VERSION ""

NS_ :

BS_:

BU_: APIM_CISM FCIMB RACM_RCIM DSP WCM DACMC HUD_ADV TRM_ITRM ACM GWM _delete APIM IPC GENERIC TSTR

BO_ 611 Driveline_Data_1_HS3: 8 GWM
 SG_ AwdTerrMdeChng_D_Rdy : 58|3@0+ (1,0) [0|7] "SED"  IPC
 SG_ AwdTerrMde_D_Actl : 50|3@0+ (1,0) [0|7] "SED"  IPC
 SG_ AwdSys_D_Stat : 27|2@0+ (1,0) [0|3] "SED"  IPC
 SG_ AwdStat_D_RqDsply : 63|5@0+ (1,0) [0|31] "SED"  IPC
 SG_ AwdLck_D_Stat : 31|4@0+ (1,0) [0|15] "SED"  IPC
 SG_ AwdSrvcRqd_B_Rq : 0|1@0+ (1,0) [0|1] "SED"  IPC
 SG_ AwdLck_Tq_Rq : 15|12@0+ (1,0) [0|4093] "Nm"  IPC
 SG_ TrnAout_Tq_RqMx : 47|13@0+ (1,-1250) [-1250|6941] "Nm"  IPC
 SG_ AwdOffRoadMode_D_Stats : 25|2@0+ (1,0) [0|3] "SED"  APIM_CISM,APIM,IPC
 SG_ AwdLoLamp_D_RqDsply : 35|2@0+ (1,0) [0|3] "SED"  IPC
 SG_ AwdHiLamp_D_RqDsply : 19|2@0+ (1,0) [0|3] "SED"  IPC
 SG_ AwdAutoLamp_D_RqDsply : 17|2@0+ (1,0) [0|3] "SED"  IPC
 SG_ Awd2wdLamp_D_RqDsply : 2|2@0+ (1,0) [0|3] "SED"  IPC
 SG_ AwdRnge_D_Actl : 7|3@0+ (1,0) [0|7] "SED"  APIM_CISM,ACM,APIM,IPC
 SG_ NtrlTowAvail_B_Stat : 4|1@0+ (1,0) [0|1] "SED"  IPC
 SG_ AwdDrvMde_D_Stat : 38|3@0+ (1,0) [0|7] "SED"  IPC
 SG_ SelDrvMdeAwd_D_Stat : 33|2@0+ (1,0) [0|3] "SED"  GENERIC

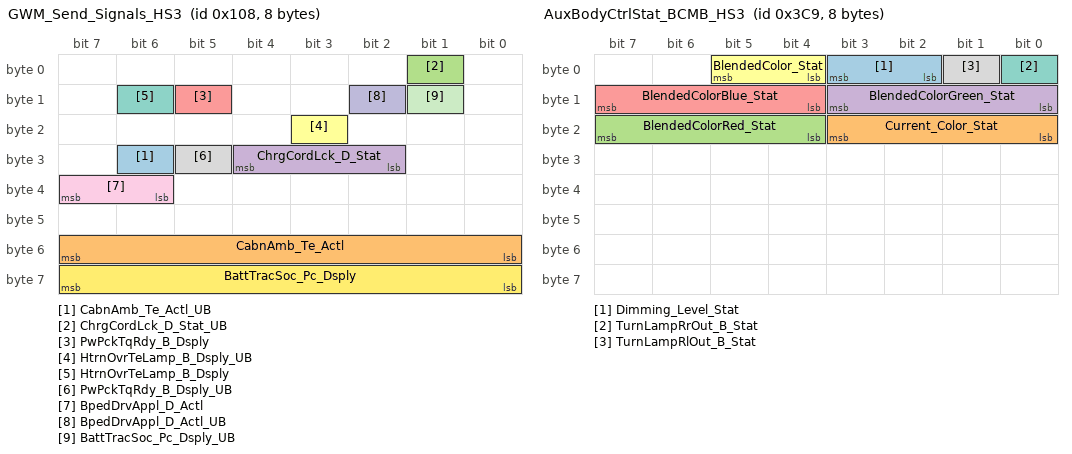
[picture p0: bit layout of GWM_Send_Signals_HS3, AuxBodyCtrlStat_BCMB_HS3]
BO_ 264 GWM_Send_Signals_HS3: 8 GWM
 SG_ CabnAmb_Te_Actl_UB : 30|1@0+ (1,0) [0|1] "SED"  WCM,ACM
 SG_ CabnAmb_Te_Actl : 55|8@0+ (0.5,-57) [-57|70] "degreesC"  WCM,ACM
 SG_ ChrgCordLck_D_Stat_UB : 1|1@0+ (1,0) [0|1] "SED"  APIM_CISM,APIM
 SG_ ChrgCordLck_D_Stat : 28|3@0+ (1,0) [0|7] "SED"  APIM_CISM,APIM
 SG_ PwPckTqRdy_B_Dsply : 13|1@0+ (1,0) [0|1] "SED"  APIM_CISM,APIM,IPC
 SG_ HtrnOvrTeLamp_B_Dsply_UB : 19|1@0+ (1,0) [0|1] "SED"  IPC
 SG_ HtrnOvrTeLamp_B_Dsply : 14|1@0+ (1,0) [0|1] "SED"  IPC
 SG_ PwPckTqRdy_B_Dsply_UB : 29|1@0+ (1,0) [0|1] "SED"  APIM_CISM,APIM,IPC
 SG_ BpedDrvAppl_D_Actl : 39|2@0+ (1,0) [0|3] "SED"  APIM_CISM,APIM,TRM_ITRM,IPC
 SG_ BpedDrvAppl_D_Actl_UB : 10|1@0+ (1,0) [0|1] "SED"  APIM_CISM,APIM,TRM_ITRM,IPC
 SG_ BattTracSoc_Pc_Dsply_UB : 9|1@0+ (1,0) [0|1] "SED"  APIM_CISM,HUD_ADV,APIM,IPC
 SG_ BattTracSoc_Pc_Dsply : 63|8@0+ (0.5,0) [0|126.5] "Percent"  APIM_CISM,HUD_ADV,APIM,IPC

BO_ 1114 TrailerAid_Data: 8 IPC
 SG_ TrailCtlSwtch_B_Stat2 : 16|1@0+ (1,0) [0|1] "SED"  GWM
 SG_ TrlBrkInitOut_D_Rq : 60|2@0+ (1,0) [0|3] "SED"  TRM_ITRM,GWM

BO_ 968 Cluster_Lighting_Rq: 8 IPC
 SG_ RvltnMatchAllw_D_Rq : 58|2@0+ (1,0) [0|3] "SED"  GWM
 SG_ BrkDrvMde_D_Rq : 18|3@0+ (1,0) [0|7] "SED"  GWM
 SG_ LnchCtl_N_Rq : 55|8@0+ (50,0) [0|12750] "rpm"  GWM
 SG_ LnchCtl_D_Rq : 63|2@0+ (1,0) [0|3] "SED"  GWM
 SG_ CurrentColor_CmdGage : 43|4@0+ (1,0) [0|15] "SED"  GWM
 SG_ BlendedColor_CmdGage : 25|2@0+ (1,0) [0|3] "SED"  GWM
 SG_ BlendColorRed_CmdGage : 47|4@0+ (1,0) [0|15] "SED"  GWM
 SG_ BlendColorGrn_CmdGage : 35|4@0+ (1,0) [0|15] "SED"  GWM
 SG_ BlendColorBlue_CmdGage : 39|4@0+ (1,0) [0|15] "SED"  GWM
 SG_ Dimming_Level_Cmd : 1|2@0+ (1,0) [0|3] "SED"  GWM
 SG_ Current_Color_Cmd : 23|4@0+ (1,0) [0|15] "SED"  GWM
 SG_ BlendedColorRed_Cmd : 11|4@0+ (1,0) [0|15] "SED"  GWM
 SG_ BlendedColorGreen_Cmd : 15|4@0+ (1,0) [0|15] "SED"  GWM
 SG_ BlendedColorBlue_Cmd : 5|4@0+ (1,0) [0|15] "SED"  GWM
 SG_ BlendedColor_Cmd : 7|2@0+ (1,0) [0|3] "SED"  GWM
 SG_ SuspDrvMde_D_Rq : 61|3@0+ (1,0) [0|7] "SED"  GWM
 SG_ SlMde_D_Rq : 27|2@0+ (1,0) [0|3] "SED"  GWM
 SG_ IsaOffst_D_Rq : 31|4@0+ (1,0) [0|15] "SED"  GWM

BO_ 969 AuxBodyCtrlStat_BCMB_HS3: 8 GWM
 SG_ Dimming_Level_Stat : 3|2@0+ (1,0) [0|3] "SED"  IPC
 SG_ Current_Color_Stat : 19|4@0+ (1,0) [0|15] "SED"  IPC
 SG_ BlendedColorRed_Stat : 23|4@0+ (1,0) [0|15] "SED"  IPC
 SG_ BlendedColorGreen_Stat : 11|4@0+ (1,0) [0|15] "SED"  IPC
 SG_ BlendedColorBlue_Stat : 15|4@0+ (1,0) [0|15] "SED"  IPC
 SG_ BlendedColor_Stat : 5|2@0+ (1,0) [0|3] "SED"  IPC
 SG_ TurnLampRrOut_B_Stat : 0|1@0+ (1,0) [0|1] "SED"  IPC
 SG_ TurnLampRlOut_B_Stat : 1|1@0+ (1,0) [0|1] "SED"  IPC

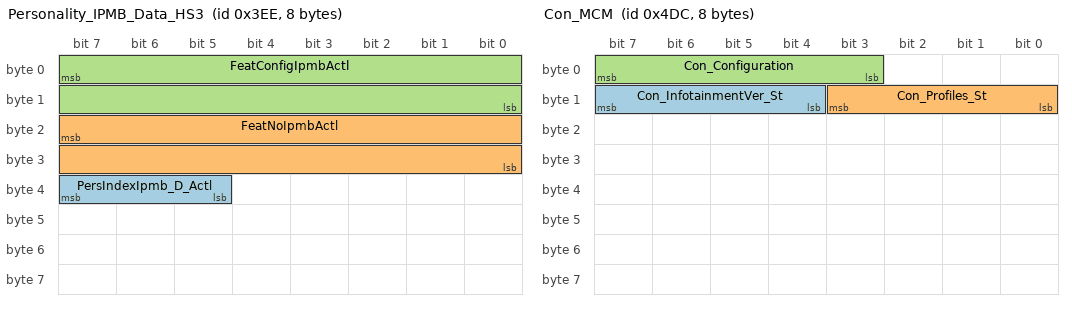
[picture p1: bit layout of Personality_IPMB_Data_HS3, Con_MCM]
BO_ 1006 Personality_IPMB_Data_HS3: 8 GWM
 SG_ PersIndexIpmb_D_Actl : 39|3@0+ (1,0) [0|7] "SED"  APIM_CISM,APIM,ACM
 SG_ FeatNoIpmbActl : 23|16@0+ (1,0) [0|65535] "Number"  APIM_CISM,APIM,ACM
 SG_ FeatConfigIpmbActl : 7|16@0+ (1,0) [0|65535] "Undefined"  APIM_CISM,APIM,ACM

BO_ 130 Steering_Wheel_Data2_HS3: 8 GWM
 SG_ SteWhlSwtchHome_B_Stat : 19|1@0+ (1,0) [0|1] "SED"  IPC
 SG_ SteWhlSwtchInfo_B_Stat : 18|1@0+ (1,0) [0|1] "SED"  IPC
 SG_ SelDrvMdeSwtch_D_Stat4 : 21|2@0+ (1,0) [0|3] "SED"  GENERIC
 SG_ SelDrvMdeSwtch3_D_Stat4 : 25|2@0+ (1,0) [0|3] "SED"  GENERIC
 SG_ SelDrvMdeSwtch2_D_Stat4 : 27|2@0+ (1,0) [0|3] "SED"  GENERIC
 SG_ SelDrvMdeSwtch1_D_Stat4 : 29|2@0+ (1,0) [0|3] "SED"  GENERIC
 SG_ PoliceAux4Swtch_B_Stat : 30|1@0+ (1,0) [0|1] "SED"  TRM_ITRM
 SG_ PoliceAux3Swtch_B_Stat : 31|1@0+ (1,0) [0|1] "SED"  TRM_ITRM
 SG_ PoliceAux2Swtch_B_Stat : 16|1@0+ (1,0) [0|1] "SED"  TRM_ITRM
 SG_ PoliceAux1Swtch_B_Stat : 17|1@0+ (1,0) [0|1] "SED"  TRM_ITRM
 SG_ SteWhlSwtchView_B_Stat : 23|1@0+ (1,0) [0|1] "SED"  IPC
 SG_ SteWhlSwtchSet_B_Stat : 8|1@0+ (1,0) [0|1] "SED"  IPC
 SG_ SteWhlSwtchPhon_B_Stat : 9|1@0+ (1,0) [0|1] "SED"  HUD_ADV,IPC
 SG_ SteWhlSwtchNav_B_Stat : 10|1@0+ (1,0) [0|1] "SED"  IPC
 SG_ SteWhlSwtchMed_B_Stat : 11|1@0+ (1,0) [0|1] "SED"  HUD_ADV,IPC
 SG_ SteWhlSwtchIod_B_Stat : 12|1@0+ (1,0) [0|1] "SED"  IPC
 SG_ SteWhlSwtchHud_B_Stat : 13|1@0+ (1,0) [0|1] "SED"  HUD_ADV,IPC
 SG_ SteWhlSwtchBack_B_Stat : 14|1@0+ (1,0) [0|1] "SED"  HUD_ADV,IPC
 SG_ SteWhlSwtchMenu_B_Stat : 22|1@0+ (1,0) [0|1] "SED"  IPC
 SG_ SteEffortInc_B_RqDrv : 5|1@0+ (1,0) [0|1] "SED"  IPC
 SG_ SelDrvMdeInc_B_RqDrv : 6|1@0+ (1,0) [0|1] "SED"  IPC
 SG_ SelDrvMdeDec_B_RqDrv : 7|1@0+ (1,0) [0|1] "SED"  IPC
 SG_ SuspDampInc_B_RqDrv : 15|1@0+ (1,0) [0|1] "SED"  IPC
 SG_ SteWhlSwtchUp_B_Stat : 3|1@0+ (1,0) [0|1] "SED"  HUD_ADV,IPC
 SG_ SteWhlSwtchRght_B_Stat : 2|1@0+ (1,0) [0|1] "SED"  IPC
 SG_ SteWhlSwtchOk_B_Stat : 4|1@0+ (1,0) [0|1] "SED"  HUD_ADV,IPC
 SG_ SteWhlSwtchLeft_B_Stat : 1|1@0+ (1,0) [0|1] "SED"  IPC
 SG_ SteWhlSwtchDown_B_Stat : 0|1@0+ (1,0) [0|1] "SED"  HUD_ADV,IPC

BO_ 1244 Con_MCM: 8 ACM
 SG_ Con_InfotainmentVer_St : 15|4@0+ (1,0) [0|0] ""  IPC
 SG_ Con_Profiles_St : 11|4@0+ (1,0) [0|0] ""  IPC
 SG_ Con_Configuration : 7|5@0+ (1,0) [0|0] ""  IPC

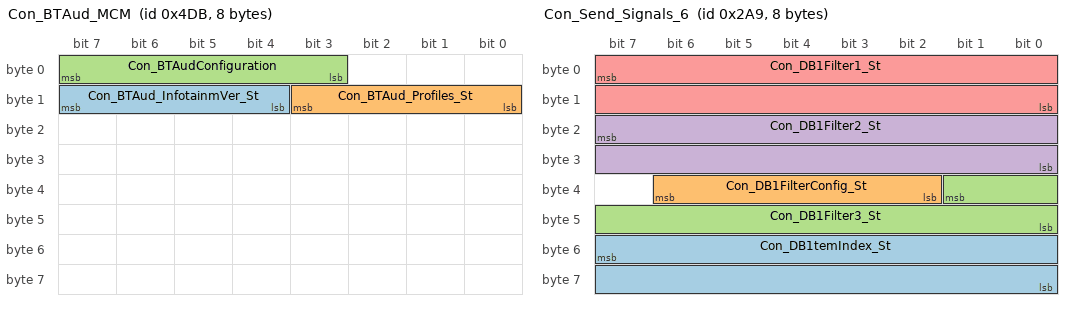
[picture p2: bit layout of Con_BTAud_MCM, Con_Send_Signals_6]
BO_ 1243 Con_BTAud_MCM: 8 ACM
 SG_ Con_BTAud_InfotainmVer_St : 15|4@0+ (1,0) [0|0] ""  IPC
 SG_ Con_BTAud_Profiles_St : 11|4@0+ (1,0) [0|0] ""  IPC
 SG_ Con_BTAudConfiguration : 7|5@0+ (1,0) [0|0] ""  IPC

BO_ 681 Con_Send_Signals_6: 8 ACM
 SG_ Con_DB1temIndex_St : 55|16@0+ (1,0) [0|0] ""  IPC
 SG_ Con_DB1FilterConfig_St : 38|5@0+ (1,0) [0|31] "SED"  IPC
 SG_ Con_DB1Filter3_St : 33|10@0+ (1,0) [0|1023] "unitless"  IPC
 SG_ Con_DB1Filter2_St : 23|16@0+ (1,0) [0|65535] "unitless"  IPC
 SG_ Con_DB1Filter1_St : 7|16@0+ (1,0) [0|65535] "unitless"  IPC

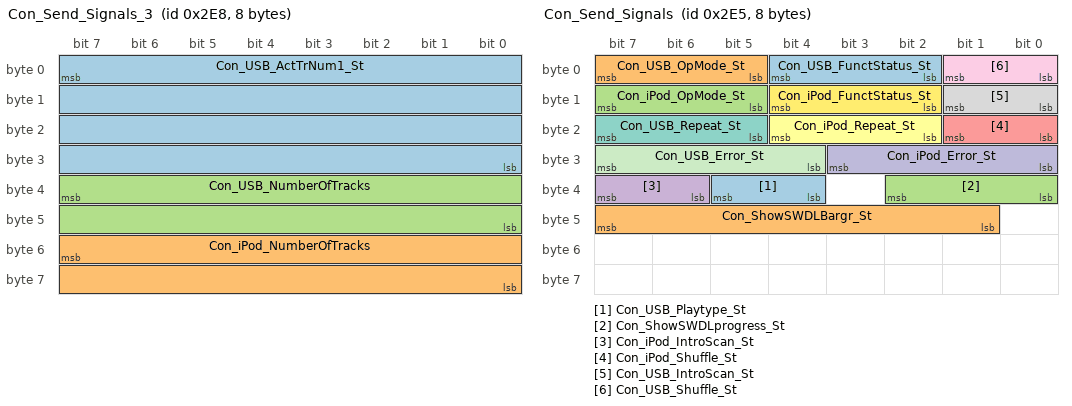
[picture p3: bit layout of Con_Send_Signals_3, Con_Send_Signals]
BO_ 744 Con_Send_Signals_3: 8 ACM
 SG_ Con_USB_ActTrNum1_St : 7|32@0+ (1,0) [0|4294967295] ""  IPC
 SG_ Con_iPod_NumberOfTracks : 55|16@0+ (1,0) [0|65535] ""  IPC
 SG_ Con_USB_NumberOfTracks : 39|16@0+ (1,0) [0|65535] ""  IPC

BO_ 741 Con_Send_Signals: 8 ACM
 SG_ Con_USB_Playtype_St : 37|2@0+ (1,0) [0|3] "SED"  APIM
 SG_ Con_ShowSWDLBargr_St : 47|7@0+ (1,0) [0|127] "unitless"  APIM
 SG_ Con_ShowSWDLprogress_St : 34|3@0+ (1,0) [0|7] "SED"  APIM
 SG_ Con_iPod_IntroScan_St : 39|2@0+ (1,0) [0|3] "SED"  APIM
 SG_ Con_iPod_Shuffle_St : 17|2@0+ (1,0) [0|3] "SED"  APIM
 SG_ Con_iPod_Repeat_St : 20|3@0+ (1,0) [0|7] "SED"  APIM
 SG_ Con_USB_Repeat_St : 23|3@0+ (1,0) [0|7] "SED"  APIM
 SG_ Con_USB_IntroScan_St : 9|2@0+ (1,0) [0|3] "SED"  APIM
 SG_ Con_USB_Shuffle_St : 1|2@0+ (1,0) [0|3] "SED"  APIM
 SG_ Con_iPod_Error_St : 27|4@0+ (1,0) [0|15] "SED"  APIM
 SG_ Con_USB_Error_St : 31|4@0+ (1,0) [0|15] "SED"  APIM
 SG_ Con_iPod_FunctStatus_St : 12|3@0+ (1,0) [0|7] "SED"  APIM
 SG_ Con_USB_FunctStatus_St : 4|3@0+ (1,0) [0|7] "SED"  APIM
 SG_ Con_USB_OpMode_St : 7|3@0+ (1,0) [0|7] "SED"  APIM
 SG_ Con_iPod_OpMode_St : 15|3@0+ (1,0) [0|7] "SED"  APIM

BO_ 954 Body_Info_10_HS3: 8 GWM
 SG_ PosLghtFl_D_Stat : 51|2@0+ (1,0) [0|3] "SED"  GENERIC
 SG_ PosLghtFr_D_Stat : 49|2@0+ (1,0) [0|3] "SED"  GENERIC
 SG_ LoadShedRelayMde_D_Stat : 53|2@0+ (1,0) [0|3] "SED"  GENERIC
 SG_ CargoLght_D_Stat : 55|2@0+ (1,0) [0|3] "SED"  APIM
 SG_ TlghtTestLght_D_Stat : 44|3@0+ (1,0) [0|7] "SED"  APIM
 SG_ LghtAmbDrvMde_B_Stat : 34|1@0+ (1,0) [0|1] "SED"  APIM
 SG_ KeylessIdl_B_Stat : 41|1@0+ (1,0) [0|1] "SED"  APIM
 SG_ PwRnngBoardPoll_D_Stat : 36|2@0+ (1,0) [0|3] "SED"  GENERIC
 SG_ PoliceDmngLvl_D_Stat : 39|3@0+ (1,0) [0|7] "SED"  APIM,IPC,APIM_CISM,GWM
 SG_ TrlrHitchLamp_D_Stat : 25|1@0+ (1,0) [0|1] "SED"  APIM,APIM_CISM
 SG_ LicPlateLght_B_Stat : 26|1@0+ (1,0) [0|1] "SED"  APIM,APIM_CISM
 SG_ TrukBedLght_B_Stat : 24|1@0+ (1,0) [0|1] "SED"  APIM,APIM_CISM
 SG_ VehWlcmFrwlMde_D_Stat : 29|3@0+ (1,0) [0|7] "SED"  APIM,IPC
 SG_ GenericSwtch3_No_Actl : 15|3@0+ (1,0) [0|7] "unitless"  GENERIC
 SG_ GenericSwtch2_No_Actl : 4|3@0+ (1,0) [0|7] "unitless"  GENERIC
 SG_ GenericSwtch1_No_Actl : 7|3@0+ (1,0) [0|7] "unitless"  GENERIC
 SG_ PudSptLghtRight_D_Rq : 17|2@0+ (1,0) [0|3] "SED"  GENERIC
 SG_ PudSptLghtLeft_D_Rq : 19|2@0+ (1,0) [0|3] "SED"  GENERIC
 SG_ ExtLghtRight_D_Stat : 21|2@0+ (1,0) [0|3] "SED"  APIM,APIM_CISM
 SG_ VehWlcmFrwl_D_Stat : 31|2@0+ (1,0) [0|3] "SED"  GENERIC,APIM_CISM,APIM
 SG_ ExtLghtRear_D_Stat : 23|2@0+ (1,0) [0|3] "SED"  APIM,APIM_CISM
 SG_ ExtLghtLeft_D_Stat : 9|2@0+ (1,0) [0|3] "SED"  APIM,APIM_CISM
 SG_ ExtLghtAlrt_B_Rq : 12|1@0+ (1,0) [0|1] "SED"  APIM_CISM,APIM
 SG_ ExtLght_D_Falt : 1|2@0+ (1,0) [0|3] "SED"  APIM_CISM,APIM
 SG_ ExtLghtFront_D_Stat : 11|2@0+ (1,0) [0|3] "SED"  APIM_CISM,APIM
 SG_ TlghtTestPrecnd_D_Stat : 47|3@0+ (1,0) [0|7] "SED"  APIM
 SG_ TlghtTest_D_Stat : 33|2@0+ (1,0) [0|3] "SED"  APIM

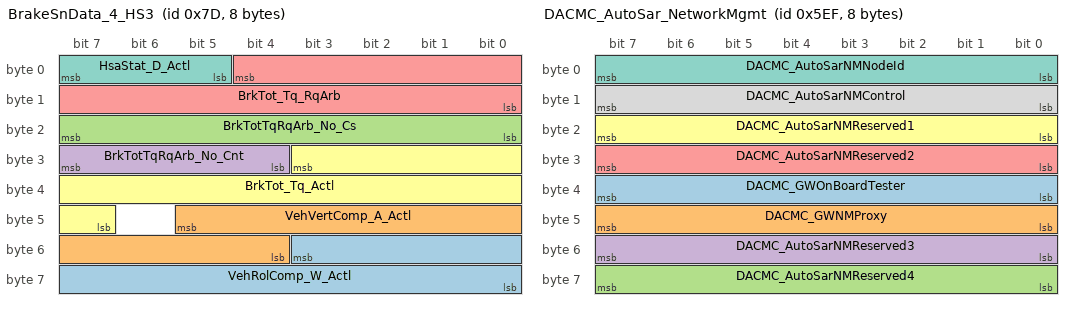
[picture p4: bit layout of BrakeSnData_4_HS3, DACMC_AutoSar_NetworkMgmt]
BO_ 125 BrakeSnData_4_HS3: 8 GWM
 SG_ VehRolComp_W_Actl : 51|12@0+ (0.03663,-75) [-75|74.92659] "degrees/sec"  APIM,APIM_CISM
 SG_ VehVertComp_A_Actl : 45|10@0+ (0.035,-17.9) [-17.9|17.835] "m/s^2"  APIM,APIM_CISM
 SG_ BrkTotTqRqArb_No_Cs : 23|8@0+ (1,0) [0|255] "Unitless"  TRM_ITRM
 SG_ BrkTotTqRqArb_No_Cnt : 31|4@0+ (1,0) [0|15] "Unitless"  TRM_ITRM
 SG_ BrkTot_Tq_RqArb : 4|13@0+ (4,0) [0|32756] "Nm"  TRM_ITRM,APIM_CISM,APIM
 SG_ BrkTot_Tq_Actl : 27|13@0+ (4,0) [0|32756] "Nm"  APIM_CISM,APIM,IPC
 SG_ HsaStat_D_Actl : 7|3@0+ (1,0) [0|7] "SED"  IPC

BO_ 2612224096 PARSEDPushIPCtoGWM_ECG: 8 IPC
 SG_ PARSEDPushIPCtoGWM_ECG : 7|29@0+ (1,0) [0|536870911] "unitless"  GWM

BO_ 2611052760 PARSEDPhysGWM_ECGtoIPC: 8 GWM
 SG_ PARSEDPhysGWM_ECGtoIPC : 7|29@0+ (1,0) [0|536870911] "unitless"  IPC

BO_ 2611175520 PARSEDPhysIPCtoGWM_ECG: 8 IPC
 SG_ PARSEDPhysIPCtoGWM_ECG : 7|29@0+ (1,0) [0|536870911] "unitless"  GWM

BO_ 2610126944 OTAPhysIPCtoGWM_ECG: 8 IPC
 SG_ OTAPhysIPCtoGWM_ECG : 7|29@0+ (1,0) [0|536870911] "unitless"  GWM

BO_ 2610004184 OTAPhysGWM_ECGtoIPC: 8 GWM
 SG_ OTAPhysGWM_ECGtoIPC : 7|29@0+ (1,0) [0|536870911] "unitless"  IPC

BO_ 2005 TesterPhysicalReqDACMC: 8 TSTR
 SG_ TesterPhysicalReqDACMC : 7|64@0+ (1,0) [0|1.84467E+019] "unitless"  DACMC

BO_ 2013 TesterPhysicalResDACMC: 8 DACMC
 SG_ TesterPhysicalResDACMC : 7|64@0+ (1,0) [0|1.84467E+019] "unitless"  TSTR

BO_ 1519 DACMC_AutoSar_NetworkMgmt: 8 DACMC
 SG_ DACMC_GWOnBoardTester : 39|8@0+ (1,0) [0|255] "unitless"  GWM
 SG_ DACMC_GWNMProxy : 47|8@0+ (1,0) [0|255] "unitless"  GWM
 SG_ DACMC_AutoSarNMReserved4 : 63|8@0+ (1,0) [0|255] "unitless"  GWM
 SG_ DACMC_AutoSarNMReserved3 : 55|8@0+ (1,0) [0|255] "unitless"  GWM
 SG_ DACMC_AutoSarNMReserved2 : 31|8@0+ (1,0) [0|255] "unitless"  GWM
 SG_ DACMC_AutoSarNMReserved1 : 23|8@0+ (1,0) [0|255] "unitless"  GWM
 SG_ DACMC_AutoSarNMNodeId : 7|8@0+ (1,0) [0|255] "unitless"  GWM
 SG_ DACMC_AutoSarNMControl : 15|8@0+ (1,0) [0|255] "unitless"  GWM

BO_ 2612002008 PARSEDFuncGWM_ECG_HS3: 8 GWM
 SG_ PARSEDFuncGWM_ECG : 7|29@0+ (1,0) [0|536870911] "unitless"  WCM,IPC

BO_ 2610953432 OTAFuncGWM_ECG_HS3: 8 GWM
 SG_ OTAFuncGWM_ECG : 7|29@0+ (1,0) [0|536870911] "unitless"  IPC,WCM

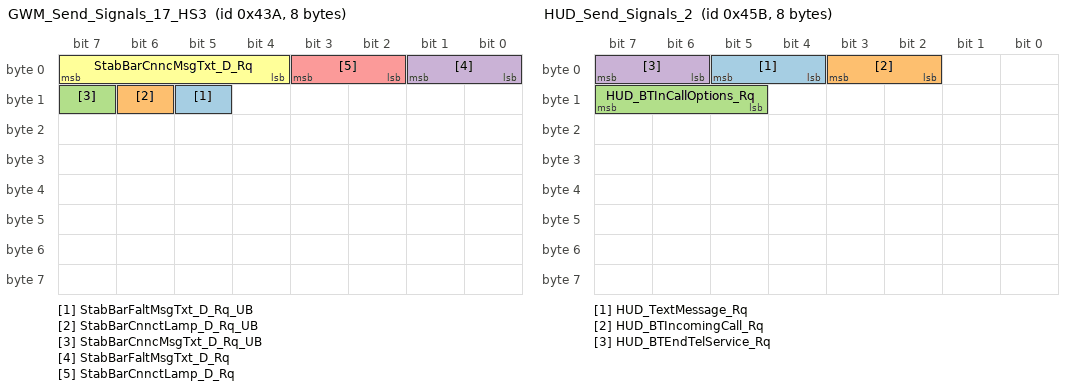
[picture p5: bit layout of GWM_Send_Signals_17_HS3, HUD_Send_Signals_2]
BO_ 1082 GWM_Send_Signals_17_HS3: 8 GWM
 SG_ StabBarFaltMsgTxt_D_Rq_UB : 13|1@0+ (1,0) [0|1] "SED"  IPC
 SG_ StabBarCnnctLamp_D_Rq_UB : 14|1@0+ (1,0) [0|1] "SED"  APIM_CISM,IPC,APIM
 SG_ StabBarCnncMsgTxt_D_Rq_UB : 15|1@0+ (1,0) [0|1] "SED"  IPC
 SG_ StabBarFaltMsgTxt_D_Rq : 1|2@0+ (1,0) [0|3] "SED"  IPC
 SG_ StabBarCnnctLamp_D_Rq : 3|2@0+ (1,0) [0|3] "SED"  APIM_CISM,IPC,APIM
 SG_ StabBarCnncMsgTxt_D_Rq : 7|4@0+ (1,0) [0|15] "SED"  IPC

BO_ 576 AUDIO_RDISP2_WORD_Tx: 8 ACM
 SG_ AUDIO_RDISP2_WORD_Tx : 7|64@0+ (1,0) [0|1.84467440737096E+019] "unitless"  HUD_ADV

BO_ 1115 HUD_Send_Signals_2: 8 HUD_ADV
 SG_ HUD_TextMessage_Rq : 5|2@0+ (1,0) [0|3] "SED"  APIM_CISM,APIM
 SG_ HUD_BTIncomingCall_Rq : 3|2@0+ (1,0) [0|3] "SED"  APIM_CISM,APIM
 SG_ HUD_BTInCallOptions_Rq : 15|3@0+ (1,0) [0|7] "SED"  APIM_CISM,APIM
 SG_ HUD_BTEndTelService_Rq : 7|2@0+ (1,0) [0|3] "SED"  APIM_CISM,APIM

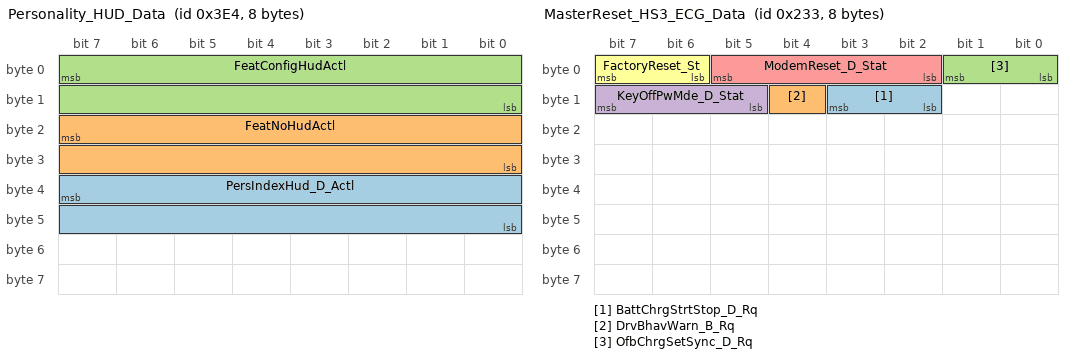
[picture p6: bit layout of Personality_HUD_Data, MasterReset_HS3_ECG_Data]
BO_ 996 Personality_HUD_Data: 8 HUD_ADV
 SG_ PersIndexHud_D_Actl : 39|16@0+ (1,0) [0|65535] "Unitless"  IPC
 SG_ FeatNoHudActl : 23|16@0+ (1,0) [0|65535] "Unitless"  IPC
 SG_ FeatConfigHudActl : 7|16@0+ (1,0) [0|65535] "Unitless"  IPC

BO_ 588 RDRV_RDISP2_WORD_Rx: 8 HUD_ADV
 SG_ RDRV_RDISP2_WORD_Rx : 7|64@0+ (1,0) [0|1.84467440737096E+019] "unitless"  GENERIC

BO_ 811 APIM_Data: 8 APIM
 SG_ ExtLghtDsply_D_Stat : 7|3@0+ (1,0) [0|7] "SED"  GWM
 SG_ SpeedoMajorUnit_D_Confg : 59|2@0+ (1,0) [0|3] "SED"  GWM
 SG_ ScMnSoc_Pc_RqMnu : 55|7@0+ (1,0) [0|125] "percent"  GWM
 SG_ ScEnbl_D_RqMnu : 57|2@0+ (1,0) [0|3] "SED"  GWM
 SG_ OnePdlDrvButtn_B_Falt : 16|1@0+ (1,0) [0|1] "SED"  GWM
 SG_ OnePdlDrvButtn_B_Stat : 48|1@0+ (1,0) [0|1] "SED"  GWM
 SG_ LongTermReset_B_RqMnu : 17|1@0+ (1,0) [0|1] "SED"  GWM
 SG_ DistToStopover_L_Actl : 31|16@0+ (0.1,0) [0|6553.4] "kilometer"  IPC,GWM
 SG_ StopoverType_D_Stat : 47|3@0+ (1,0) [0|0] "SED"  IPC,GWM
 SG_ ExtLghtRight_D_RqMnu : 11|3@0+ (1,0) [0|7] "SED"  GWM
 SG_ AutoLghtOvrrd_B_RqDrv : 8|1@0+ (1,0) [0|1] "SED"  GWM
 SG_ ExtLghtRear_D_RqMnu : 14|3@0+ (1,0) [0|7] "SED"  GWM
 SG_ ExtLghtLeft_D_RqMnu : 1|3@0+ (1,0) [0|7] "SED"  GWM
 SG_ ExtLghtFront_D_RqMnu : 4|3@0+ (1,0) [0|7] "SED"  GWM
 SG_ BecRleas_No_RqMnu : 23|3@0+ (1,0) [0|7] "unitless"  GWM
 SG_ TrnkFrontRleas_No_RqMnu : 20|3@0+ (1,0) [0|7] "unitless"  GWM
 SG_ GoTEditMnte_T_RqMnu : 63|4@0+ (1,0) [0|15] "SED"  GWM
 SG_ GoTEditHr_T_RqMnu : 44|5@0+ (1,0) [0|29] "SED"  GWM

BO_ 543 TelTaleData: 8 IPC
 SG_ TeltalWarnData_No_Actl : 7|64@0+ (1,0) [0|1.84467E+019] "unitless"  APIM,GWM,APIM_CISM

BO_ 563 MasterReset_HS3_ECG_Data: 8 GWM
 SG_ BattChrgStrtStop_D_Rq : 11|2@0+ (1,0) [0|3] "SED"  GENERIC
 SG_ DrvBhavWarn_B_Rq : 12|1@0+ (1,0) [0|1] "SED"  IPC
 SG_ OfbChrgSetSync_D_Rq : 1|2@0+ (1,0) [0|3] "SED"  APIM,APIM_CISM
 SG_ KeyOffPwMde_D_Stat : 15|3@0+ (1,0) [0|7] "SED"  APIM_CISM,APIM
 SG_ ModemReset_D_Stat : 5|4@0+ (1,0) [0|15] "SED"  APIM_CISM,ACM,APIM
 SG_ FactoryReset_St : 7|2@0+ (1,0) [0|3] "SED"  APIM_CISM,ACM,APIM

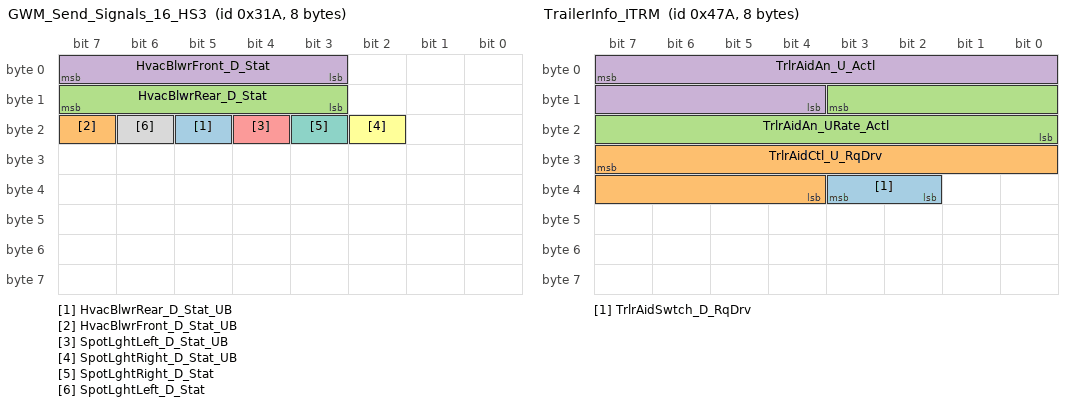
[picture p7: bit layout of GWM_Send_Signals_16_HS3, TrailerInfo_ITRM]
BO_ 794 GWM_Send_Signals_16_HS3: 8 GWM
 SG_ HvacBlwrRear_D_Stat_UB : 21|1@0+ (1,0) [0|1] "SED"  WCM
 SG_ HvacBlwrFront_D_Stat_UB : 23|1@0+ (1,0) [0|1] "SED"  WCM
 SG_ HvacBlwrRear_D_Stat : 15|5@0+ (1,0) [0|31] "SED"  WCM
 SG_ HvacBlwrFront_D_Stat : 7|5@0+ (1,0) [0|31] "SED"  WCM
 SG_ SpotLghtLeft_D_Stat_UB : 20|1@0+ (1,0) [0|1] "SED"  APIM,APIM_CISM
 SG_ SpotLghtRight_D_Stat_UB : 18|1@0+ (1,0) [0|1] "SED"  APIM,APIM_CISM
 SG_ SpotLghtRight_D_Stat : 19|1@0+ (1,0) [0|1] "SED"  APIM,APIM_CISM
 SG_ SpotLghtLeft_D_Stat : 22|1@0+ (1,0) [0|1] "SED"  APIM_CISM,APIM

BO_ 587 PHONE_RDISP2_WORD_Rx: 8 HUD_ADV
 SG_ PHONE_RDISP2_WORD_Rx : 7|64@0+ (1,0) [0|1.84467440737096E+019] "unitless"  APIM_CISM,ACM,APIM

BO_ 579 PHONE_RDISP2_WORD_Tx: 8 APIM
 SG_ PHONE_RDISP2_WORD_Tx : 7|64@0+ (1,0) [0|1.84467440737096E+019] "unitless"  HUD_ADV

BO_ 585 NAV_RDISP2_WORD_Rx: 8 HUD_ADV
 SG_ NAV_RDISP2_WORD_Rx : 7|64@0+ (1,0) [0|1.84467440737096E+019] "unitless"  APIM_CISM,APIM

BO_ 586 CONMP_RDISP2_WORD_Rx: 8 HUD_ADV
 SG_ CONMP_RDISP2_WORD_Rx : 7|64@0+ (1,0) [0|1.84467440737096E+019] "unitless"  APIM_CISM,APIM

BO_ 578 CONMP_RDISP2_WORD_Tx: 8 APIM
 SG_ CONMP_RDISP2_WORD_Tx : 7|64@0+ (1,0) [0|1.84467440737096E+019] "unitless"  APIM_CISM,HUD_ADV

BO_ 577 NAV_RDISP2_WORD_Tx: 8 APIM
 SG_ NAV_RDISP2_WORD_Tx : 7|64@0+ (1,0) [0|1.84467440737096E+019] "unitless"  HUD_ADV

BO_ 712 NAV_MC_WORD_Rx: 8 IPC
 SG_ NAV_MC_WORD_Rx : 7|64@0+ (1,0) [0|1.84467440737096E+019] "unitless"  APIM_CISM,APIM

BO_ 717 DSPAMP_RDISP_WORD_Rx: 8 APIM
 SG_ DSPAMP_RDISP_WORD_Rx : 7|64@0+ (1,0) [0|1.84467440737096E+019] "unitless"  DSP

BO_ 719 MyKeySrvr_Clnt_Word_Rx: 8 APIM
 SG_ MyKeySrvr_Clnt_Word_Rx : 7|64@0+ (1,0) [0|1.84467440737096E+019] "unitless"  IPC

BO_ 589 TRAFFIC_RDISP_WORD_Rx: 8 APIM
 SG_ TRAFFIC_RDISP_WORD_Rx : 7|64@0+ (1,0) [0|1.84467440737096E+019] "unitless"  GWM

BO_ 1879 TesterPhysicalReqTBM_HS3: 8 TSTR
 SG_ TesterPhysicalReqTBM_HS3 : 7|64@0+ (1,0) [0|1.84467E+019] "unitless"  TRM_ITRM

BO_ 1887 TesterPhysicalResTBM_HS3: 8 TRM_ITRM
 SG_ TesterPhysicalResTBM_HS3 : 7|64@0+ (1,0) [0|1.84467E+019] "unitless"  TSTR

BO_ 1146 TrailerInfo_ITRM: 8 TRM_ITRM
 SG_ TrlrAidSwtch_D_RqDrv : 35|2@0+ (1,0) [0|3] "SED"  GWM
 SG_ TrlrAidCtl_U_RqDrv : 31|12@0+ (0.00125,0) [0|5.11625] "volt"  GWM
 SG_ TrlrAidAn_URate_Actl : 11|12@0+ (0.00125,-2.5) [-2.5|2.61625] "volt/sec"  GWM
 SG_ TrlrAidAn_U_Actl : 7|12@0+ (0.00125,0) [0|5.11625] "volt"  GWM

BO_ 737 APIM_ECG_Word_Tx: 8 APIM
 SG_ APIM_ECG_Word_Tx : 7|64@0+ (1,0) [0|1.84467440737096E+019] "unitless"  GWM

BO_ 745 ECG_APIM_Word_Tx: 8 GWM
 SG_ ECG_APIM_Word_Tx : 7|64@0+ (1,0) [0|1.84467440737096E+019] "unitless"  APIM_CISM,APIM

BO_ 1195 TCU_RDISP2_WORD_Rx: 8 HUD_ADV
 SG_ TCU_RDISP2_WORD_Rx : 7|64@0+ (1,0) [0|1.84467440737096E+019] "unitless"  GWM

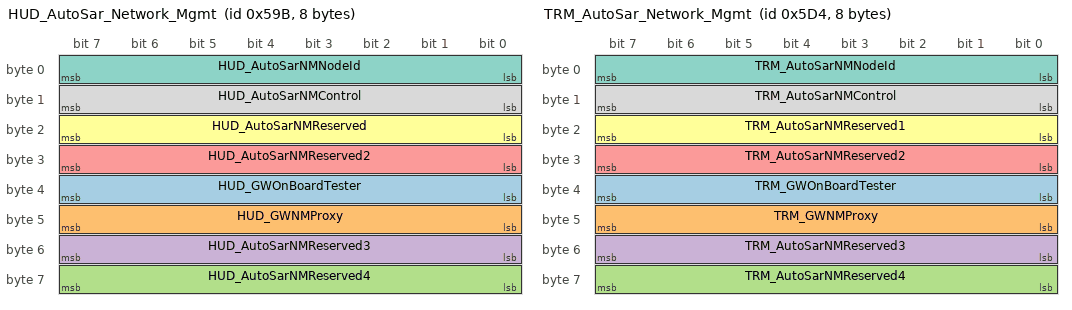
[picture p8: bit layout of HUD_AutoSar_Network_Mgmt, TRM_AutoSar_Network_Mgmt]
BO_ 1435 HUD_AutoSar_Network_Mgmt: 8 HUD_ADV
 SG_ HUD_GWOnBoardTester : 39|8@0+ (1,0) [0|255] "unitless"  GWM
 SG_ HUD_GWNMProxy : 47|8@0+ (1,0) [0|255] "unitless"  GWM
 SG_ HUD_AutoSarNMReserved4 : 63|8@0+ (1,0) [0|255] "unitless"  GWM
 SG_ HUD_AutoSarNMReserved3 : 55|8@0+ (1,0) [0|255] "unitless"  GWM
 SG_ HUD_AutoSarNMReserved2 : 31|8@0+ (1,0) [0|255] "unitless"  GWM
 SG_ HUD_AutoSarNMReserved : 23|8@0+ (1,0) [0|255] "unitless"  GWM
 SG_ HUD_AutoSarNMNodeId : 7|8@0+ (1,0) [0|255] "unitless"  GWM
 SG_ HUD_AutoSarNMControl : 15|8@0+ (1,0) [0|255] "unitless"  GWM

BO_ 1109 eCall_Info: 8 APIM
 SG_ eCallConfirmation : 7|3@0+ (1,0) [0|7] "SED"  GWM

BO_ 1492 TRM_AutoSar_Network_Mgmt: 8 TRM_ITRM
 SG_ TRM_GWOnBoardTester : 39|8@0+ (1,0) [0|255] "unitless"  GWM
 SG_ TRM_GWNMProxy : 47|8@0+ (1,0) [0|255] "unitless"  GWM
 SG_ TRM_AutoSarNMReserved4 : 63|8@0+ (1,0) [0|255] "unitless"  GWM
 SG_ TRM_AutoSarNMReserved3 : 55|8@0+ (1,0) [0|255] "unitless"  GWM
 SG_ TRM_AutoSarNMReserved2 : 31|8@0+ (1,0) [0|255] "unitless"  GWM
 SG_ TRM_AutoSarNMReserved1 : 23|8@0+ (1,0) [0|255] "unitless"  GWM
 SG_ TRM_AutoSarNMNodeId : 7|8@0+ (1,0) [0|255] "unitless"  GWM
 SG_ TRM_AutoSarNMControl : 15|8@0+ (1,0) [0|255] "unitless"  GWM

BO_ 1945 TesterPhysicalResTRM_ITRM: 8 TRM_ITRM
 SG_ TesterPhysicalResTRM_ITRM : 7|64@0+ (1,0) [0|1.84467E+019] "unitless"  TSTR

BO_ 1937 TesterPhysicalReqTRM_ITRM: 8 TSTR
 SG_ TesterPhysicalReqTRM_ITRM : 7|64@0+ (1,0) [0|1.84467E+019] "unitless"  TRM_ITRM

BO_ 140 CruiseCtrl_StrgData2: 8 IPC
 SG_ CcAslButtnIndxIncPress2 : 18|1@0+ (1,0) [0|1] "SED"  GWM
 SG_ SteWhlSwtchMde_D_Stat : 23|2@0+ (1,0) [0|3] "SED"  GWM
 SG_ CcAslButtnOffCnclPress2 : 17|1@0+ (1,0) [0|1] "SED"  GWM
 SG_ CcAslButtnIndxDecPress2 : 19|1@0+ (1,0) [0|1] "SED"  GWM
 SG_ CcAslButtnCnclResPress2 : 21|1@0+ (1,0) [0|1] "SED"  GWM
 SG_ CcAslButtnResIncPress3 : 29|1@0+ (1,0) [0|1] "SED"  GWM
 SG_ CcButtnOnPress3 : 37|1@0+ (1,0) [0|1] "SED"  GWM
 SG_ CcButtnOnOffPress3 : 38|1@0+ (1,0) [0|1] "SED"  GWM
 SG_ CcButtnOnOffCnclPress3 : 39|1@0+ (1,0) [0|1] "SED"  GWM
 SG_ CcButtnOffPress3 : 24|1@0+ (1,0) [0|1] "SED"  GWM
 SG_ CcAsllButtnResPress3 : 25|1@0+ (1,0) [0|1] "SED"  GWM
 SG_ CcAslButtnSetPress3 : 26|1@0+ (1,0) [0|1] "SED"  GWM
 SG_ CcAslButtnSetIncPress3 : 27|1@0+ (1,0) [0|1] "SED"  GWM
 SG_ CcAslButtnSetDecPress3 : 28|1@0+ (1,0) [0|1] "SED"  GWM
 SG_ CcAslButtnResDecPress3 : 30|1@0+ (1,0) [0|1] "SED"  GWM
 SG_ CcAslButtnOnPress3 : 31|1@0+ (1,0) [0|1] "SED"  GWM
 SG_ CcAslButtnOnOffCncl3 : 16|1@0+ (1,0) [0|1] "SED"  GWM
 SG_ CcAslButtnDeny_B_Actl3 : 20|1@0+ (1,0) [0|1] "SED"  GWM
 SG_ CcAslButtnCnclPress3 : 8|1@0+ (1,0) [0|1] "SED"  GWM
 SG_ AslButtnOnOffPress3 : 9|1@0+ (1,0) [0|1] "SED"  GWM
 SG_ AslButtnOnOffCnclPress2 : 10|1@0+ (1,0) [0|1] "SED"  GWM

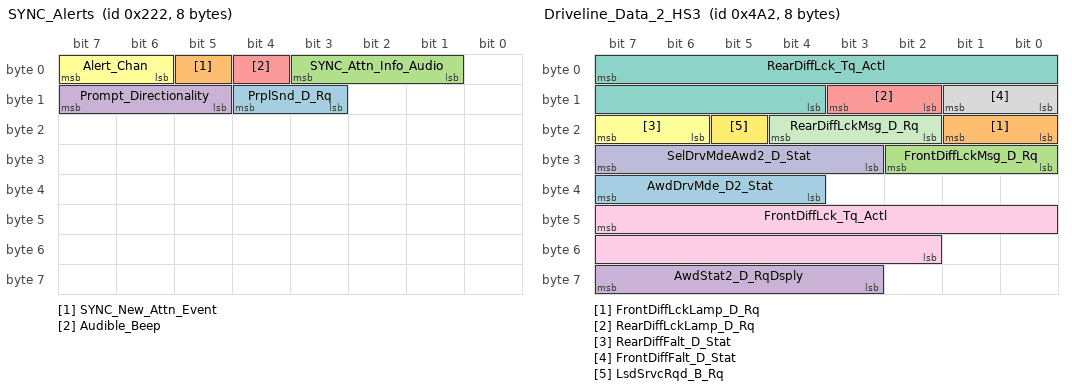
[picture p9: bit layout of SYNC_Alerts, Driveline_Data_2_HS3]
BO_ 546 SYNC_Alerts: 8 APIM
 SG_ PrplSnd_D_Rq : 12|2@0+ (1,0) [0|3] "SED"  ACM
 SG_ SYNC_New_Attn_Event : 5|1@0+ (1,0) [0|1] "SED"  ACM,DSP
 SG_ SYNC_Attn_Info_Audio : 3|3@0+ (1,0) [0|7] "SED"  ACM,DSP
 SG_ Prompt_Directionality : 15|3@0+ (1,0) [0|7] "SED"  ACM,DSP
 SG_ Audible_Beep : 4|1@0+ (1,0) [0|1] "SED"  ACM,DSP
 SG_ Alert_Chan : 7|2@0+ (1,0) [0|3] "SED"  RACM_RCIM,ACM,DSP

BO_ 1186 Driveline_Data_2_HS3: 8 GWM
 SG_ AwdDrvMde_D2_Stat : 39|4@0+ (1,0) [0|15] "SED"  IPC
 SG_ FrontDiffLckLamp_D_Rq : 17|2@0+ (1,0) [0|3] "SED"  IPC,APIM
 SG_ FrontDiffLckMsg_D_Rq : 26|3@0+ (1,0) [0|7] "SED"  IPC
 SG_ AwdStat2_D_RqDsply : 63|5@0+ (1,0) [0|31] "SED"  IPC
 SG_ RearDiffLckLamp_D_Rq : 11|2@0+ (1,0) [0|3] "SED"  ACM,APIM,IPC
 SG_ RearDiffFalt_D_Stat : 23|2@0+ (1,0) [0|3] "SED" Vector__XXX
 SG_ RearDiffLck_Tq_Actl : 7|12@0+ (1,0) [0|4093] "Nm" Vector__XXX
 SG_ FrontDiffFalt_D_Stat : 9|2@0+ (1,0) [0|3] "SED"  GENERIC
 SG_ FrontDiffLck_Tq_Actl : 47|14@0+ (1,0) [0|16381] "Nm"  GENERIC
 SG_ SelDrvMdeAwd2_D_Stat : 31|5@0+ (1,0) [0|31] "SED"  GENERIC
 SG_ RearDiffLckMsg_D_Rq : 20|3@0+ (1,0) [0|7] "SED"  IPC
 SG_ LsdSrvcRqd_B_Rq : 21|1@0+ (1,0) [0|1] "SED"  IPC

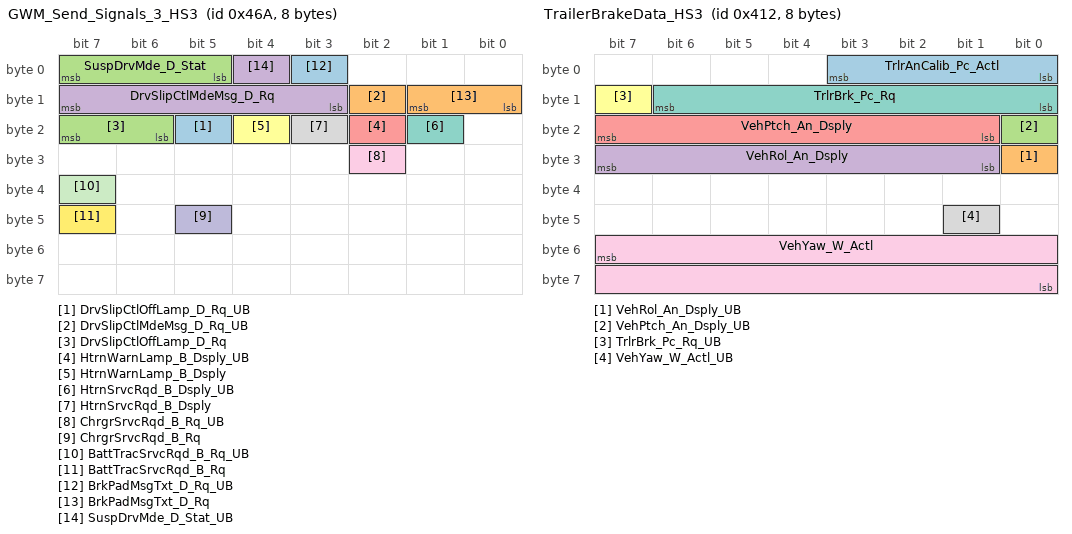
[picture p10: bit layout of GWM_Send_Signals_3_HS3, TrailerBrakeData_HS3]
BO_ 1130 GWM_Send_Signals_3_HS3: 8 GWM
 SG_ DrvSlipCtlOffLamp_D_Rq_UB : 21|1@0+ (1,0) [0|1] "SED"  IPC
 SG_ DrvSlipCtlMdeMsg_D_Rq_UB : 10|1@0+ (1,0) [0|1] "SED"  IPC
 SG_ DrvSlipCtlOffLamp_D_Rq : 23|2@0+ (1,0) [0|3] "SED"  IPC
 SG_ DrvSlipCtlMdeMsg_D_Rq : 15|5@0+ (1,0) [0|31] "SED"  IPC
 SG_ HtrnWarnLamp_B_Dsply_UB : 18|1@0+ (1,0) [0|1] "SED"  IPC
 SG_ HtrnWarnLamp_B_Dsply : 20|1@0+ (1,0) [0|1] "SED"  IPC
 SG_ HtrnSrvcRqd_B_Dsply_UB : 17|1@0+ (1,0) [0|1] "SED"  IPC
 SG_ HtrnSrvcRqd_B_Dsply : 19|1@0+ (1,0) [0|1] "SED"  IPC
 SG_ ChrgrSrvcRqd_B_Rq_UB : 26|1@0+ (1,0) [0|1] "SED"  IPC
 SG_ ChrgrSrvcRqd_B_Rq : 45|1@0+ (1,0) [0|1] "SED"  IPC
 SG_ BattTracSrvcRqd_B_Rq_UB : 39|1@0+ (1,0) [0|1] "SED"  IPC
 SG_ BattTracSrvcRqd_B_Rq : 47|1@0+ (1,0) [0|1] "SED"  IPC
 SG_ BrkPadMsgTxt_D_Rq_UB : 3|1@0+ (1,0) [0|1] "SED"  IPC
 SG_ BrkPadMsgTxt_D_Rq : 9|2@0+ (1,0) [0|3] "SED"  IPC
 SG_ SuspDrvMde_D_Stat : 7|3@0+ (1,0) [0|7] "SED"  IPC
 SG_ SuspDrvMde_D_Stat_UB : 4|1@0+ (1,0) [0|1] "SED"  IPC

BO_ 1042 TrailerBrakeData_HS3: 8 GWM
 SG_ TrlrAnCalib_Pc_Actl : 3|4@0+ (10,0) [0|140] "percent"  IPC
 SG_ VehRol_An_Dsply_UB : 24|1@0+ (1,0) [0|1] "SED"  APIM_CISM,APIM,IPC
 SG_ VehPtch_An_Dsply_UB : 16|1@0+ (1,0) [0|1] "SED"  APIM_CISM,APIM,IPC
 SG_ VehRol_An_Dsply : 31|7@0+ (1,-64) [-64|61] "degrees"  APIM_CISM,APIM,IPC
 SG_ VehPtch_An_Dsply : 23|7@0+ (1,-64) [-64|61] "degrees"  APIM_CISM,APIM,IPC
 SG_ TrlrBrk_Pc_Rq_UB : 15|1@0+ (1,0) [0|1] "SED"  TRM_ITRM,IPC
 SG_ TrlrBrk_Pc_Rq : 14|7@0+ (1,0) [0|127] "percent"  TRM_ITRM,IPC
 SG_ VehYaw_W_Actl_UB : 41|1@0+ (1,0) [0|1] "SED"  APIM_CISM,ACM,APIM
 SG_ VehYaw_W_Actl : 55|16@0+ (0.0002,-6.5) [-6.5|6.6066] "rad/s"  APIM_CISM,ACM,APIM

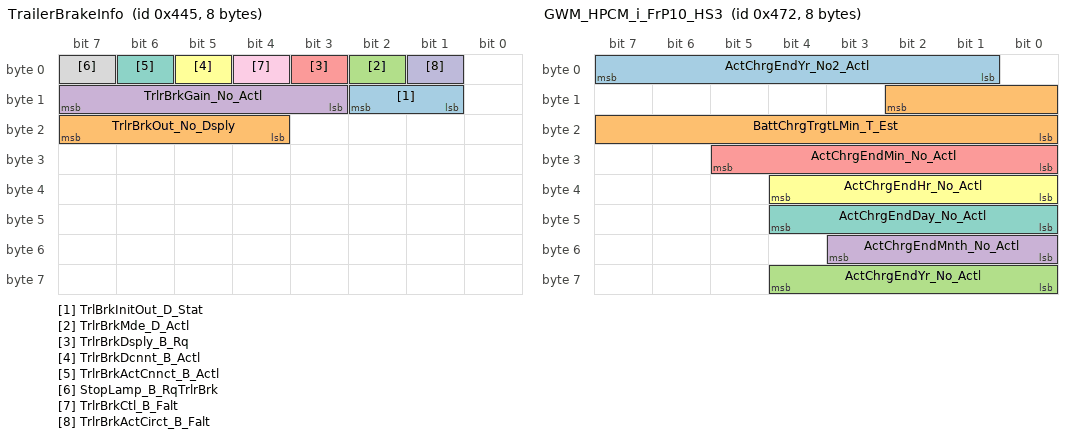
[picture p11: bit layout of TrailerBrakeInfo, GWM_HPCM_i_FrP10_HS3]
BO_ 1093 TrailerBrakeInfo: 8 TRM_ITRM
 SG_ TrlBrkInitOut_D_Stat : 10|2@0+ (1,0) [0|3] "SED"  GWM,IPC
 SG_ TrlrBrkOut_No_Dsply : 23|4@0+ (1,0) [0|15] "unitless"  GWM,IPC
 SG_ TrlrBrkMde_D_Actl : 2|1@0+ (1,0) [0|1] "SED"  GWM,IPC
 SG_ TrlrBrkGain_No_Actl : 15|5@0+ (0.5,0) [0|15.5] "unitless"  APIM_CISM,APIM,GWM,IPC
 SG_ TrlrBrkDsply_B_Rq : 3|1@0+ (1,0) [0|1] "SED"  GWM,IPC
 SG_ TrlrBrkDcnnt_B_Actl : 5|1@0+ (1,0) [0|1] "SED"  GWM,IPC
 SG_ TrlrBrkActCnnct_B_Actl : 6|1@0+ (1,0) [0|1] "SED"  APIM,APIM_CISM,GWM,IPC
 SG_ StopLamp_B_RqTrlrBrk : 7|1@0+ (1,0) [0|1] "SED"  GWM
 SG_ TrlrBrkCtl_B_Falt : 4|1@0+ (1,0) [0|1] "SED"  GWM,IPC
 SG_ TrlrBrkActCirct_B_Falt : 1|1@0+ (1,0) [0|1] "SED"  GWM,IPC

BO_ 1138 GWM_HPCM_i_FrP10_HS3: 8 GWM
 SG_ ActChrgEndYr_No2_Actl : 7|7@0+ (1,2017) [2017|2144] "year"  APIM_CISM,APIM,IPC
 SG_ BattChrgTrgtLMin_T_Est : 10|11@0+ (1,0) [0|2045] "minute"  APIM_CISM,APIM
 SG_ ActChrgEndYr_No_Actl : 60|5@0+ (1,2010) [2010|2040] "year"  IPC,APIM_CISM,APIM
 SG_ ActChrgEndMnth_No_Actl : 51|4@0+ (1,1) [1|15] "month"  IPC,APIM_CISM,APIM
 SG_ ActChrgEndMin_No_Actl : 29|6@0+ (1,0) [0|61] "minute"  IPC,APIM_CISM,APIM
 SG_ ActChrgEndHr_No_Actl : 36|5@0+ (1,0) [0|29] "hour"  IPC,APIM_CISM,APIM
 SG_ ActChrgEndDay_No_Actl : 44|5@0+ (1,1) [1|31] "days"  IPC,APIM_CISM,APIM

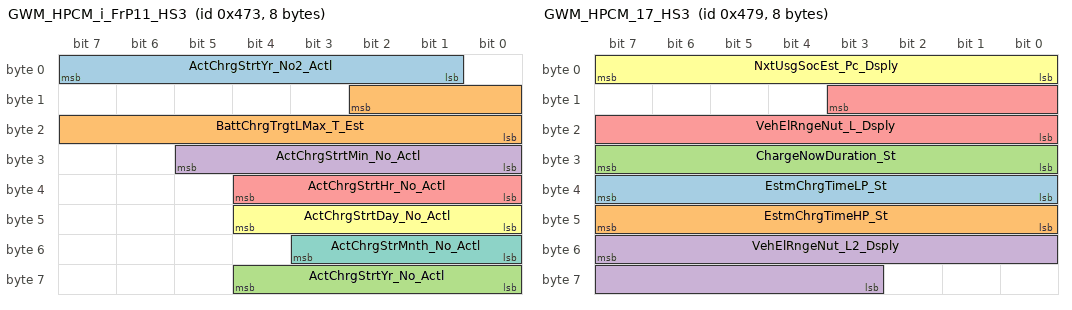
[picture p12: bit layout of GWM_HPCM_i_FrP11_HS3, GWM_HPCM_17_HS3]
BO_ 1139 GWM_HPCM_i_FrP11_HS3: 8 GWM
 SG_ ActChrgStrtYr_No2_Actl : 7|7@0+ (1,2017) [2017|2144] "year"  APIM_CISM,APIM,IPC
 SG_ BattChrgTrgtLMax_T_Est : 10|11@0+ (1,0) [0|2045] "minute"  APIM_CISM,APIM
 SG_ ActChrgStrtYr_No_Actl : 60|5@0+ (1,2010) [2010|2040] "year"  IPC,APIM_CISM,APIM
 SG_ ActChrgStrtMin_No_Actl : 29|6@0+ (1,0) [0|61] "minute"  IPC,APIM_CISM,APIM
 SG_ ActChrgStrtHr_No_Actl : 36|5@0+ (1,0) [0|29] "hour"  IPC,APIM_CISM,HUD_ADV,APIM
 SG_ ActChrgStrtDay_No_Actl : 44|5@0+ (1,1) [1|31] "days"  IPC,APIM_CISM,APIM
 SG_ ActChrgStrMnth_No_Actl : 51|4@0+ (1,1) [1|15] "month"  IPC,APIM_CISM,APIM

BO_ 1145 GWM_HPCM_17_HS3: 8 GWM
 SG_ EstmChrgTimeLP_St : 39|8@0+ (0.1,0) [0|25.4] "hour"  GENERIC
 SG_ EstmChrgTimeHP_St : 47|8@0+ (0.1,0) [0|25.4] "hour"  GENERIC
 SG_ ChargeNowDuration_St : 31|8@0+ (0.1,0) [0|25.4] "hour"  GENERIC
 SG_ VehElRngeNut_L2_Dsply : 55|13@0+ (0.1,0) [0|818.9] "km"  APIM
 SG_ VehElRngeNut_L_Dsply : 11|12@0+ (0.1,0) [0|409.3] "km"  APIM_CISM,APIM,IPC
 SG_ NxtUsgSocEst_Pc_Dsply : 7|8@0+ (0.5,0) [0|126.5] "unitless"  APIM_CISM,APIM

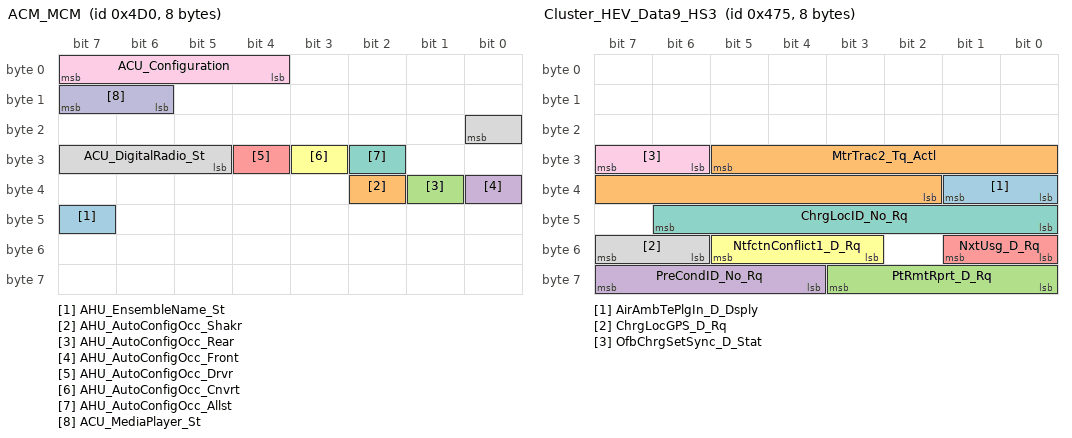
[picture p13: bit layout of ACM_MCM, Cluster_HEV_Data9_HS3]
BO_ 1232 ACM_MCM: 8 ACM
 SG_ AHU_EnsembleName_St : 47|1@0+ (1,0) [0|1] "SED"  APIM
 SG_ AHU_AutoConfigOcc_Shakr : 34|1@0+ (1,0) [0|1] "SED"  APIM
 SG_ AHU_AutoConfigOcc_Rear : 33|1@0+ (1,0) [0|1] "SED"  APIM
 SG_ AHU_AutoConfigOcc_Front : 32|1@0+ (1,0) [0|1] "SED"  APIM
 SG_ AHU_AutoConfigOcc_Drvr : 28|1@0+ (1,0) [0|1] "SED"  APIM
 SG_ AHU_AutoConfigOcc_Cnvrt : 27|1@0+ (1,0) [0|1] "SED"  APIM
 SG_ AHU_AutoConfigOcc_Allst : 26|1@0+ (1,0) [0|1] "SED"  APIM
 SG_ ACU_DigitalRadio_St : 16|4@0+ (1,0) [0|15] "SED"  APIM,IPC
 SG_ ACU_Configuration : 7|4@0+ (1,0) [0|15] "SED"  APIM,IPC
 SG_ ACU_MediaPlayer_St : 15|2@0+ (1,0) [0|3] "SED"  APIM,IPC

BO_ 1141 Cluster_HEV_Data9_HS3: 8 GWM
 SG_ AirAmbTePlgIn_D_Dsply : 33|2@0+ (1,0) [0|3] "SED"  IPC
 SG_ MtrTrac2_Tq_Actl : 29|12@0+ (1,-2047) [-2047|2048] "Nm" Vector__XXX
 SG_ PtRmtRprt_D_Rq : 59|4@0+ (1,0) [0|15] "SED"  IPC
 SG_ PreCondID_No_Rq : 63|4@0+ (1,0) [0|15] "unitless"  IPC
 SG_ NxtUsg_D_Rq : 49|2@0+ (1,0) [0|3] "SED"  IPC
 SG_ NtfctnConflict1_D_Rq : 53|3@0+ (1,0) [0|7] "SED"  APIM_CISM,APIM
 SG_ ChrgLocID_No_Rq : 46|7@0+ (1,0) [0|127] "unitless"  IPC
 SG_ ChrgLocGPS_D_Rq : 55|2@0+ (1,0) [0|3] "SED"  IPC
 SG_ OfbChrgSetSync_D_Stat : 31|2@0+ (1,0) [0|3] "SED"  APIM,APIM_CISM

BO_ 631 HEV_ChargeStat_HS3: 8 GWM
 SG_ RearPassWindowPos : 58|3@0+ (1,0) [0|7] "SED"  APIM_CISM,WCM,ACM
 SG_ RearDriverWindowPos : 62|3@0+ (1,0) [0|7] "SED"  APIM_CISM,WCM,ACM
 SG_ PassWindowPosition : 50|3@0+ (1,0) [0|7] "SED"  ACM,WCM
 SG_ RearPassWindowPos_UB : 59|1@0+ (1,0) [0|1] "SED"  APIM_CISM,WCM,ACM
 SG_ RearDriverWindowPos_UB : 63|1@0+ (1,0) [0|1] "SED"  APIM_CISM,WCM,ACM
 SG_ PassWindowPosition_UB : 51|1@0+ (1,0) [0|1] "SED"  ACM,WCM
 SG_ DriverWindowPosition : 54|3@0+ (1,0) [0|7] "SED"  APIM_CISM,WCM,ACM
 SG_ DriverWindowPosition_UB : 55|1@0+ (1,0) [0|1] "SED"  APIM_CISM,WCM,ACM
 SG_ CnvtTopPos_Up_Stat : 38|1@0+ (1,0) [0|1] "SED"  APIM_CISM,DACMC,DSP,ACM
 SG_ Memory_Cmd : 7|4@0+ (1,0) [0|15] "SED"  IPC
 SG_ CnvtTopPos_Up_Stat_UB : 37|1@0+ (1,0) [0|1] "SED"  APIM_CISM,DACMC,DSP,ACM
 SG_ Memory_Cmd_UB : 3|1@0+ (1,0) [0|1] "SED"  IPC
 SG_ EstmChrgTimeLP_St : 31|8@0+ (0.1,0) [0|25.4] "hour"  IPC,APIM_CISM,APIM
 SG_ EstmChrgTimeHP_St : 23|8@0+ (0.1,0) [0|25.4] "hour"  IPC,APIM_CISM,APIM
 SG_ ChargeNowDuration_St : 15|8@0+ (0.1,0) [0|25.4] "hour"  IPC,APIM_CISM,APIM
 SG_ CnvtTopMsgTxt_D_Rq_UB : 34|1@0+ (1,0) [0|1] "SED"  IPC
 SG_ CnvtTopMsgTxt_D_Rq : 36|2@0+ (1,0) [0|3] "SED"  IPC
 SG_ CnvtTopPos_Dn_Stat_UB : 1|1@0+ (1,0) [0|1] "SED"  APIM_CISM,DACMC,ACM
 SG_ CnvtTopPos_Dn_Stat : 2|1@0+ (1,0) [0|1] "SED"  APIM_CISM,DACMC,ACM
 SG_ EstmChrgTimeLP_St_UB : 33|1@0+ (1,0) [0|1] "SED"  APIM_CISM,APIM,IPC
 SG_ EstmChrgTimeHP_St_UB : 39|1@0+ (1,0) [0|1] "SED"  APIM_CISM,APIM,IPC
 SG_ ChargeNowDuration_St_UB : 0|1@0+ (1,0) [0|1] "SED"  APIM_CISM,APIM

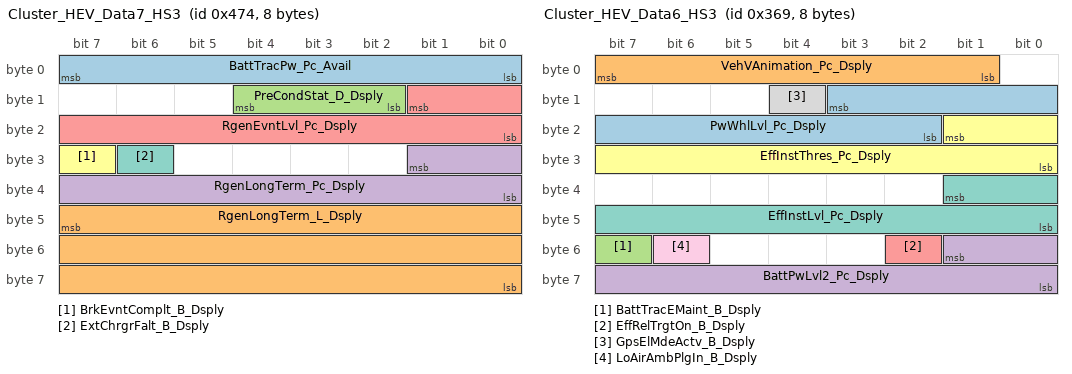
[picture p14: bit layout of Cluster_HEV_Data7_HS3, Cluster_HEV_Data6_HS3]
BO_ 1140 Cluster_HEV_Data7_HS3: 8 GWM
 SG_ BattTracPw_Pc_Avail : 7|8@0+ (0.5,0) [0|126.5] "percent"  IPC
 SG_ RgenLongTerm_L_Dsply : 47|24@0+ (0.1,0) [0|1677721.3] "km"  IPC
 SG_ PreCondStat_D_Dsply : 12|3@0+ (1,0) [0|7] "SED"  IPC
 SG_ RgenLongTerm_Pc_Dsply : 25|10@0+ (0.1,0) [0|102.3] "percent"  IPC
 SG_ RgenEvntLvl_Pc_Dsply : 9|10@0+ (0.1,0) [0|102.1] "percent"  IPC
 SG_ BrkEvntComplt_B_Dsply : 31|1@0+ (1,0) [0|1] "SED"  IPC
 SG_ ExtChrgrFalt_B_Dsply : 30|1@0+ (1,0) [0|1] "SED"  IPC

BO_ 873 Cluster_HEV_Data6_HS3: 8 GWM
 SG_ PwWhlLvl_Pc_Dsply : 11|10@0+ (0.2,-102.2) [-102.2|102.4] "percent"  IPC
 SG_ VehVAnimation_Pc_Dsply : 7|7@0+ (1,0) [0|127] "percent"  IPC
 SG_ BattTracEMaint_B_Dsply : 55|1@0+ (1,0) [0|1] "SED"  IPC
 SG_ BattPwLvl2_Pc_Dsply : 49|10@0+ (0.2,-102.2) [-102.2|102.4] "percent"  APIM_CISM,APIM,IPC
 SG_ EffRelTrgtOn_B_Dsply : 50|1@0+ (1,0) [0|1] "SED"  IPC
 SG_ EffInstThres_Pc_Dsply : 17|10@0+ (0.1,0) [0|102.3] "percent"  IPC
 SG_ EffInstLvl_Pc_Dsply : 33|10@0+ (0.1,0) [0|102.3] "percent"  IPC
 SG_ GpsElMdeActv_B_Dsply : 12|1@0+ (1,0) [0|1] "SED"  APIM_CISM,APIM,IPC
 SG_ LoAirAmbPlgIn_B_Dsply : 54|1@0+ (1,0) [0|1] "SED"  IPC

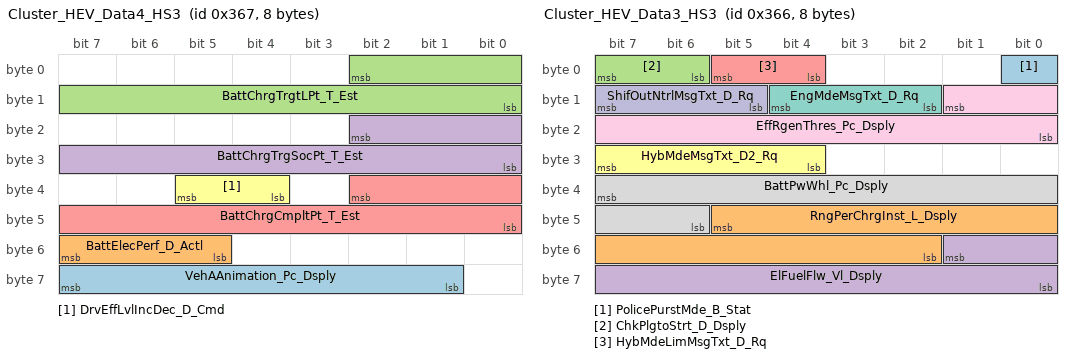
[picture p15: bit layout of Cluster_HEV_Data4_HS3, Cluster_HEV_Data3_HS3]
BO_ 871 Cluster_HEV_Data4_HS3: 8 GWM
 SG_ VehAAnimation_Pc_Dsply : 63|7@0+ (1,0) [0|127] "percent"  IPC
 SG_ BattElecPerf_D_Actl : 55|3@0+ (1,0) [0|7] "SED"  IPC
 SG_ BattChrgTrgtLPt_T_Est : 2|11@0+ (1,0) [0|2045] "minute"  IPC
 SG_ BattChrgTrgSocPt_T_Est : 18|11@0+ (1,0) [0|2045] "minute"  IPC
 SG_ BattChrgCmpltPt_T_Est : 34|11@0+ (1,0) [0|2045] "minute"  IPC
 SG_ DrvEffLvlIncDec_D_Cmd : 37|2@0+ (1,0) [0|3] "SED"  IPC

BO_ 870 Cluster_HEV_Data3_HS3: 8 GWM
 SG_ PolicePurstMde_B_Stat : 0|1@0+ (1,0) [0|1] "SED"  IPC
 SG_ RngPerChrgInst_L_Dsply : 45|12@0+ (0.1,0) [0|409.3] "km"  IPC
 SG_ ChkPlgtoStrt_D_Dsply : 7|2@0+ (1,0) [0|3] "SED"  IPC
 SG_ ElFuelFlw_Vl_Dsply : 49|10@0+ (25,0) [0|25575] "micro-litre"  IPC
 SG_ HybMdeLimMsgTxt_D_Rq : 5|2@0+ (1,0) [0|3] "SED"  IPC
 SG_ HybMdeMsgTxt_D2_Rq : 31|4@0+ (1,0) [0|15] "SED"  IPC
 SG_ EngMdeMsgTxt_D_Rq : 12|3@0+ (1,0) [0|7] "SED"  IPC
 SG_ BattPwWhl_Pc_Dsply : 39|10@0+ (0.1,0) [0|102.3] "percent"  IPC
 SG_ EffRgenThres_Pc_Dsply : 9|10@0+ (0.1,-102.3) [-102.3|0] "percent"  IPC
 SG_ ShifOutNtrlMsgTxt_D_Rq : 15|3@0+ (1,0) [0|7] "SED"  IPC

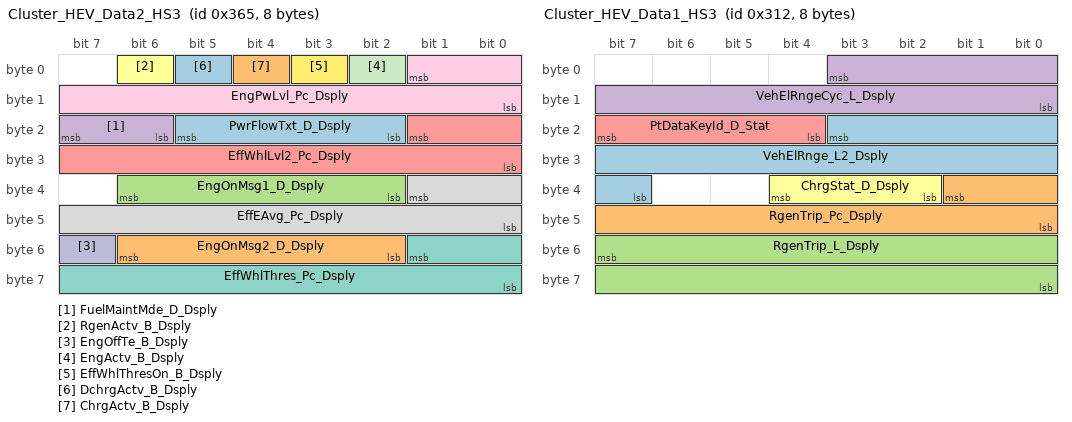
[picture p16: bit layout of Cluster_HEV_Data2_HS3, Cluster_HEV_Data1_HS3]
BO_ 869 Cluster_HEV_Data2_HS3: 8 GWM
 SG_ PwrFlowTxt_D_Dsply : 21|4@0+ (1,0) [0|15] "SED"  APIM_CISM,APIM,IPC
 SG_ EngOnMsg2_D_Dsply : 54|5@0+ (1,0) [0|31] "SED"  APIM_CISM,APIM,IPC
 SG_ EngOnMsg1_D_Dsply : 38|5@0+ (1,0) [0|31] "SED"  APIM_CISM,APIM,IPC
 SG_ FuelMaintMde_D_Dsply : 23|2@0+ (1,0) [0|3] "SED"  IPC
 SG_ EffWhlLvl2_Pc_Dsply : 17|10@0+ (0.2,-102.2) [-102.2|102.4] "percent"  APIM_CISM,APIM,IPC
 SG_ RgenActv_B_Dsply : 6|1@0+ (1,0) [0|1] "SED"  IPC
 SG_ EffWhlThres_Pc_Dsply : 49|10@0+ (0.1,0) [0|102.3] "percent"  IPC
 SG_ EffEAvg_Pc_Dsply : 33|10@0+ (0.1,0) [0|102.3] "percent"  APIM_CISM,APIM,IPC
 SG_ EngPwLvl_Pc_Dsply : 1|10@0+ (0.1,0) [0|102.3] "percent"  APIM_CISM,APIM,IPC
 SG_ EngOffTe_B_Dsply : 55|1@0+ (1,0) [0|1] "SED"  IPC
 SG_ EngActv_B_Dsply : 2|1@0+ (1,0) [0|1] "SED"  APIM_CISM,APIM,IPC
 SG_ EffWhlThresOn_B_Dsply : 3|1@0+ (1,0) [0|1] "SED"  IPC
 SG_ DchrgActv_B_Dsply : 5|1@0+ (1,0) [0|1] "SED"  IPC
 SG_ ChrgActv_B_Dsply : 4|1@0+ (1,0) [0|1] "SED"  IPC

BO_ 786 Cluster_HEV_Data1_HS3: 8 GWM
 SG_ VehElRnge_L2_Dsply : 19|13@0+ (0.1,0) [0|818.9] "kilometer"  IPC,APIM
 SG_ RgenTrip_Pc_Dsply : 33|10@0+ (0.1,0) [0|102.3] "percent"  IPC
 SG_ RgenTrip_L_Dsply : 55|16@0+ (0.1,0) [0|6553.3] "kilometer"  IPC
 SG_ VehElRngeCyc_L_Dsply : 3|12@0+ (0.1,0) [0|409.3] "km"  APIM,APIM_CISM
 SG_ PtDataKeyId_D_Stat : 23|4@0+ (1,0) [0|15] "SED"  GENERIC
 SG_ ChrgStat_D_Dsply : 36|3@0+ (1,0) [0|7] "SED"  APIM_CISM,APIM,IPC

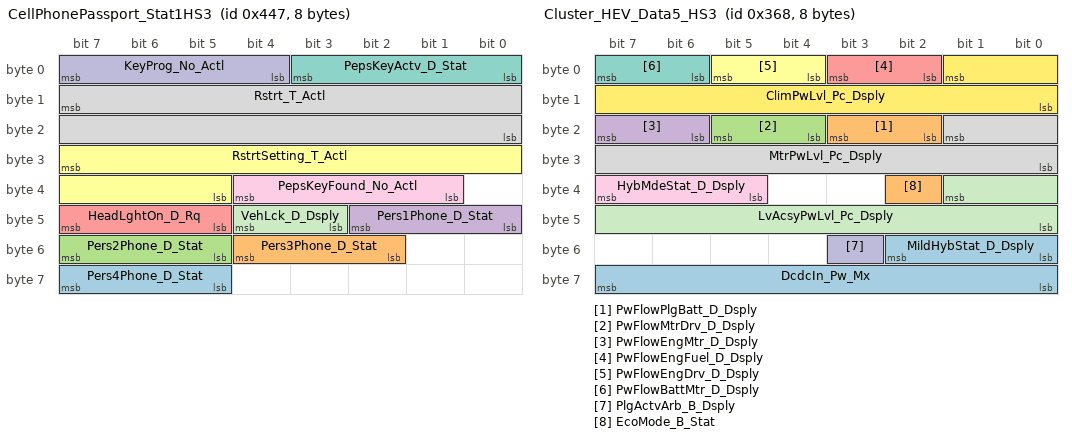
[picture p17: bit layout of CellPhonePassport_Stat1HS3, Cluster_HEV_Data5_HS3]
BO_ 1095 CellPhonePassport_Stat1HS3: 8 GWM
 SG_ Pers4Phone_D_Stat : 63|3@0+ (1,0) [0|7] "SED"  APIM
 SG_ Pers3Phone_D_Stat : 52|3@0+ (1,0) [0|7] "SED"  APIM
 SG_ Pers2Phone_D_Stat : 55|3@0+ (1,0) [0|7] "SED"  APIM
 SG_ Pers1Phone_D_Stat : 42|3@0+ (1,0) [0|7] "SED"  APIM
 SG_ HeadLghtOn_D_Rq : 47|3@0+ (1,0) [0|7] "SED"  GENERIC
 SG_ RstrtSetting_T_Actl : 31|11@0+ (1,0) [0|2047] "second"  GENERIC
 SG_ PepsKeyActv_D_Stat : 3|4@0+ (1,0) [0|15] "SED"  GENERIC
 SG_ Rstrt_T_Actl : 15|16@0+ (1,0) [0|65535] "seconds"  GENERIC
 SG_ PepsKeyFound_No_Actl : 36|4@0+ (1,0) [0|15] "unitless"  GENERIC
 SG_ KeyProg_No_Actl : 7|4@0+ (1,0) [0|15] "unitless"  GENERIC
 SG_ VehLck_D_Dsply : 44|2@0+ (1,0) [0|3] "SED"  GENERIC

BO_ 684 MC_RDISP_WORD_Rx: 8 APIM
 SG_ MC_RDISP_WORD_Rx : 7|64@0+ (1,0) [0|1.84467440737096E+019] "unitless"  IPC

BO_ 872 Cluster_HEV_Data5_HS3: 8 GWM
 SG_ DcdcIn_Pw_Mx : 63|8@0+ (20,1000) [1000|6100] "watts"  GENERIC
 SG_ PwFlowPlgBatt_D_Dsply : 19|2@0+ (1,0) [0|3] "SED"  APIM_CISM,APIM,IPC
 SG_ PwFlowMtrDrv_D_Dsply : 21|2@0+ (1,0) [0|3] "SED"  APIM_CISM,APIM,IPC
 SG_ PwFlowEngMtr_D_Dsply : 23|2@0+ (1,0) [0|3] "SED"  APIM_CISM,APIM,IPC
 SG_ PwFlowEngFuel_D_Dsply : 3|2@0+ (1,0) [0|3] "SED"  APIM_CISM,APIM,IPC
 SG_ PwFlowEngDrv_D_Dsply : 5|2@0+ (1,0) [0|3] "SED"  APIM_CISM,APIM,IPC
 SG_ PwFlowBattMtr_D_Dsply : 7|2@0+ (1,0) [0|3] "SED"  APIM_CISM,APIM,IPC
 SG_ MtrPwLvl_Pc_Dsply : 17|10@0+ (0.2,-102.2) [-102.2|102.4] "percent"  APIM_CISM,APIM,IPC
 SG_ HybMdeStat_D_Dsply : 39|3@0+ (1,0) [0|7] "SED"  APIM,HUD_ADV,APIM_CISM,IPC
 SG_ PlgActvArb_B_Dsply : 51|1@0+ (1,0) [0|1] "SED"  APIM_CISM,APIM,IPC
 SG_ LvAcsyPwLvl_Pc_Dsply : 33|10@0+ (0.1,0) [0|102.3] "percent"  APIM_CISM,APIM,IPC
 SG_ ClimPwLvl_Pc_Dsply : 1|10@0+ (0.1,0) [0|102.3] "percent"  APIM_CISM,APIM,IPC
 SG_ MildHybStat_D_Dsply : 50|3@0+ (1,0) [0|7] "SED"  IPC
 SG_ EcoMode_B_Stat : 34|1@0+ (1,0) [0|1] "SED"  IPC

BO_ 791 Cluster_HEV_Data8: 8 IPC
 SG_ StopStrtVThres_D_RqMnu : 17|2@0+ (1,0) [0|3] "SED"  GWM
 SG_ AwdDrvMde_D2_Rq : 21|4@0+ (1,0) [0|15] "SED"  GWM
 SG_ VehElEffTrip2Reset_B_Rq : 62|1@0+ (1,0) [0|1] "SED"  GWM
 SG_ VehElEffTrip1Reset_B_Rq : 63|1@0+ (1,0) [0|1] "SED"  GWM
 SG_ EngAirFilt_B_RqReset : 48|1@0+ (1,0) [0|1] "SED"  GWM
 SG_ BattElEmotive_Pc_Dsply : 1|10@0+ (0.1,0) [0|102.1] "percent"  APIM_CISM,APIM,GWM
 SG_ HybMdeOvrrd_D_Rq : 7|2@0+ (1,0) [0|3] "SED"  GWM
 SG_ GpsElMdeSel_B_Rq : 50|1@0+ (1,0) [0|1] "SED"  GWM
 SG_ LongTermReset_B_Rq : 49|1@0+ (1,0) [0|1] "SED"  GWM
 SG_ EcoCcActv_B_Rq : 51|1@0+ (1,0) [0|1] "SED"  GWM
 SG_ DrvEffLvl_No_Stat : 61|6@0+ (1,0) [0|61] "unitless"  APIM_CISM,APIM,GWM
 SG_ ChargeProfIDPref_Rq : 5|2@0+ (1,0) [0|3] "SED"  GWM
 SG_ ConsAvgTrip_Fe_Dsply : 31|24@0+ (0.0001,0) [0|1677.7215] "litre/100km"  GWM
 SG_ GrdAsstAllw_D_RqMnu : 23|2@0+ (1,0) [0|3] "SED"  GWM
 SG_ PlgOvrrdStrt_D_Cmd : 55|2@0+ (1,0) [0|3] "SED"  GWM
 SG_ EcoMde_D_RqMnu : 3|2@0+ (1,0) [0|3] "SED"  GWM
 SG_ EmotiveType_D_Dsply : 53|2@0+ (1,0) [0|3] "SED"  APIM_CISM,APIM,GWM

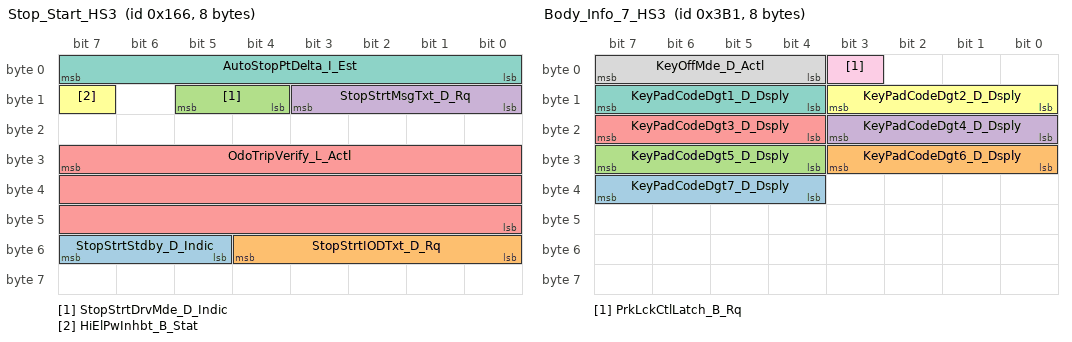
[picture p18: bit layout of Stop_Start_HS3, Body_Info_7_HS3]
BO_ 358 Stop_Start_HS3: 8 GWM
 SG_ StopStrtStdby_D_Indic : 55|3@0+ (1,0) [0|7] "SED"  IPC
 SG_ StopStrtIODTxt_D_Rq : 52|5@0+ (1,0) [0|31] "SED"  IPC
 SG_ StopStrtDrvMde_D_Indic : 13|2@0+ (1,0) [0|3] "SED"  APIM_CISM,APIM,IPC
 SG_ StopStrtMsgTxt_D_Rq : 11|4@0+ (1,0) [0|15] "SED"  IPC
 SG_ OdoTripVerify_L_Actl : 31|24@0+ (0.1,0) [0|1677721.4] "km"  IPC
 SG_ HiElPwInhbt_B_Stat : 15|1@0+ (1,0) [0|1] "SED"  GENERIC
 SG_ AutoStopPtDelta_I_Est : 7|8@0+ (1,-127) [-127|127] "Amps"  GENERIC

BO_ 840 FoH_Day_Req: 8 IPC
 SG_ FohAddHeater_D_Rq : 9|2@0+ (1,0) [0|3] "SED"  GWM
 SG_ FohStrtDateYr_No_Rq : 39|8@0+ (1,2000) [2000|2255] "year"  GWM
 SG_ FohStrtDateDay_No_Rq : 23|16@0+ (1,0) [0|65535] "julian day"  GWM
 SG_ FohT2Friday_T_Rq : 0|1@0+ (1,0) [0|1] "SED"  GWM
 SG_ FohT1Friday_T_Rq : 7|1@0+ (1,0) [0|1] "SED"  GWM
 SG_ FohT2Wednesday_T_Rq : 10|1@0+ (1,0) [0|1] "SED"  GWM
 SG_ FohT2Tuesday_T_Rq : 11|1@0+ (1,0) [0|1] "SED"  GWM
 SG_ FohT2Thursday_T_Rq : 12|1@0+ (1,0) [0|1] "SED"  GWM
 SG_ FohT2Sunday_T_Rq : 13|1@0+ (1,0) [0|1] "SED"  GWM
 SG_ FohT2Saturday_T_Rq : 14|1@0+ (1,0) [0|1] "SED"  GWM
 SG_ FohT2Monday_T_Rq : 15|1@0+ (1,0) [0|1] "SED"  GWM
 SG_ FohT1Wednesday_T_Rq : 1|1@0+ (1,0) [0|1] "SED"  GWM
 SG_ FohT1Tuesday_T_Rq : 2|1@0+ (1,0) [0|1] "SED"  GWM
 SG_ FohT1Thursday_T_Rq : 3|1@0+ (1,0) [0|1] "SED"  GWM
 SG_ FohT1Sunday_T_Rq : 4|1@0+ (1,0) [0|1] "SED"  GWM
 SG_ FohT1Saturday_T_Rq : 5|1@0+ (1,0) [0|1] "SED"  GWM
 SG_ FohT1Monday_T_Rq : 6|1@0+ (1,0) [0|1] "SED"  GWM

BO_ 945 Body_Info_7_HS3: 8 GWM
 SG_ KeyPadCodeDgt7_D_Dsply : 39|4@0+ (1,0) [0|15] "SED"  IPC
 SG_ KeyPadCodeDgt6_D_Dsply : 27|4@0+ (1,0) [0|15] "SED"  IPC
 SG_ KeyPadCodeDgt5_D_Dsply : 31|4@0+ (1,0) [0|15] "SED"  IPC
 SG_ KeyPadCodeDgt4_D_Dsply : 19|4@0+ (1,0) [0|15] "SED"  IPC
 SG_ KeyPadCodeDgt3_D_Dsply : 23|4@0+ (1,0) [0|15] "SED"  IPC
 SG_ KeyPadCodeDgt2_D_Dsply : 11|4@0+ (1,0) [0|15] "SED"  IPC
 SG_ KeyPadCodeDgt1_D_Dsply : 15|4@0+ (1,0) [0|15] "SED"  IPC
 SG_ KeyOffMde_D_Actl : 7|4@0+ (1,0) [0|15] "SED"  TRM_ITRM,APIM_CISM,IPC,APIM
 SG_ PrkLckCtlLatch_B_Rq : 3|1@0+ (1,0) [0|1] "SED"  IPC

BO_ 740 ACM_Send_Signals_2: 8 GENERIC
 SG_ EmgcyAsstActv_D_Stat : 7|2@0+ (1,0) [0|3] "SED"  GWM

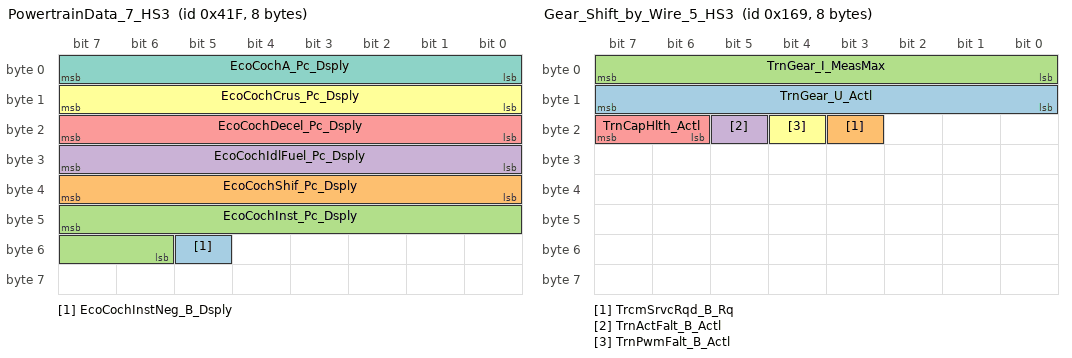
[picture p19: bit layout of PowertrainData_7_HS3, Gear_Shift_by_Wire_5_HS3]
BO_ 1055 PowertrainData_7_HS3: 8 GWM
 SG_ EcoCochInstNeg_B_Dsply : 53|1@0+ (1,0) [0|1] "SED"  IPC
 SG_ EcoCochShif_Pc_Dsply : 39|8@0+ (0.392157,0) [0|100.000035] "percent"  IPC
 SG_ EcoCochInst_Pc_Dsply : 47|10@0+ (0.1,0) [0|102.3] "percent"  IPC
 SG_ EcoCochIdlFuel_Pc_Dsply : 31|8@0+ (0.392157,0) [0|100.000035] "percent"  IPC
 SG_ EcoCochDecel_Pc_Dsply : 23|8@0+ (0.392157,0) [0|100.000035] "percent"  APIM,IPC
 SG_ EcoCochCrus_Pc_Dsply : 15|8@0+ (0.392157,0) [0|100.000035] "percent"  APIM,IPC
 SG_ EcoCochA_Pc_Dsply : 7|8@0+ (0.392157,0) [0|100.000035] "percent"  APIM,IPC

BO_ 361 Gear_Shift_by_Wire_5_HS3: 8 GWM
 SG_ TrnGear_U_Actl : 15|8@0+ (0.1,0) [0|25.5] "volt"  GENERIC
 SG_ TrcmSrvcRqd_B_Rq : 19|1@0+ (1,0) [0|1] "SED"  IPC
 SG_ TrnGear_I_MeasMax : 7|8@0+ (0.1,0) [0|25.4] "Amps"  GENERIC
 SG_ TrnActFalt_B_Actl : 21|1@0+ (1,0) [0|1] "SED"  GENERIC
 SG_ TrnCapHlth_Actl : 23|2@0+ (1,0) [0|3] "SED"  GENERIC
 SG_ TrnPwmFalt_B_Actl : 20|1@0+ (1,0) [0|1] "SED"  GENERIC

BO_TX_BU_ 579 : APIM_CISM,APIM;
BO_TX_BU_ 578 : APIM_CISM,APIM;
BO_TX_BU_ 577 : APIM_CISM,APIM;
BO_TX_BU_ 717 : APIM_CISM,APIM;
BO_TX_BU_ 719 : APIM_CISM,APIM;
BO_TX_BU_ 589 : APIM_CISM,APIM;
BO_TX_BU_ 737 : APIM_CISM,APIM;
BO_TX_BU_ 1109 : APIM_CISM,APIM;
BO_TX_BU_ 546 : APIM_CISM,APIM;
BO_TX_BU_ 1232 : APIM_CISM,ACM;
BO_TX_BU_ 684 : APIM_CISM,APIM;
CM_ BO_ 611 "Used on Applications with 4x4 supplied by Motorola.";
CM_ SG_ 611 AwdStat_D_RqDsply "Signal not transmitted on programs that do not have AWD.";
CM_ SG_ 611 AwdSrvcRqd_B_Rq "Signal not transmitted on programs that do not have AWD.";
CM_ SG_ 611 AwdLck_Tq_Rq "Signal not transmitted on programs that do not have AWD.";
CM_ SG_ 264 BpedDrvAppl_D_Actl "CCMGenSigTimeoutTime=1000";
CM_ SG_ 969 TurnLampRrOut_B_Stat "Signal not transmitted on vehicles without a BCMB module.";
CM_ SG_ 969 TurnLampRlOut_B_Stat "Signal not transmitted on vehicles without a BCMB module.";
CM_ SG_ 130 SelDrvMdeSwtch3_D_Stat4 "ECM_HEV does not support or Transmit signal.";
CM_ SG_ 1244 Con_InfotainmentVer_St "Object Configuration Management.CON_InfotainmetVer";
CM_ SG_ 1244 Con_Profiles_St "Object Configuration Management.CON_Profiles

Bit 0: 0: invalid 1: valid
Bit 1: 0: No iPod browsing support 1: iPod browsing support
Bit 2: 0: No USB browsing support 1: USB browsing support
Bit 3: Reserved
Bit 4: Reserved";
CM_ SG_ 1244 Con_Configuration "Object Configuration Management.CON_Configuration

Bit 0: 0=invalid, 1=valid
Bit 1: SWDLviaUSB support: 0=No, 1=Yes
Bit 2: iPod support 0=No, 1:=Yes
Bit 3: USB support 0=No, 1=Yes
Bit 4: Reserved";
CM_ SG_ 1243 Con_BTAud_InfotainmVer_St "Object Configuration Management.BTAud_InfotainmentVer";
CM_ SG_ 1243 Con_BTAud_Profiles_St "Object Configuration Management.BTAud_Profiles

Bit 0: 0: invalid 1: valid
Bit 1: 0: No BTAudio browsing support 1: BTAudio browsing support
Bit 2: 0: No BTAudio device setting support 1: BTAudio device setting support
Bit 3: ElapsedRemainingTiming

";
CM_ SG_ 1243 Con_BTAudConfiguration "Object Configuration Management.BTAud_Configuration

Bit 0: 0: invalid 1: valid
Bit 1: 0: No BTAudio streaming support 1: BTAudio streaming
Bit 2: 0: No mobile navigation support 1: Mobile navigation";
CM_ SG_ 681 Con_DB1temIndex_St "Object Media Player iPod.MDBActiveTrack.ItemIndex";
CM_ SG_ 681 Con_DB1FilterConfig_St "Object Media Player iPod.MDBActiveTrack.MDBFilterConf";
CM_ SG_ 681 Con_DB1Filter3_St "Object Media Player iPod.MDBActiveTrack.MDBFilter3";
CM_ SG_ 681 Con_DB1Filter2_St "Object Media Player iPod..MDBActiveTrack.MDBFilter2";
CM_ SG_ 681 Con_DB1Filter1_St "Object Media Player iPod..MDBActiveTrack.MDBFilter1";
CM_ SG_ 744 Con_USB_ActTrNum1_St "Object Media Player USB.ActiveTrackNum1";
CM_ SG_ 744 Con_iPod_NumberOfTracks "Object Media Player USB..NumberofTracks
Info: Tracks in current folder";
CM_ SG_ 744 Con_USB_NumberOfTracks "Object Media Player USB..NumberofTracks
Info: Tracks in current folder";
CM_ SG_ 741 Con_USB_Playtype_St "Object Media Player USB.Playtype
Playtype:
Playlist is selected if CON module plays tracks out of a Playlist
";
CM_ SG_ 741 Con_ShowSWDLBargr_St "Object SWDL.ShowSWDLBargraphStatus

Range (dec): 0% - 100% (0x00 - 0x64)

No update in progress: ConnectivitySWUpdateNotRunning: $7E";
CM_ SG_ 741 Con_ShowSWDLprogress_St "Object SWDL.Con_ShowCONSWDL_St";
CM_ SG_ 741 Con_iPod_IntroScan_St "Object Media Player iPod.Introscan";
CM_ SG_ 741 Con_iPod_Shuffle_St "Object Media Player iPod.Shuffle";
CM_ SG_ 741 Con_iPod_Repeat_St "Object Media Player iPod.Repeat";
CM_ SG_ 741 Con_USB_Repeat_St "Object Media Player USB.Repeat";
CM_ SG_ 741 Con_USB_IntroScan_St "Object Media Player USB.IntroScan";
CM_ SG_ 741 Con_USB_Shuffle_St "Object MediaPlayer USB.Shuffle";
CM_ SG_ 741 Con_iPod_Error_St "Object Media Player iPod.iPodError";
CM_ SG_ 741 Con_USB_Error_St "Object Media Player USB.USBError";
CM_ SG_ 741 Con_iPod_FunctStatus_St "Object Media Player iPod.FunctionStatus";
CM_ SG_ 741 Con_USB_FunctStatus_St "Object Media Player USB.FunctionStatus";
CM_ SG_ 741 Con_USB_OpMode_St "Object Media Player USB.OperationMode";
CM_ SG_ 741 Con_iPod_OpMode_St "Object Media Player iPod.OperationMode";
CM_ SG_ 954 GenericSwtch2_No_Actl "U625 Police Wig Wag feature";
CM_ BO_ 2611175520 "TpTxIndex = 463569112 paired to 0x1BA180D8";
CM_ BO_ 2610126944 "TpTxIndex = 462520536 which is paired to 0x1B9180D8 OTAPhysGWM_ECGtoIPC ";
CM_ SG_ 576 AUDIO_RDISP2_WORD_Tx "MM ISO 15765-2 Message Catalogue AUDIO - RDISP2";
CM_ SG_ 1115 HUD_TextMessage_Rq "Object. BTPhoneClient.TextMessage.Rq";
CM_ SG_ 1115 HUD_BTIncomingCall_Rq "Object Bluetooth Phone.BTIncomingCall";
CM_ SG_ 1115 HUD_BTInCallOptions_Rq "Object.BTPhoneClient.BTInCallOptions.Rq.SingleParam";
CM_ SG_ 1115 HUD_BTEndTelService_Rq "Object Bluetooth Phone.BTEndTelService";
CM_ SG_ 588 RDRV_RDISP2_WORD_Rx "MM ISO 15765-2 Message Catalogue RDISP2 - RDRV";
CM_ SG_ 587 PHONE_RDISP2_WORD_Rx "MM ISO 15765-2 Message Catalogue
Section MC - PHONE";
CM_ SG_ 579 PHONE_RDISP2_WORD_Tx "MM ISO 15765-2 Message Catalogue
Section  PHONE - MC";
CM_ SG_ 585 NAV_RDISP2_WORD_Rx "MM ISO 15765-2 Message Catalogue NavRepClient2 - NavRepServer";
CM_ SG_ 586 CONMP_RDISP2_WORD_Rx "MM ISO 15765-2 Message Catalogue
Section CONMP - MC
Section MediaPlayerServer - MediaPlayerClient";
CM_ SG_ 578 CONMP_RDISP2_WORD_Tx "MM ISO 15765-2 Message Catalogue
Section CONMP - MC
Section MediaPlayerServer - MediaPlayerClient";
CM_ SG_ 577 NAV_RDISP2_WORD_Tx "MM ISO 15765-2 Message Catalogue NavRepServer – NavRepClient2";
CM_ SG_ 712 NAV_MC_WORD_Rx "MM ISO 15765-2 Message Catalogue
Section MC - NAV
Section NavRepClient - NavRepServer";
CM_ SG_ 717 DSPAMP_RDISP_WORD_Rx "Object:BezelDiagnostics.DSP_Bezel_Diag_Data";
CM_ SG_ 719 MyKeySrvr_Clnt_Word_Rx "Object.RepSrv_RepClient_WORD_Rx";
CM_ SG_ 745 ECG_APIM_Word_Tx "Tx by HS3 APIM";
CM_ SG_ 546 Prompt_Directionality "Object.AlertMethod. SYNC_Alerts

";
CM_ SG_ 546 Audible_Beep "Object.AlertMethod. SYNC_Alerts";
CM_ SG_ 546 Alert_Chan "Object.AlertMethod. SYNC_Alerts
";
CM_ SG_ 1042 VehYaw_W_Actl "CCMGenSigTimeoutTime=1000";
CM_ SG_ 1093 StopLamp_B_RqTrlrBrk "Signal not transmitted on all variants.";
CM_ SG_ 1232 AHU_EnsembleName_St "Object Configuration Management.EnsembleName_St";
CM_ SG_ 1232 AHU_AutoConfigOcc_Shakr "Object: AudioSettings.AHU_AutoConFigOcc_Shaker";
CM_ SG_ 1232 AHU_AutoConfigOcc_Rear "Object:AudioSettings.AHU_AutoConfigOcc_Rear";
CM_ SG_ 1232 AHU_AutoConfigOcc_Front "Object: AudioSettings. AHU_AutoConfigOcc_Front";
CM_ SG_ 1232 AHU_AutoConfigOcc_Drvr "Object:AudioSettings.AHU_AutoConfigOcc_Driver";
CM_ SG_ 1232 AHU_AutoConfigOcc_Cnvrt "AHU_AutoConfigOcc_Convertible ";
CM_ SG_ 1232 AHU_AutoConfigOcc_Allst "Object: AudioSettings. AHU_AutoConfigOcc_AllSeats";
CM_ SG_ 1232 ACU_DigitalRadio_St "Object Configuration Management.ACU_DigitalRadio";
CM_ SG_ 1232 ACU_Configuration "Object Configuration Management.ACU_Configuration";
CM_ SG_ 1232 ACU_MediaPlayer_St "Object Configuration Management.ACU_MediaPlayer

$1: MusicCassettePlayer is handled as Medialess in MFD setup";
CM_ SG_ 631 CnvtTopPos_Up_Stat "Signal not transmitted on vehicles without convertible tops.";
CM_ SG_ 631 CnvtTopPos_Dn_Stat "Signal not transmitted on vehicles without convertible tops.";
CM_ SG_ 870 PolicePurstMde_B_Stat "Normal SED EP 1000. Using 100FP can result  in100ms w/c latency.  Latency accepted for feature/function by SME since existing FGW msg.";
CM_ SG_ 684 MC_RDISP_WORD_Rx "Communicates ConsHistGraph_St, which includes data to populate the consumption history display.";
CM_ SG_ 791 ChargeProfIDPref_Rq "Object:ChargeProfIDPref_St
Status of the charge preference for the current Charge Profile.";
CM_ SG_ 358 HiElPwInhbt_B_Stat "Signal not transmitted on HEV programs";
CM_ SG_ 358 AutoStopPtDelta_I_Est "Signal not transmitted on vehicles that do not have autostop/stop-start feature.";
CM_ SG_ 840 FohT2Friday_T_Rq "Signal not transmitted on vehicles that do not have the Fuel operated heater feature.";
CM_ SG_ 840 FohT1Friday_T_Rq "Signal not transmitted on vehicles that do not have the Fuel operated heater feature.";
CM_ SG_ 840 FohT2Wednesday_T_Rq "Signal not transmitted on vehicles that do not have the Fuel operated heater feature.";
CM_ SG_ 840 FohT2Tuesday_T_Rq "Signal not transmitted on vehicles that do not have the Fuel operated heater feature.";
CM_ SG_ 840 FohT2Thursday_T_Rq "Signal not transmitted on vehicles that do not have the Fuel operated heater feature.";
CM_ SG_ 840 FohT2Sunday_T_Rq "Signal not transmitted on vehicles that do not have the Fuel operated heater feature.";
CM_ SG_ 840 FohT2Saturday_T_Rq "Signal not transmitted on vehicles that do not have the Fuel operated heater feature.";
CM_ SG_ 840 FohT2Monday_T_Rq "Signal not transmitted on vehicles that do not have the Fuel operated heater feature.";
CM_ SG_ 840 FohT1Wednesday_T_Rq "Signal not transmitted on vehicles that do not have the Fuel operated heater feature.";
CM_ SG_ 840 FohT1Tuesday_T_Rq "Signal not transmitted on vehicles that do not have the Fuel operated heater feature.";
CM_ SG_ 840 FohT1Thursday_T_Rq "Signal not transmitted on vehicles that do not have the Fuel operated heater feature.";
CM_ SG_ 840 FohT1Sunday_T_Rq "Signal not transmitted on vehicles that do not have the Fuel operated heater feature.";
CM_ SG_ 840 FohT1Saturday_T_Rq "Signal not transmitted on vehicles that do not have the Fuel operated heater feature.";
CM_ SG_ 840 FohT1Monday_T_Rq "Signal not transmitted on vehicles that do not have the Fuel operated heater feature.";
CM_ SG_ 361 TrcmSrvcRqd_B_Rq "Signal not transmitted on vehicles that do not have shift by wire.";
CM_ SG_ 361 TrnGear_I_MeasMax "Signal not transmitted on vehicles that do not have shift by wire.";
CM_ SG_ 361 TrnActFalt_B_Actl "Signal not transmitted on vehicles that do not have shift by wire.";
CM_ SG_ 361 TrnCapHlth_Actl "Signal not transmitted on vehicles that do not have shift by wire.";
CM_ SG_ 361 TrnPwmFalt_B_Actl "Signal not transmitted on vehicles that do not have shift by wire.";
BA_DEF_ BO_  "FrameRouting" STRING ;
BA_DEF_ BO_  "FrameGatewayNetwork" STRING ;
BA_DEF_ BO_  "NetworkInitialization" ENUM  "No","Yes";
BA_DEF_ BO_  "FrameGatewayId" HEX 0 1407;
BA_DEF_ BO_  "EventRateOfChange" INT 10 10000;
BA_DEF_ BO_  "GenMsgStartDelayTime" INT 0 10000;
BA_DEF_ BO_  "GenMsgNrOfRepetition" INT 0 100;
BA_DEF_ BO_  "GenMsgDelayTime" INT 0 1000;
BA_DEF_ BO_  "GenMsgCycleTime" INT 0 100000;
BA_DEF_ BO_  "GenMsgSendType" ENUM  "FixedPeriodic","Event","EnabledPeriodic","NotUsed","NotUsed","EventPeriodic","NotUsed","NotUsed","NoMsgSendType";
BA_DEF_ SG_  "U_U55X_MY2022_Tx" ENUM  "No","Yes";
BA_DEF_ SG_  "U_CD542_MY2021_Tx" ENUM  "No","Yes";
BA_DEF_ SG_  "ECGUsedTxSignal" ENUM  "No","Yes";
BA_DEF_ SG_  "U_T6_MCA_MY2020_Tx" ENUM  "No","Yes";
BA_DEF_ SG_  "U_P702_MY2021_Tx" ENUM  "No","Yes";
BA_DEF_ SG_  "U_CX727_MY2021_Tx" ENUM  "No","Yes";
BA_DEF_ SG_  "U_FNV2_IVI_Rx" ENUM  "No","Yes";
BA_DEF_ SG_  "U_U55X_MY2022_Rx" ENUM  "No","Yes";
BA_DEF_ SG_  "U_CD542_MY2021_Rx" ENUM  "No","Yes";
BA_DEF_ SG_  "ECGUsedRxSignal" ENUM  "No","Yes";
BA_DEF_ SG_  "U_T6_MCA_MY2020_Rx" ENUM  "No","Yes";
BA_DEF_ SG_  "U_P702_MY2021_Rx" ENUM  "No","Yes";
BA_DEF_ SG_  "U_CX727_MY2021_Rx" ENUM  "No","Yes";
BA_DEF_ SG_  "GenSigStartValue" HEX 0 268435455;
BA_DEF_ SG_  "MetaData" ENUM  "No","Yes";
BA_DEF_ SG_  "ContentDependant" ENUM  "No","Yes";
BA_DEF_ SG_  "GenSigStartValueInteger" INT 0 1000000000;
BA_DEF_ SG_  "UsedOnPgmDBC" ENUM  "No","Yes";
BA_DEF_ SG_  "WakeupSignal" ENUM  "No","Yes";
BA_DEF_ SG_  "GenSigInactiveValue" INT 0 100000;
BA_DEF_ SG_  "GenSigSendType" ENUM  "Cyclic","OnWrite","vector_leerstring","OnChange","vector_leerstring","IfActive","vector_leerstring","NoSigSendType";
BA_DEF_ BO_  "OvtpPushApplication" ENUM  "FALSE","TRUE";
BA_DEF_ BO_  "SCP_FreshnessValueLength" INT 0 512;
BA_DEF_ BO_  "SCP_FreshnessValueTxLength" INT 0 512;
BA_DEF_ BO_  "SCP_AuthInfoTxLength" INT 0 512;
BA_DEF_ BO_  "GenMsgRoutingTimeoutTime" INT 0 5000;
BA_DEF_ BO_  "MessageGateway" ENUM  "No","Yes";
BA_DEF_ BO_  "NmAsrMessage" ENUM  "No","Yes";
BA_DEF_ BO_  "DiagState" ENUM  "No","Yes";
BA_DEF_ BO_  "TpTxIndex" INT 0 536870911;
BA_DEF_ BO_  "DiagRequest" ENUM  "No","Yes";
BA_DEF_ BO_  "DiagResponse" ENUM  "No","Yes";
BA_DEF_ BO_  "GenMsgILSupport" ENUM  "No","Yes";
BA_DEF_DEF_  "FrameRouting" "";
BA_DEF_DEF_  "FrameGatewayNetwork" "NONE";
BA_DEF_DEF_  "NetworkInitialization" "Yes";
BA_DEF_DEF_  "FrameGatewayId" 0;
BA_DEF_DEF_  "EventRateOfChange" 10000;
BA_DEF_DEF_  "GenMsgStartDelayTime" 0;
BA_DEF_DEF_  "GenMsgNrOfRepetition" 1;
BA_DEF_DEF_  "GenMsgDelayTime" 20;
BA_DEF_DEF_  "GenMsgCycleTime" 0;
BA_DEF_DEF_  "GenMsgSendType" "NoMsgSendType";
BA_DEF_DEF_  "U_U55X_MY2022_Tx" "No";
BA_DEF_DEF_  "U_CD542_MY2021_Tx" "No";
BA_DEF_DEF_  "ECGUsedTxSignal" "No";
BA_DEF_DEF_  "U_T6_MCA_MY2020_Tx" "No";
BA_DEF_DEF_  "U_P702_MY2021_Tx" "No";
BA_DEF_DEF_  "U_CX727_MY2021_Tx" "No";
BA_DEF_DEF_  "U_FNV2_IVI_Rx" "No";
BA_DEF_DEF_  "U_U55X_MY2022_Rx" "No";
BA_DEF_DEF_  "U_CD542_MY2021_Rx" "No";
BA_DEF_DEF_  "ECGUsedRxSignal" "No";
BA_DEF_DEF_  "U_T6_MCA_MY2020_Rx" "No";
BA_DEF_DEF_  "U_P702_MY2021_Rx" "No";
BA_DEF_DEF_  "U_CX727_MY2021_Rx" "No";
BA_DEF_DEF_  "GenSigStartValue" 0;
BA_DEF_DEF_  "MetaData" "No";
BA_DEF_DEF_  "ContentDependant" "No";
BA_DEF_DEF_  "GenSigStartValueInteger" 0;
BA_DEF_DEF_  "UsedOnPgmDBC" "Yes";
BA_DEF_DEF_  "WakeupSignal" "No";
BA_DEF_DEF_  "GenSigInactiveValue" 0;
BA_DEF_DEF_  "GenSigSendType" "NoSigSendType";
BA_DEF_DEF_  "OvtpPushApplication" "FALSE";
BA_DEF_DEF_  "SCP_FreshnessValueLength" 64;
BA_DEF_DEF_  "SCP_FreshnessValueTxLength" 11;
BA_DEF_DEF_  "SCP_AuthInfoTxLength" 53;
BA_DEF_DEF_  "GenMsgRoutingTimeoutTime" 0;
BA_DEF_DEF_  "MessageGateway" "No";
BA_DEF_DEF_  "NmAsrMessage" "No";
BA_DEF_DEF_  "DiagState" "No";
BA_DEF_DEF_  "TpTxIndex" 0;
BA_DEF_DEF_  "DiagRequest" "No";
BA_DEF_DEF_  "DiagResponse" "No";
BA_DEF_DEF_  "GenMsgILSupport" "Yes";
BA_ "FrameRouting" BO_ 611 "FD1_CAN,0x263;HS1_CAN,0x263";
BA_ "FrameGatewayNetwork" BO_ 611 "FD1_CAN";
BA_ "FrameGatewayId" BO_ 611 611;
BA_ "GenMsgCycleTime" BO_ 264 1000;
BA_ "GenMsgSendType" BO_ 264 5;
BA_ "GenMsgCycleTime" BO_ 1114 1000;
BA_ "GenMsgSendType" BO_ 1114 5;
BA_ "GenMsgCycleTime" BO_ 968 1000;
BA_ "GenMsgSendType" BO_ 968 5;
BA_ "FrameRouting" BO_ 969 "MS1_CAN,0x3C9;";
BA_ "FrameGatewayNetwork" BO_ 969 "MS1_CAN";
BA_ "FrameGatewayId" BO_ 969 969;
BA_ "FrameRouting" BO_ 1006 "FD1_CAN,0x3EE;HS2_CAN,0x3EE";
BA_ "FrameRouting" BO_ 130 "HS2_CAN,0x81;";
BA_ "FrameGatewayNetwork" BO_ 130 "HS2_CAN";
BA_ "FrameGatewayId" BO_ 130 129;
BA_ "GenMsgCycleTime" BO_ 1244 1000;
BA_ "GenMsgSendType" BO_ 1244 0;
BA_ "GenMsgCycleTime" BO_ 1243 1000;
BA_ "GenMsgSendType" BO_ 1243 0;
BA_ "GenMsgCycleTime" BO_ 681 1000;
BA_ "GenMsgSendType" BO_ 681 5;
BA_ "GenMsgCycleTime" BO_ 744 1000;
BA_ "GenMsgSendType" BO_ 744 5;
BA_ "GenMsgCycleTime" BO_ 741 1000;
BA_ "GenMsgSendType" BO_ 741 5;
BA_ "FrameRouting" BO_ 954 "HS1_CAN,0x3BA;";
BA_ "FrameGatewayNetwork" BO_ 954 "HS1_CAN";
BA_ "FrameGatewayId" BO_ 954 954;
BA_ "FrameRouting" BO_ 125 "FD1_CAN,0x7D;";
BA_ "FrameGatewayNetwork" BO_ 125 "FD1_CAN";
BA_ "FrameGatewayId" BO_ 125 125;
BA_ "MessageGateway" BO_ 125 1;
BA_ "NetworkInitialization" BO_ 2612224096 0;
BA_ "GenMsgDelayTime" BO_ 2612224096 0;
BA_ "GenMsgSendType" BO_ 2612224096 1;
BA_ "OvtpPushApplication" BO_ 2612224096 1;
BA_ "TpTxIndex" BO_ 2612224096 464617688;
BA_ "NetworkInitialization" BO_ 2611052760 0;
BA_ "TpTxIndex" BO_ 2611052760 463569112;
BA_ "NetworkInitialization" BO_ 2611175520 0;
BA_ "GenMsgDelayTime" BO_ 2611175520 0;
BA_ "GenMsgSendType" BO_ 2611175520 1;
BA_ "TpTxIndex" BO_ 2611175520 463569112;
BA_ "NetworkInitialization" BO_ 2610126944 0;
BA_ "GenMsgDelayTime" BO_ 2610126944 0;
BA_ "GenMsgSendType" BO_ 2610126944 1;
BA_ "TpTxIndex" BO_ 2610126944 462520536;
BA_ "NetworkInitialization" BO_ 2610004184 0;
BA_ "GenMsgDelayTime" BO_ 2610004184 0;
BA_ "GenMsgSendType" BO_ 2610004184 1;
BA_ "TpTxIndex" BO_ 2610004184 462520536;
BA_ "NetworkInitialization" BO_ 2005 0;
BA_ "GenMsgDelayTime" BO_ 2005 0;
BA_ "GenMsgSendType" BO_ 2005 1;
BA_ "DiagRequest" BO_ 2005 1;
BA_ "GenMsgILSupport" BO_ 2005 0;
BA_ "NetworkInitialization" BO_ 2013 0;
BA_ "GenMsgDelayTime" BO_ 2013 0;
BA_ "GenMsgSendType" BO_ 2013 1;
BA_ "DiagResponse" BO_ 2013 1;
BA_ "GenMsgILSupport" BO_ 2013 0;
BA_ "NetworkInitialization" BO_ 1519 0;
BA_ "GenMsgCycleTime" BO_ 1519 1000;
BA_ "GenMsgSendType" BO_ 1519 0;
BA_ "NmAsrMessage" BO_ 1519 1;
BA_ "GenMsgILSupport" BO_ 1519 0;
BA_ "NetworkInitialization" BO_ 2612002008 0;
BA_ "GenMsgDelayTime" BO_ 2612002008 0;
BA_ "GenMsgSendType" BO_ 2612002008 1;
BA_ "TpTxIndex" BO_ 2612002008 464518360;
BA_ "NetworkInitialization" BO_ 2610953432 0;
BA_ "GenMsgDelayTime" BO_ 2610953432 0;
BA_ "GenMsgSendType" BO_ 2610953432 1;
BA_ "TpTxIndex" BO_ 2610953432 463469784;
BA_ "GenMsgCycleTime" BO_ 1082 1000;
BA_ "GenMsgSendType" BO_ 1082 5;
BA_ "TpTxIndex" BO_ 576 41;
BA_ "GenMsgCycleTime" BO_ 1115 1000;
BA_ "GenMsgSendType" BO_ 1115 5;
BA_ "GenMsgCycleTime" BO_ 996 1000;
BA_ "GenMsgSendType" BO_ 996 5;
BA_ "TpTxIndex" BO_ 588 45;
BA_ "GenMsgCycleTime" BO_ 811 1000;
BA_ "GenMsgSendType" BO_ 811 5;
BA_ "GenMsgCycleTime" BO_ 543 1000;
BA_ "GenMsgSendType" BO_ 543 0;
BA_ "GenMsgCycleTime" BO_ 563 1000;
BA_ "GenMsgSendType" BO_ 563 5;
BA_ "GenMsgCycleTime" BO_ 794 1000;
BA_ "GenMsgSendType" BO_ 794 5;
BA_ "TpTxIndex" BO_ 587 44;
BA_ "TpTxIndex" BO_ 579 44;
BA_ "TpTxIndex" BO_ 585 42;
BA_ "TpTxIndex" BO_ 586 43;
BA_ "TpTxIndex" BO_ 578 43;
BA_ "TpTxIndex" BO_ 577 42;
BA_ "TpTxIndex" BO_ 712 31;
BA_ "TpTxIndex" BO_ 717 25;
BA_ "TpTxIndex" BO_ 719 24;
BA_ "TpTxIndex" BO_ 589 30;
BA_ "NetworkInitialization" BO_ 1879 0;
BA_ "GenMsgDelayTime" BO_ 1879 0;
BA_ "GenMsgSendType" BO_ 1879 1;
BA_ "DiagRequest" BO_ 1879 1;
BA_ "GenMsgILSupport" BO_ 1879 0;
BA_ "NetworkInitialization" BO_ 1887 0;
BA_ "GenMsgDelayTime" BO_ 1887 0;
BA_ "GenMsgSendType" BO_ 1887 1;
BA_ "DiagResponse" BO_ 1887 1;
BA_ "GenMsgILSupport" BO_ 1887 0;
BA_ "GenMsgCycleTime" BO_ 1146 50;
BA_ "GenMsgSendType" BO_ 1146 0;
BA_ "TpTxIndex" BO_ 737 53;
BA_ "TpTxIndex" BO_ 745 53;
BA_ "TpTxIndex" BO_ 1195 52;
BA_ "NetworkInitialization" BO_ 1435 0;
BA_ "GenMsgCycleTime" BO_ 1435 1000;
BA_ "GenMsgSendType" BO_ 1435 0;
BA_ "NmAsrMessage" BO_ 1435 1;
BA_ "GenMsgILSupport" BO_ 1435 0;
BA_ "GenMsgCycleTime" BO_ 1109 100;
BA_ "GenMsgSendType" BO_ 1109 5;
BA_ "NetworkInitialization" BO_ 1492 0;
BA_ "GenMsgCycleTime" BO_ 1492 1000;
BA_ "GenMsgSendType" BO_ 1492 0;
BA_ "NmAsrMessage" BO_ 1492 1;
BA_ "GenMsgILSupport" BO_ 1492 0;
BA_ "NetworkInitialization" BO_ 1945 0;
BA_ "GenMsgDelayTime" BO_ 1945 0;
BA_ "GenMsgSendType" BO_ 1945 1;
BA_ "DiagResponse" BO_ 1945 1;
BA_ "GenMsgILSupport" BO_ 1945 0;
BA_ "NetworkInitialization" BO_ 1937 0;
BA_ "GenMsgDelayTime" BO_ 1937 0;
BA_ "GenMsgSendType" BO_ 1937 1;
BA_ "DiagRequest" BO_ 1937 1;
BA_ "GenMsgILSupport" BO_ 1937 0;
BA_ "GenMsgCycleTime" BO_ 140 1000;
BA_ "GenMsgSendType" BO_ 140 5;
BA_ "GenMsgCycleTime" BO_ 546 1000;
BA_ "GenMsgSendType" BO_ 546 5;
BA_ "FrameRouting" BO_ 1186 "FD1_CAN,0x4A2;";
BA_ "FrameGatewayNetwork" BO_ 1186 "FD1_CAN";
BA_ "FrameGatewayId" BO_ 1186 1186;
BA_ "GenMsgCycleTime" BO_ 1130 1000;
BA_ "GenMsgSendType" BO_ 1130 5;
BA_ "GenMsgCycleTime" BO_ 1042 50;
BA_ "GenMsgSendType" BO_ 1042 0;
BA_ "GenMsgCycleTime" BO_ 1093 100;
BA_ "GenMsgSendType" BO_ 1093 0;
BA_ "FrameRouting" BO_ 1138 "FD1_CAN,0x472;HS1_CAN,0x472";
BA_ "FrameRouting" BO_ 1139 "FD1_CAN,0x473;HS1_CAN,0x473";
BA_ "FrameRouting" BO_ 1145 "FD1_CAN,0x352;HS1_CAN,0x352";
BA_ "GenMsgCycleTime" BO_ 1232 1000;
BA_ "GenMsgSendType" BO_ 1232 0;
BA_ "FrameRouting" BO_ 1141 "FD1_CAN,0x475;HS1_CAN,0x475";
BA_ "GenMsgCycleTime" BO_ 631 1000;
BA_ "GenMsgSendType" BO_ 631 5;
BA_ "FrameRouting" BO_ 1140 "FD1_CAN,0x474;HS1_CAN,0x474";
BA_ "FrameRouting" BO_ 873 "FD1_CAN,0x369;HS1_CAN,0x369";
BA_ "FrameRouting" BO_ 871 "FD1_CAN,0x367;HS1_CAN,0x367";
BA_ "FrameRouting" BO_ 870 "FD1_CAN,0x366;HS1_CAN,0x366";
BA_ "FrameRouting" BO_ 869 "FD1_CAN,0x365;HS1_CAN,0x365";
BA_ "FrameRouting" BO_ 786 "FD1_CAN,0x312;HS1_CAN,0x312";
BA_ "FrameRouting" BO_ 1095 "HS1_CAN,0x447;";
BA_ "FrameGatewayNetwork" BO_ 1095 "HS1_CAN";
BA_ "FrameGatewayId" BO_ 1095 1095;
BA_ "TpTxIndex" BO_ 684 29;
BA_ "FrameRouting" BO_ 872 "HS1_CAN,0x368;";
BA_ "FrameGatewayNetwork" BO_ 872 "HS1_CAN";
BA_ "FrameGatewayId" BO_ 872 872;
BA_ "GenMsgCycleTime" BO_ 791 1000;
BA_ "GenMsgSendType" BO_ 791 5;
BA_ "FrameRouting" BO_ 358 "FD1_CAN,0x166;HS1_CAN,0x166";
BA_ "FrameGatewayNetwork" BO_ 358 "FD1_CAN";
BA_ "FrameGatewayId" BO_ 358 358;
BA_ "GenMsgCycleTime" BO_ 840 1000;
BA_ "GenMsgSendType" BO_ 840 5;
BA_ "FrameRouting" BO_ 945 "HS1_CAN,0x3B1;";
BA_ "FrameGatewayNetwork" BO_ 945 "HS1_CAN";
BA_ "FrameGatewayId" BO_ 945 945;
BA_ "GenMsgCycleTime" BO_ 740 1000;
BA_ "GenMsgSendType" BO_ 740 5;
BA_ "FrameRouting" BO_ 1055 "FD1_CAN,0x41F;HS1_CAN,0x41F";
BA_ "FrameGatewayNetwork" BO_ 1055 "FD1_CAN";
BA_ "FrameGatewayId" BO_ 1055 1055;
BA_ "FrameRouting" BO_ 361 "HS2_CAN,0x169;";
BA_ "FrameGatewayNetwork" BO_ 361 "HS2_CAN";
BA_ "FrameGatewayId" BO_ 361 361;
BA_ "U_CD542_MY2021_Rx" SG_ 611 AwdTerrMdeChng_D_Rdy 1;
BA_ "U_T6_MCA_MY2020_Rx" SG_ 611 AwdTerrMdeChng_D_Rdy 1;
BA_ "U_CD542_MY2021_Rx" SG_ 611 AwdTerrMde_D_Actl 1;
BA_ "U_T6_MCA_MY2020_Rx" SG_ 611 AwdTerrMde_D_Actl 1;
BA_ "U_CD542_MY2021_Rx" SG_ 611 AwdSys_D_Stat 1;
BA_ "U_T6_MCA_MY2020_Rx" SG_ 611 AwdSys_D_Stat 1;
BA_ "U_CD542_MY2021_Rx" SG_ 611 AwdStat_D_RqDsply 1;
BA_ "U_T6_MCA_MY2020_Rx" SG_ 611 AwdStat_D_RqDsply 1;
BA_ "U_P702_MY2021_Rx" SG_ 611 AwdStat_D_RqDsply 1;
BA_ "ContentDependant" SG_ 611 AwdStat_D_RqDsply 1;
BA_ "U_CD542_MY2021_Rx" SG_ 611 AwdLck_D_Stat 1;
BA_ "U_T6_MCA_MY2020_Rx" SG_ 611 AwdLck_D_Stat 1;
BA_ "U_P702_MY2021_Rx" SG_ 611 AwdLck_D_Stat 1;
BA_ "U_CD542_MY2021_Rx" SG_ 611 AwdSrvcRqd_B_Rq 1;
BA_ "U_T6_MCA_MY2020_Rx" SG_ 611 AwdSrvcRqd_B_Rq 1;
BA_ "U_P702_MY2021_Rx" SG_ 611 AwdSrvcRqd_B_Rq 1;
BA_ "ContentDependant" SG_ 611 AwdSrvcRqd_B_Rq 1;
BA_ "U_CD542_MY2021_Rx" SG_ 611 AwdLck_Tq_Rq 1;
BA_ "U_T6_MCA_MY2020_Rx" SG_ 611 AwdLck_Tq_Rq 1;
BA_ "U_P702_MY2021_Rx" SG_ 611 AwdLck_Tq_Rq 1;
BA_ "ContentDependant" SG_ 611 AwdLck_Tq_Rq 1;
BA_ "U_CD542_MY2021_Rx" SG_ 611 TrnAout_Tq_RqMx 1;
BA_ "U_T6_MCA_MY2020_Rx" SG_ 611 TrnAout_Tq_RqMx 1;
BA_ "GenSigStartValue" SG_ 611 TrnAout_Tq_RqMx 8191;
BA_ "GenSigStartValueInteger" SG_ 611 TrnAout_Tq_RqMx 8191;
BA_ "U_T6_MCA_MY2020_Rx" SG_ 611 AwdOffRoadMode_D_Stats 1;
BA_ "U_P702_MY2021_Rx" SG_ 611 AwdOffRoadMode_D_Stats 1;
BA_ "U_CD542_MY2021_Rx" SG_ 611 AwdOffRoadMode_D_Stats 1;
BA_ "U_CD542_MY2021_Rx" SG_ 611 AwdLoLamp_D_RqDsply 1;
BA_ "U_T6_MCA_MY2020_Rx" SG_ 611 AwdLoLamp_D_RqDsply 1;
BA_ "U_P702_MY2021_Rx" SG_ 611 AwdLoLamp_D_RqDsply 1;
BA_ "U_CD542_MY2021_Rx" SG_ 611 AwdHiLamp_D_RqDsply 1;
BA_ "U_T6_MCA_MY2020_Rx" SG_ 611 AwdHiLamp_D_RqDsply 1;
BA_ "U_P702_MY2021_Rx" SG_ 611 AwdHiLamp_D_RqDsply 1;
BA_ "U_CD542_MY2021_Rx" SG_ 611 AwdAutoLamp_D_RqDsply 1;
BA_ "U_T6_MCA_MY2020_Rx" SG_ 611 AwdAutoLamp_D_RqDsply 1;
BA_ "U_P702_MY2021_Rx" SG_ 611 AwdAutoLamp_D_RqDsply 1;
BA_ "U_CD542_MY2021_Rx" SG_ 611 Awd2wdLamp_D_RqDsply 1;
BA_ "U_T6_MCA_MY2020_Rx" SG_ 611 Awd2wdLamp_D_RqDsply 1;
BA_ "U_P702_MY2021_Rx" SG_ 611 Awd2wdLamp_D_RqDsply 1;
BA_ "U_CD542_MY2021_Rx" SG_ 611 AwdRnge_D_Actl 1;
BA_ "U_T6_MCA_MY2020_Rx" SG_ 611 AwdRnge_D_Actl 1;
BA_ "U_P702_MY2021_Rx" SG_ 611 AwdRnge_D_Actl 1;
BA_ "GenSigStartValue" SG_ 611 AwdRnge_D_Actl 7;
BA_ "GenSigStartValueInteger" SG_ 611 AwdRnge_D_Actl 7;
BA_ "U_CD542_MY2021_Rx" SG_ 611 NtrlTowAvail_B_Stat 1;
BA_ "U_T6_MCA_MY2020_Rx" SG_ 611 NtrlTowAvail_B_Stat 1;
BA_ "U_P702_MY2021_Rx" SG_ 611 NtrlTowAvail_B_Stat 1;
BA_ "U_CD542_MY2021_Rx" SG_ 611 AwdDrvMde_D_Stat 1;
BA_ "U_T6_MCA_MY2020_Rx" SG_ 611 AwdDrvMde_D_Stat 1;
BA_ "U_T6_MCA_MY2020_Rx" SG_ 264 CabnAmb_Te_Actl_UB 1;
BA_ "U_CD542_MY2021_Rx" SG_ 264 CabnAmb_Te_Actl 1;
BA_ "U_T6_MCA_MY2020_Rx" SG_ 264 CabnAmb_Te_Actl 1;
BA_ "GenSigStartValueInteger" SG_ 264 CabnAmb_Te_Actl 114;
BA_ "U_T6_MCA_MY2020_Rx" SG_ 264 ChrgCordLck_D_Stat_UB 1;
BA_ "U_P702_MY2021_Rx" SG_ 264 ChrgCordLck_D_Stat_UB 1;
BA_ "U_T6_MCA_MY2020_Rx" SG_ 264 ChrgCordLck_D_Stat 1;
BA_ "U_P702_MY2021_Rx" SG_ 264 ChrgCordLck_D_Stat 1;
BA_ "U_CD542_MY2021_Rx" SG_ 264 PwPckTqRdy_B_Dsply 1;
BA_ "U_T6_MCA_MY2020_Rx" SG_ 264 PwPckTqRdy_B_Dsply 1;
BA_ "U_P702_MY2021_Rx" SG_ 264 PwPckTqRdy_B_Dsply 1;
BA_ "U_CD542_MY2021_Rx" SG_ 264 HtrnOvrTeLamp_B_Dsply_UB 1;
BA_ "U_T6_MCA_MY2020_Rx" SG_ 264 HtrnOvrTeLamp_B_Dsply_UB 1;
BA_ "U_P702_MY2021_Rx" SG_ 264 HtrnOvrTeLamp_B_Dsply_UB 1;
BA_ "U_CD542_MY2021_Rx" SG_ 264 HtrnOvrTeLamp_B_Dsply 1;
BA_ "U_T6_MCA_MY2020_Rx" SG_ 264 HtrnOvrTeLamp_B_Dsply 1;
BA_ "U_P702_MY2021_Rx" SG_ 264 HtrnOvrTeLamp_B_Dsply 1;
BA_ "U_T6_MCA_MY2020_Rx" SG_ 264 PwPckTqRdy_B_Dsply_UB 1;
BA_ "U_P702_MY2021_Rx" SG_ 264 PwPckTqRdy_B_Dsply_UB 1;
BA_ "U_CD542_MY2021_Rx" SG_ 264 BpedDrvAppl_D_Actl 1;
BA_ "U_T6_MCA_MY2020_Rx" SG_ 264 BpedDrvAppl_D_Actl 1;
BA_ "U_P702_MY2021_Rx" SG_ 264 BpedDrvAppl_D_Actl 1;
BA_ "GenSigSendType" SG_ 264 BpedDrvAppl_D_Actl 3;
BA_ "GenSigStartValue" SG_ 264 BpedDrvAppl_D_Actl 1;
BA_ "GenSigStartValueInteger" SG_ 264 BpedDrvAppl_D_Actl 1;
BA_ "U_CD542_MY2021_Rx" SG_ 264 BpedDrvAppl_D_Actl_UB 1;
BA_ "U_T6_MCA_MY2020_Rx" SG_ 264 BpedDrvAppl_D_Actl_UB 1;
BA_ "U_P702_MY2021_Rx" SG_ 264 BpedDrvAppl_D_Actl_UB 1;
BA_ "U_CD542_MY2021_Rx" SG_ 264 BattTracSoc_Pc_Dsply_UB 1;
BA_ "U_T6_MCA_MY2020_Rx" SG_ 264 BattTracSoc_Pc_Dsply_UB 1;
BA_ "U_P702_MY2021_Rx" SG_ 264 BattTracSoc_Pc_Dsply_UB 1;
BA_ "U_CD542_MY2021_Rx" SG_ 264 BattTracSoc_Pc_Dsply 1;
BA_ "U_T6_MCA_MY2020_Rx" SG_ 264 BattTracSoc_Pc_Dsply 1;
BA_ "U_P702_MY2021_Rx" SG_ 264 BattTracSoc_Pc_Dsply 1;
BA_ "GenSigStartValue" SG_ 264 BattTracSoc_Pc_Dsply 254;
BA_ "GenSigStartValueInteger" SG_ 264 BattTracSoc_Pc_Dsply 254;
BA_ "U_CD542_MY2021_Tx" SG_ 1114 TrailCtlSwtch_B_Stat2 1;
BA_ "U_P702_MY2021_Tx" SG_ 1114 TrailCtlSwtch_B_Stat2 1;
BA_ "GenSigSendType" SG_ 1114 TrailCtlSwtch_B_Stat2 3;
BA_ "U_CD542_MY2021_Tx" SG_ 1114 TrlBrkInitOut_D_Rq 1;
BA_ "U_T6_MCA_MY2020_Rx" SG_ 1114 TrlBrkInitOut_D_Rq 1;
BA_ "U_P702_MY2021_Rx" SG_ 1114 TrlBrkInitOut_D_Rq 1;
BA_ "GenSigSendType" SG_ 1114 TrlBrkInitOut_D_Rq 3;
BA_ "U_CD542_MY2021_Tx" SG_ 968 RvltnMatchAllw_D_Rq 1;
BA_ "U_T6_MCA_MY2020_Tx" SG_ 968 RvltnMatchAllw_D_Rq 1;
BA_ "GenSigSendType" SG_ 968 RvltnMatchAllw_D_Rq 3;
BA_ "U_CD542_MY2021_Tx" SG_ 968 BrkDrvMde_D_Rq 1;
BA_ "U_T6_MCA_MY2020_Tx" SG_ 968 BrkDrvMde_D_Rq 1;
BA_ "GenSigSendType" SG_ 968 BrkDrvMde_D_Rq 3;
BA_ "GenSigSendType" SG_ 968 LnchCtl_N_Rq 3;
BA_ "GenSigSendType" SG_ 968 LnchCtl_D_Rq 3;
BA_ "GenSigSendType" SG_ 968 CurrentColor_CmdGage 3;
BA_ "GenSigStartValue" SG_ 968 CurrentColor_CmdGage 8;
BA_ "GenSigStartValueInteger" SG_ 968 CurrentColor_CmdGage 8;
BA_ "GenSigSendType" SG_ 968 BlendedColor_CmdGage 3;
BA_ "GenSigStartValue" SG_ 968 BlendedColor_CmdGage 2;
BA_ "GenSigStartValueInteger" SG_ 968 BlendedColor_CmdGage 2;
BA_ "GenSigSendType" SG_ 968 BlendColorRed_CmdGage 3;
BA_ "GenSigSendType" SG_ 968 BlendColorGrn_CmdGage 3;
BA_ "GenSigSendType" SG_ 968 BlendColorBlue_CmdGage 3;
BA_ "GenSigSendType" SG_ 968 Dimming_Level_Cmd 3;
BA_ "GenSigSendType" SG_ 968 Current_Color_Cmd 3;
BA_ "GenSigStartValue" SG_ 968 Current_Color_Cmd 8;
BA_ "GenSigStartValueInteger" SG_ 968 Current_Color_Cmd 8;
BA_ "GenSigSendType" SG_ 968 BlendedColorRed_Cmd 3;
BA_ "GenSigSendType" SG_ 968 BlendedColorGreen_Cmd 3;
BA_ "GenSigSendType" SG_ 968 BlendedColorBlue_Cmd 3;
BA_ "GenSigSendType" SG_ 968 BlendedColor_Cmd 3;
BA_ "GenSigStartValue" SG_ 968 BlendedColor_Cmd 2;
BA_ "GenSigStartValueInteger" SG_ 968 BlendedColor_Cmd 2;
BA_ "U_T6_MCA_MY2020_Tx" SG_ 968 SuspDrvMde_D_Rq 1;
BA_ "GenSigSendType" SG_ 968 SuspDrvMde_D_Rq 3;
BA_ "U_CD542_MY2021_Tx" SG_ 968 SlMde_D_Rq 1;
BA_ "U_T6_MCA_MY2020_Tx" SG_ 968 SlMde_D_Rq 1;
BA_ "U_P702_MY2021_Tx" SG_ 968 SlMde_D_Rq 1;
BA_ "GenSigSendType" SG_ 968 SlMde_D_Rq 3;
BA_ "GenSigStartValue" SG_ 968 SlMde_D_Rq 2;
BA_ "GenSigStartValueInteger" SG_ 968 SlMde_D_Rq 2;
BA_ "U_CD542_MY2021_Tx" SG_ 968 IsaOffst_D_Rq 1;
BA_ "U_T6_MCA_MY2020_Tx" SG_ 968 IsaOffst_D_Rq 1;
BA_ "U_P702_MY2021_Tx" SG_ 968 IsaOffst_D_Rq 1;
BA_ "GenSigSendType" SG_ 968 IsaOffst_D_Rq 3;
BA_ "GenSigStartValue" SG_ 968 IsaOffst_D_Rq 14;
BA_ "GenSigStartValueInteger" SG_ 968 IsaOffst_D_Rq 14;
BA_ "U_T6_MCA_MY2020_Rx" SG_ 969 Dimming_Level_Stat 1;
BA_ "U_T6_MCA_MY2020_Rx" SG_ 969 Current_Color_Stat 1;
BA_ "GenSigStartValue" SG_ 969 Current_Color_Stat 8;
BA_ "GenSigStartValueInteger" SG_ 969 Current_Color_Stat 8;
BA_ "U_T6_MCA_MY2020_Rx" SG_ 969 BlendedColorRed_Stat 1;
BA_ "U_T6_MCA_MY2020_Rx" SG_ 969 BlendedColorGreen_Stat 1;
BA_ "U_T6_MCA_MY2020_Rx" SG_ 969 BlendedColorBlue_Stat 1;
BA_ "U_T6_MCA_MY2020_Rx" SG_ 969 BlendedColor_Stat 1;
BA_ "GenSigStartValue" SG_ 969 BlendedColor_Stat 2;
BA_ "GenSigStartValueInteger" SG_ 969 BlendedColor_Stat 2;
BA_ "U_T6_MCA_MY2020_Rx" SG_ 969 TurnLampRrOut_B_Stat 1;
BA_ "ContentDependant" SG_ 969 TurnLampRrOut_B_Stat 1;
BA_ "WakeupSignal" SG_ 969 TurnLampRrOut_B_Stat 1;
BA_ "U_T6_MCA_MY2020_Rx" SG_ 969 TurnLampRlOut_B_Stat 1;
BA_ "ContentDependant" SG_ 969 TurnLampRlOut_B_Stat 1;
BA_ "WakeupSignal" SG_ 969 TurnLampRlOut_B_Stat 1;
BA_ "U_CD542_MY2021_Rx" SG_ 1006 PersIndexIpmb_D_Actl 1;
BA_ "U_T6_MCA_MY2020_Rx" SG_ 1006 PersIndexIpmb_D_Actl 1;
BA_ "GenSigStartValue" SG_ 1006 PersIndexIpmb_D_Actl 4;
BA_ "GenSigStartValueInteger" SG_ 1006 PersIndexIpmb_D_Actl 4;
BA_ "U_CD542_MY2021_Rx" SG_ 1006 FeatNoIpmbActl 1;
BA_ "U_P702_MY2021_Rx" SG_ 1006 FeatNoIpmbActl 1;
BA_ "U_T6_MCA_MY2020_Rx" SG_ 1006 FeatNoIpmbActl 1;
BA_ "U_CD542_MY2021_Rx" SG_ 1006 FeatConfigIpmbActl 1;
BA_ "U_P702_MY2021_Rx" SG_ 1006 FeatConfigIpmbActl 1;
BA_ "U_T6_MCA_MY2020_Rx" SG_ 1006 FeatConfigIpmbActl 1;
BA_ "U_CD542_MY2021_Rx" SG_ 130 SteWhlSwtchHome_B_Stat 1;
BA_ "U_T6_MCA_MY2020_Rx" SG_ 130 SteWhlSwtchHome_B_Stat 1;
BA_ "U_P702_MY2021_Rx" SG_ 130 SteWhlSwtchHome_B_Stat 1;
BA_ "U_CD542_MY2021_Rx" SG_ 130 SteWhlSwtchInfo_B_Stat 1;
BA_ "U_T6_MCA_MY2020_Rx" SG_ 130 SteWhlSwtchInfo_B_Stat 1;
BA_ "ContentDependant" SG_ 130 SelDrvMdeSwtch3_D_Stat4 1;
BA_ "U_CD542_MY2021_Rx" SG_ 130 SteWhlSwtchView_B_Stat 1;
BA_ "U_T6_MCA_MY2020_Rx" SG_ 130 SteWhlSwtchView_B_Stat 1;
BA_ "WakeupSignal" SG_ 130 SteWhlSwtchView_B_Stat 1;
BA_ "U_CD542_MY2021_Rx" SG_ 130 SteWhlSwtchSet_B_Stat 1;
BA_ "U_T6_MCA_MY2020_Rx" SG_ 130 SteWhlSwtchSet_B_Stat 1;
BA_ "WakeupSignal" SG_ 130 SteWhlSwtchSet_B_Stat 1;
BA_ "U_CD542_MY2021_Rx" SG_ 130 SteWhlSwtchPhon_B_Stat 1;
BA_ "U_T6_MCA_MY2020_Rx" SG_ 130 SteWhlSwtchPhon_B_Stat 1;
BA_ "WakeupSignal" SG_ 130 SteWhlSwtchPhon_B_Stat 1;
BA_ "U_CD542_MY2021_Rx" SG_ 130 SteWhlSwtchNav_B_Stat 1;
BA_ "U_T6_MCA_MY2020_Rx" SG_ 130 SteWhlSwtchNav_B_Stat 1;
BA_ "WakeupSignal" SG_ 130 SteWhlSwtchNav_B_Stat 1;
BA_ "U_CD542_MY2021_Rx" SG_ 130 SteWhlSwtchMed_B_Stat 1;
BA_ "U_T6_MCA_MY2020_Rx" SG_ 130 SteWhlSwtchMed_B_Stat 1;
BA_ "WakeupSignal" SG_ 130 SteWhlSwtchMed_B_Stat 1;
BA_ "U_CD542_MY2021_Rx" SG_ 130 SteWhlSwtchIod_B_Stat 1;
BA_ "U_T6_MCA_MY2020_Rx" SG_ 130 SteWhlSwtchIod_B_Stat 1;
BA_ "WakeupSignal" SG_ 130 SteWhlSwtchIod_B_Stat 1;
BA_ "U_CD542_MY2021_Rx" SG_ 130 SteWhlSwtchHud_B_Stat 1;
BA_ "U_T6_MCA_MY2020_Rx" SG_ 130 SteWhlSwtchHud_B_Stat 1;
BA_ "WakeupSignal" SG_ 130 SteWhlSwtchHud_B_Stat 1;
BA_ "U_CD542_MY2021_Rx" SG_ 130 SteWhlSwtchBack_B_Stat 1;
BA_ "U_P702_MY2021_Rx" SG_ 130 SteWhlSwtchBack_B_Stat 1;
BA_ "U_T6_MCA_MY2020_Rx" SG_ 130 SteWhlSwtchBack_B_Stat 1;
BA_ "WakeupSignal" SG_ 130 SteWhlSwtchBack_B_Stat 1;
BA_ "U_CD542_MY2021_Rx" SG_ 130 SteWhlSwtchMenu_B_Stat 1;
BA_ "U_T6_MCA_MY2020_Rx" SG_ 130 SteWhlSwtchMenu_B_Stat 1;
BA_ "U_P702_MY2021_Rx" SG_ 130 SteWhlSwtchMenu_B_Stat 1;
BA_ "WakeupSignal" SG_ 130 SteWhlSwtchMenu_B_Stat 1;
BA_ "U_CD542_MY2021_Rx" SG_ 130 SteEffortInc_B_RqDrv 1;
BA_ "U_T6_MCA_MY2020_Rx" SG_ 130 SteEffortInc_B_RqDrv 1;
BA_ "U_CD542_MY2021_Rx" SG_ 130 SelDrvMdeInc_B_RqDrv 1;
BA_ "U_T6_MCA_MY2020_Rx" SG_ 130 SelDrvMdeInc_B_RqDrv 1;
BA_ "U_CD542_MY2021_Rx" SG_ 130 SelDrvMdeDec_B_RqDrv 1;
BA_ "U_T6_MCA_MY2020_Rx" SG_ 130 SelDrvMdeDec_B_RqDrv 1;
BA_ "U_CD542_MY2021_Rx" SG_ 130 SuspDampInc_B_RqDrv 1;
BA_ "U_T6_MCA_MY2020_Rx" SG_ 130 SuspDampInc_B_RqDrv 1;
BA_ "U_CD542_MY2021_Rx" SG_ 130 SteWhlSwtchUp_B_Stat 1;
BA_ "U_T6_MCA_MY2020_Rx" SG_ 130 SteWhlSwtchUp_B_Stat 1;
BA_ "U_P702_MY2021_Rx" SG_ 130 SteWhlSwtchUp_B_Stat 1;
BA_ "WakeupSignal" SG_ 130 SteWhlSwtchUp_B_Stat 1;
BA_ "U_CD542_MY2021_Rx" SG_ 130 SteWhlSwtchRght_B_Stat 1;
BA_ "U_T6_MCA_MY2020_Rx" SG_ 130 SteWhlSwtchRght_B_Stat 1;
BA_ "WakeupSignal" SG_ 130 SteWhlSwtchRght_B_Stat 1;
BA_ "U_CD542_MY2021_Rx" SG_ 130 SteWhlSwtchOk_B_Stat 1;
BA_ "U_T6_MCA_MY2020_Rx" SG_ 130 SteWhlSwtchOk_B_Stat 1;
BA_ "U_P702_MY2021_Rx" SG_ 130 SteWhlSwtchOk_B_Stat 1;
BA_ "WakeupSignal" SG_ 130 SteWhlSwtchOk_B_Stat 1;
BA_ "U_CD542_MY2021_Rx" SG_ 130 SteWhlSwtchLeft_B_Stat 1;
BA_ "U_T6_MCA_MY2020_Rx" SG_ 130 SteWhlSwtchLeft_B_Stat 1;
BA_ "WakeupSignal" SG_ 130 SteWhlSwtchLeft_B_Stat 1;
BA_ "U_CD542_MY2021_Rx" SG_ 130 SteWhlSwtchDown_B_Stat 1;
BA_ "U_T6_MCA_MY2020_Rx" SG_ 130 SteWhlSwtchDown_B_Stat 1;
BA_ "U_P702_MY2021_Rx" SG_ 130 SteWhlSwtchDown_B_Stat 1;
BA_ "WakeupSignal" SG_ 130 SteWhlSwtchDown_B_Stat 1;
BA_ "U_T6_MCA_MY2020_Tx" SG_ 1244 Con_InfotainmentVer_St 1;
BA_ "U_T6_MCA_MY2020_Tx" SG_ 1244 Con_Profiles_St 1;
BA_ "U_T6_MCA_MY2020_Tx" SG_ 1244 Con_Configuration 1;
BA_ "U_T6_MCA_MY2020_Tx" SG_ 1243 Con_BTAud_InfotainmVer_St 1;
BA_ "U_T6_MCA_MY2020_Tx" SG_ 1243 Con_BTAud_Profiles_St 1;
BA_ "U_T6_MCA_MY2020_Tx" SG_ 1243 Con_BTAudConfiguration 1;
BA_ "U_T6_MCA_MY2020_Tx" SG_ 681 Con_DB1temIndex_St 1;
BA_ "GenSigSendType" SG_ 681 Con_DB1temIndex_St 1;
BA_ "U_T6_MCA_MY2020_Tx" SG_ 681 Con_DB1FilterConfig_St 1;
BA_ "U_T6_MCA_MY2020_Tx" SG_ 681 Con_DB1Filter3_St 1;
BA_ "U_T6_MCA_MY2020_Tx" SG_ 681 Con_DB1Filter2_St 1;
BA_ "U_T6_MCA_MY2020_Tx" SG_ 681 Con_DB1Filter1_St 1;
BA_ "U_T6_MCA_MY2020_Tx" SG_ 744 Con_USB_ActTrNum1_St 1;
BA_ "U_T6_MCA_MY2020_Rx" SG_ 744 Con_USB_ActTrNum1_St 1;
BA_ "GenSigSendType" SG_ 744 Con_USB_ActTrNum1_St 3;
BA_ "U_T6_MCA_MY2020_Tx" SG_ 744 Con_iPod_NumberOfTracks 1;
BA_ "U_T6_MCA_MY2020_Rx" SG_ 744 Con_iPod_NumberOfTracks 1;
BA_ "GenSigSendType" SG_ 744 Con_iPod_NumberOfTracks 3;
BA_ "U_T6_MCA_MY2020_Tx" SG_ 744 Con_USB_NumberOfTracks 1;
BA_ "U_T6_MCA_MY2020_Rx" SG_ 744 Con_USB_NumberOfTracks 1;
BA_ "GenSigSendType" SG_ 744 Con_USB_NumberOfTracks 3;
BA_ "U_T6_MCA_MY2020_Tx" SG_ 741 Con_USB_Playtype_St 1;
BA_ "U_CD542_MY2021_Rx" SG_ 741 Con_USB_Playtype_St 1;
BA_ "U_T6_MCA_MY2020_Rx" SG_ 741 Con_USB_Playtype_St 1;
BA_ "GenSigSendType" SG_ 741 Con_USB_Playtype_St 3;
BA_ "U_T6_MCA_MY2020_Tx" SG_ 741 Con_ShowSWDLBargr_St 1;
BA_ "U_CD542_MY2021_Rx" SG_ 741 Con_ShowSWDLBargr_St 1;
BA_ "U_T6_MCA_MY2020_Rx" SG_ 741 Con_ShowSWDLBargr_St 1;
BA_ "U_T6_MCA_MY2020_Tx" SG_ 741 Con_ShowSWDLprogress_St 1;
BA_ "U_CD542_MY2021_Rx" SG_ 741 Con_ShowSWDLprogress_St 1;
BA_ "U_T6_MCA_MY2020_Rx" SG_ 741 Con_ShowSWDLprogress_St 1;
BA_ "GenSigSendType" SG_ 741 Con_ShowSWDLprogress_St 3;
BA_ "U_T6_MCA_MY2020_Tx" SG_ 741 Con_iPod_IntroScan_St 1;
BA_ "U_CD542_MY2021_Rx" SG_ 741 Con_iPod_IntroScan_St 1;
BA_ "U_T6_MCA_MY2020_Rx" SG_ 741 Con_iPod_IntroScan_St 1;
BA_ "GenSigSendType" SG_ 741 Con_iPod_IntroScan_St 3;
BA_ "U_T6_MCA_MY2020_Tx" SG_ 741 Con_iPod_Shuffle_St 1;
BA_ "U_CD542_MY2021_Rx" SG_ 741 Con_iPod_Shuffle_St 1;
BA_ "U_T6_MCA_MY2020_Rx" SG_ 741 Con_iPod_Shuffle_St 1;
BA_ "GenSigSendType" SG_ 741 Con_iPod_Shuffle_St 3;
BA_ "U_T6_MCA_MY2020_Tx" SG_ 741 Con_iPod_Repeat_St 1;
BA_ "U_CD542_MY2021_Rx" SG_ 741 Con_iPod_Repeat_St 1;
BA_ "U_T6_MCA_MY2020_Rx" SG_ 741 Con_iPod_Repeat_St 1;
BA_ "GenSigSendType" SG_ 741 Con_iPod_Repeat_St 3;
BA_ "U_T6_MCA_MY2020_Tx" SG_ 741 Con_USB_Repeat_St 1;
BA_ "U_CD542_MY2021_Rx" SG_ 741 Con_USB_Repeat_St 1;
BA_ "U_T6_MCA_MY2020_Rx" SG_ 741 Con_USB_Repeat_St 1;
BA_ "GenSigSendType" SG_ 741 Con_USB_Repeat_St 3;
BA_ "U_T6_MCA_MY2020_Tx" SG_ 741 Con_USB_IntroScan_St 1;
BA_ "U_CD542_MY2021_Rx" SG_ 741 Con_USB_IntroScan_St 1;
BA_ "U_T6_MCA_MY2020_Rx" SG_ 741 Con_USB_IntroScan_St 1;
BA_ "GenSigSendType" SG_ 741 Con_USB_IntroScan_St 3;
BA_ "U_T6_MCA_MY2020_Tx" SG_ 741 Con_USB_Shuffle_St 1;
BA_ "U_CD542_MY2021_Rx" SG_ 741 Con_USB_Shuffle_St 1;
BA_ "U_T6_MCA_MY2020_Rx" SG_ 741 Con_USB_Shuffle_St 1;
BA_ "GenSigSendType" SG_ 741 Con_USB_Shuffle_St 3;
BA_ "U_T6_MCA_MY2020_Tx" SG_ 741 Con_iPod_Error_St 1;
BA_ "U_CD542_MY2021_Rx" SG_ 741 Con_iPod_Error_St 1;
BA_ "U_T6_MCA_MY2020_Rx" SG_ 741 Con_iPod_Error_St 1;
BA_ "GenSigSendType" SG_ 741 Con_iPod_Error_St 3;
BA_ "U_T6_MCA_MY2020_Tx" SG_ 741 Con_USB_Error_St 1;
BA_ "U_CD542_MY2021_Rx" SG_ 741 Con_USB_Error_St 1;
BA_ "U_T6_MCA_MY2020_Rx" SG_ 741 Con_USB_Error_St 1;
BA_ "GenSigSendType" SG_ 741 Con_USB_Error_St 3;
BA_ "U_T6_MCA_MY2020_Tx" SG_ 741 Con_iPod_FunctStatus_St 1;
BA_ "U_CD542_MY2021_Rx" SG_ 741 Con_iPod_FunctStatus_St 1;
BA_ "U_T6_MCA_MY2020_Rx" SG_ 741 Con_iPod_FunctStatus_St 1;
BA_ "GenSigSendType" SG_ 741 Con_iPod_FunctStatus_St 3;
BA_ "U_T6_MCA_MY2020_Tx" SG_ 741 Con_USB_FunctStatus_St 1;
BA_ "U_CD542_MY2021_Rx" SG_ 741 Con_USB_FunctStatus_St 1;
BA_ "U_T6_MCA_MY2020_Rx" SG_ 741 Con_USB_FunctStatus_St 1;
BA_ "GenSigSendType" SG_ 741 Con_USB_FunctStatus_St 3;
BA_ "U_T6_MCA_MY2020_Tx" SG_ 741 Con_USB_OpMode_St 1;
BA_ "U_CD542_MY2021_Rx" SG_ 741 Con_USB_OpMode_St 1;
BA_ "U_T6_MCA_MY2020_Rx" SG_ 741 Con_USB_OpMode_St 1;
BA_ "GenSigSendType" SG_ 741 Con_USB_OpMode_St 3;
BA_ "U_T6_MCA_MY2020_Tx" SG_ 741 Con_iPod_OpMode_St 1;
BA_ "U_CD542_MY2021_Rx" SG_ 741 Con_iPod_OpMode_St 1;
BA_ "U_T6_MCA_MY2020_Rx" SG_ 741 Con_iPod_OpMode_St 1;
BA_ "GenSigSendType" SG_ 741 Con_iPod_OpMode_St 3;
BA_ "U_CD542_MY2021_Rx" SG_ 954 TlghtTestLght_D_Stat 1;
BA_ "U_T6_MCA_MY2020_Rx" SG_ 954 TlghtTestLght_D_Stat 1;
BA_ "U_T6_MCA_MY2020_Rx" SG_ 954 LghtAmbDrvMde_B_Stat 1;
BA_ "WakeupSignal" SG_ 954 LghtAmbDrvMde_B_Stat 1;
BA_ "U_CD542_MY2021_Rx" SG_ 954 KeylessIdl_B_Stat 1;
BA_ "U_T6_MCA_MY2020_Rx" SG_ 954 KeylessIdl_B_Stat 1;
BA_ "WakeupSignal" SG_ 954 PwRnngBoardPoll_D_Stat 1;
BA_ "U_CD542_MY2021_Rx" SG_ 954 PoliceDmngLvl_D_Stat 1;
BA_ "U_T6_MCA_MY2020_Rx" SG_ 954 PoliceDmngLvl_D_Stat 1;
BA_ "U_CD542_MY2021_Rx" SG_ 954 TrlrHitchLamp_D_Stat 1;
BA_ "U_T6_MCA_MY2020_Rx" SG_ 954 TrlrHitchLamp_D_Stat 1;
BA_ "WakeupSignal" SG_ 954 TrlrHitchLamp_D_Stat 1;
BA_ "U_CD542_MY2021_Rx" SG_ 954 LicPlateLght_B_Stat 1;
BA_ "U_T6_MCA_MY2020_Rx" SG_ 954 LicPlateLght_B_Stat 1;
BA_ "U_CD542_MY2021_Rx" SG_ 954 TrukBedLght_B_Stat 1;
BA_ "U_T6_MCA_MY2020_Rx" SG_ 954 TrukBedLght_B_Stat 1;
BA_ "WakeupSignal" SG_ 954 TrukBedLght_B_Stat 1;
BA_ "U_CD542_MY2021_Rx" SG_ 954 VehWlcmFrwlMde_D_Stat 1;
BA_ "U_T6_MCA_MY2020_Rx" SG_ 954 VehWlcmFrwlMde_D_Stat 1;
BA_ "WakeupSignal" SG_ 954 VehWlcmFrwlMde_D_Stat 1;
BA_ "ContentDependant" SG_ 954 GenericSwtch2_No_Actl 1;
BA_ "WakeupSignal" SG_ 954 PudSptLghtRight_D_Rq 1;
BA_ "WakeupSignal" SG_ 954 PudSptLghtLeft_D_Rq 1;
BA_ "U_CD542_MY2021_Rx" SG_ 954 ExtLghtRight_D_Stat 1;
BA_ "U_T6_MCA_MY2020_Rx" SG_ 954 ExtLghtRight_D_Stat 1;
BA_ "WakeupSignal" SG_ 954 ExtLghtRight_D_Stat 1;
BA_ "U_CD542_MY2021_Rx" SG_ 954 VehWlcmFrwl_D_Stat 1;
BA_ "U_T6_MCA_MY2020_Rx" SG_ 954 VehWlcmFrwl_D_Stat 1;
BA_ "WakeupSignal" SG_ 954 VehWlcmFrwl_D_Stat 1;
BA_ "U_CD542_MY2021_Rx" SG_ 954 ExtLghtRear_D_Stat 1;
BA_ "U_T6_MCA_MY2020_Rx" SG_ 954 ExtLghtRear_D_Stat 1;
BA_ "WakeupSignal" SG_ 954 ExtLghtRear_D_Stat 1;
BA_ "U_CD542_MY2021_Rx" SG_ 954 ExtLghtLeft_D_Stat 1;
BA_ "U_T6_MCA_MY2020_Rx" SG_ 954 ExtLghtLeft_D_Stat 1;
BA_ "WakeupSignal" SG_ 954 ExtLghtLeft_D_Stat 1;
BA_ "U_CD542_MY2021_Rx" SG_ 954 ExtLghtAlrt_B_Rq 1;
BA_ "U_T6_MCA_MY2020_Rx" SG_ 954 ExtLghtAlrt_B_Rq 1;
BA_ "WakeupSignal" SG_ 954 ExtLghtAlrt_B_Rq 1;
BA_ "U_CD542_MY2021_Rx" SG_ 954 ExtLght_D_Falt 1;
BA_ "U_T6_MCA_MY2020_Rx" SG_ 954 ExtLght_D_Falt 1;
BA_ "WakeupSignal" SG_ 954 ExtLght_D_Falt 1;
BA_ "U_CD542_MY2021_Rx" SG_ 954 ExtLghtFront_D_Stat 1;
BA_ "U_T6_MCA_MY2020_Rx" SG_ 954 ExtLghtFront_D_Stat 1;
BA_ "WakeupSignal" SG_ 954 ExtLghtFront_D_Stat 1;
BA_ "U_CD542_MY2021_Rx" SG_ 954 TlghtTestPrecnd_D_Stat 1;
BA_ "U_T6_MCA_MY2020_Rx" SG_ 954 TlghtTestPrecnd_D_Stat 1;
BA_ "U_CD542_MY2021_Rx" SG_ 954 TlghtTest_D_Stat 1;
BA_ "U_T6_MCA_MY2020_Rx" SG_ 954 TlghtTest_D_Stat 1;
BA_ "U_CD542_MY2021_Rx" SG_ 125 VehRolComp_W_Actl 1;
BA_ "U_T6_MCA_MY2020_Rx" SG_ 125 VehRolComp_W_Actl 1;
BA_ "U_P702_MY2021_Rx" SG_ 125 VehRolComp_W_Actl 1;
BA_ "GenSigStartValue" SG_ 125 VehRolComp_W_Actl 4094;
BA_ "GenSigStartValueInteger" SG_ 125 VehRolComp_W_Actl 4094;
BA_ "U_CD542_MY2021_Rx" SG_ 125 VehVertComp_A_Actl 1;
BA_ "U_T6_MCA_MY2020_Rx" SG_ 125 VehVertComp_A_Actl 1;
BA_ "U_P702_MY2021_Rx" SG_ 125 VehVertComp_A_Actl 1;
BA_ "GenSigStartValue" SG_ 125 VehVertComp_A_Actl 1022;
BA_ "GenSigStartValueInteger" SG_ 125 VehVertComp_A_Actl 1022;
BA_ "U_T6_MCA_MY2020_Rx" SG_ 125 BrkTotTqRqArb_No_Cs 1;
BA_ "U_P702_MY2021_Rx" SG_ 125 BrkTotTqRqArb_No_Cs 1;
BA_ "MetaData" SG_ 125 BrkTotTqRqArb_No_Cs 1;
BA_ "U_T6_MCA_MY2020_Rx" SG_ 125 BrkTotTqRqArb_No_Cnt 1;
BA_ "U_P702_MY2021_Rx" SG_ 125 BrkTotTqRqArb_No_Cnt 1;
BA_ "MetaData" SG_ 125 BrkTotTqRqArb_No_Cnt 1;
BA_ "U_T6_MCA_MY2020_Rx" SG_ 125 BrkTot_Tq_RqArb 1;
BA_ "U_P702_MY2021_Rx" SG_ 125 BrkTot_Tq_RqArb 1;
BA_ "U_P702_MY2021_Rx" SG_ 125 BrkTot_Tq_Actl 1;
BA_ "U_T6_MCA_MY2020_Rx" SG_ 125 BrkTot_Tq_Actl 1;
BA_ "U_T6_MCA_MY2020_Rx" SG_ 125 HsaStat_D_Actl 1;
BA_ "U_P702_MY2021_Rx" SG_ 125 HsaStat_D_Actl 1;
BA_ "U_T6_MCA_MY2020_Tx" SG_ 2612224096 PARSEDPushIPCtoGWM_ECG 1;
BA_ "U_P702_MY2021_Tx" SG_ 2612224096 PARSEDPushIPCtoGWM_ECG 1;
BA_ "U_U55X_MY2022_Rx" SG_ 2612224096 PARSEDPushIPCtoGWM_ECG 1;
BA_ "ECGUsedRxSignal" SG_ 2612224096 PARSEDPushIPCtoGWM_ECG 1;
BA_ "U_T6_MCA_MY2020_Rx" SG_ 2612224096 PARSEDPushIPCtoGWM_ECG 1;
BA_ "GenSigSendType" SG_ 2612224096 PARSEDPushIPCtoGWM_ECG 3;
BA_ "U_U55X_MY2022_Tx" SG_ 2611052760 PARSEDPhysGWM_ECGtoIPC 1;
BA_ "ECGUsedTxSignal" SG_ 2611052760 PARSEDPhysGWM_ECGtoIPC 1;
BA_ "U_T6_MCA_MY2020_Tx" SG_ 2611052760 PARSEDPhysGWM_ECGtoIPC 1;
BA_ "U_T6_MCA_MY2020_Rx" SG_ 2611052760 PARSEDPhysGWM_ECGtoIPC 1;
BA_ "U_P702_MY2021_Rx" SG_ 2611052760 PARSEDPhysGWM_ECGtoIPC 1;
BA_ "GenSigSendType" SG_ 2611052760 PARSEDPhysGWM_ECGtoIPC 3;
BA_ "U_T6_MCA_MY2020_Tx" SG_ 2611175520 PARSEDPhysIPCtoGWM_ECG 1;
BA_ "U_P702_MY2021_Tx" SG_ 2611175520 PARSEDPhysIPCtoGWM_ECG 1;
BA_ "U_U55X_MY2022_Rx" SG_ 2611175520 PARSEDPhysIPCtoGWM_ECG 1;
BA_ "ECGUsedRxSignal" SG_ 2611175520 PARSEDPhysIPCtoGWM_ECG 1;
BA_ "U_T6_MCA_MY2020_Rx" SG_ 2611175520 PARSEDPhysIPCtoGWM_ECG 1;
BA_ "GenSigSendType" SG_ 2611175520 PARSEDPhysIPCtoGWM_ECG 3;
BA_ "U_T6_MCA_MY2020_Tx" SG_ 2610126944 OTAPhysIPCtoGWM_ECG 1;
BA_ "U_P702_MY2021_Tx" SG_ 2610126944 OTAPhysIPCtoGWM_ECG 1;
BA_ "U_U55X_MY2022_Rx" SG_ 2610126944 OTAPhysIPCtoGWM_ECG 1;
BA_ "ECGUsedRxSignal" SG_ 2610126944 OTAPhysIPCtoGWM_ECG 1;
BA_ "U_T6_MCA_MY2020_Rx" SG_ 2610126944 OTAPhysIPCtoGWM_ECG 1;
BA_ "GenSigSendType" SG_ 2610126944 OTAPhysIPCtoGWM_ECG 3;
BA_ "U_U55X_MY2022_Tx" SG_ 2610004184 OTAPhysGWM_ECGtoIPC 1;
BA_ "ECGUsedTxSignal" SG_ 2610004184 OTAPhysGWM_ECGtoIPC 1;
BA_ "U_T6_MCA_MY2020_Tx" SG_ 2610004184 OTAPhysGWM_ECGtoIPC 1;
BA_ "U_T6_MCA_MY2020_Rx" SG_ 2610004184 OTAPhysGWM_ECGtoIPC 1;
BA_ "U_P702_MY2021_Rx" SG_ 2610004184 OTAPhysGWM_ECGtoIPC 1;
BA_ "GenSigSendType" SG_ 2610004184 OTAPhysGWM_ECGtoIPC 3;
BA_ "GenSigSendType" SG_ 2005 TesterPhysicalReqDACMC 3;
BA_ "GenSigSendType" SG_ 2013 TesterPhysicalResDACMC 3;
BA_ "GenSigStartValue" SG_ 1519 DACMC_GWOnBoardTester 255;
BA_ "ContentDependant" SG_ 1519 DACMC_GWOnBoardTester 1;
BA_ "GenSigStartValueInteger" SG_ 1519 DACMC_GWOnBoardTester 255;
BA_ "GenSigStartValue" SG_ 1519 DACMC_GWNMProxy 255;
BA_ "ContentDependant" SG_ 1519 DACMC_GWNMProxy 1;
BA_ "GenSigStartValueInteger" SG_ 1519 DACMC_GWNMProxy 255;
BA_ "GenSigStartValue" SG_ 1519 DACMC_AutoSarNMReserved4 255;
BA_ "ContentDependant" SG_ 1519 DACMC_AutoSarNMReserved4 1;
BA_ "GenSigStartValueInteger" SG_ 1519 DACMC_AutoSarNMReserved4 255;
BA_ "GenSigStartValue" SG_ 1519 DACMC_AutoSarNMReserved3 255;
BA_ "ContentDependant" SG_ 1519 DACMC_AutoSarNMReserved3 1;
BA_ "GenSigStartValueInteger" SG_ 1519 DACMC_AutoSarNMReserved3 255;
BA_ "GenSigStartValue" SG_ 1519 DACMC_AutoSarNMReserved2 255;
BA_ "ContentDependant" SG_ 1519 DACMC_AutoSarNMReserved2 1;
BA_ "GenSigStartValueInteger" SG_ 1519 DACMC_AutoSarNMReserved2 255;
BA_ "GenSigStartValue" SG_ 1519 DACMC_AutoSarNMReserved1 255;
BA_ "ContentDependant" SG_ 1519 DACMC_AutoSarNMReserved1 1;
BA_ "GenSigStartValueInteger" SG_ 1519 DACMC_AutoSarNMReserved1 255;
BA_ "GenSigStartValue" SG_ 1519 DACMC_AutoSarNMNodeId 239;
BA_ "ContentDependant" SG_ 1519 DACMC_AutoSarNMNodeId 1;
BA_ "GenSigStartValueInteger" SG_ 1519 DACMC_AutoSarNMNodeId 150;
BA_ "ContentDependant" SG_ 1519 DACMC_AutoSarNMControl 1;
BA_ "U_U55X_MY2022_Tx" SG_ 2612002008 PARSEDFuncGWM_ECG 1;
BA_ "ECGUsedTxSignal" SG_ 2612002008 PARSEDFuncGWM_ECG 1;
BA_ "U_T6_MCA_MY2020_Tx" SG_ 2612002008 PARSEDFuncGWM_ECG 1;
BA_ "U_T6_MCA_MY2020_Rx" SG_ 2612002008 PARSEDFuncGWM_ECG 1;
BA_ "U_P702_MY2021_Rx" SG_ 2612002008 PARSEDFuncGWM_ECG 1;
BA_ "GenSigSendType" SG_ 2612002008 PARSEDFuncGWM_ECG 3;
BA_ "U_U55X_MY2022_Tx" SG_ 2610953432 OTAFuncGWM_ECG 1;
BA_ "ECGUsedTxSignal" SG_ 2610953432 OTAFuncGWM_ECG 1;
BA_ "U_T6_MCA_MY2020_Tx" SG_ 2610953432 OTAFuncGWM_ECG 1;
BA_ "U_T6_MCA_MY2020_Rx" SG_ 2610953432 OTAFuncGWM_ECG 1;
BA_ "U_P702_MY2021_Rx" SG_ 2610953432 OTAFuncGWM_ECG 1;
BA_ "GenSigSendType" SG_ 2610953432 OTAFuncGWM_ECG 3;
BA_ "U_T6_MCA_MY2020_Rx" SG_ 1082 StabBarFaltMsgTxt_D_Rq_UB 1;
BA_ "U_T6_MCA_MY2020_Rx" SG_ 1082 StabBarCnnctLamp_D_Rq_UB 1;
BA_ "U_T6_MCA_MY2020_Rx" SG_ 1082 StabBarCnncMsgTxt_D_Rq_UB 1;
BA_ "U_T6_MCA_MY2020_Rx" SG_ 1082 StabBarFaltMsgTxt_D_Rq 1;
BA_ "GenSigSendType" SG_ 1082 StabBarFaltMsgTxt_D_Rq 3;
BA_ "U_T6_MCA_MY2020_Rx" SG_ 1082 StabBarCnnctLamp_D_Rq 1;
BA_ "GenSigSendType" SG_ 1082 StabBarCnnctLamp_D_Rq 3;
BA_ "U_T6_MCA_MY2020_Rx" SG_ 1082 StabBarCnncMsgTxt_D_Rq 1;
BA_ "GenSigSendType" SG_ 1082 StabBarCnncMsgTxt_D_Rq 3;
BA_ "U_T6_MCA_MY2020_Tx" SG_ 576 AUDIO_RDISP2_WORD_Tx 1;
BA_ "U_T6_MCA_MY2020_Rx" SG_ 576 AUDIO_RDISP2_WORD_Tx 1;
BA_ "U_T6_MCA_MY2020_Tx" SG_ 1115 HUD_TextMessage_Rq 1;
BA_ "U_CD542_MY2021_Rx" SG_ 1115 HUD_TextMessage_Rq 1;
BA_ "U_T6_MCA_MY2020_Rx" SG_ 1115 HUD_TextMessage_Rq 1;
BA_ "GenSigSendType" SG_ 1115 HUD_TextMessage_Rq 3;
BA_ "U_T6_MCA_MY2020_Tx" SG_ 1115 HUD_BTIncomingCall_Rq 1;
BA_ "U_CD542_MY2021_Rx" SG_ 1115 HUD_BTIncomingCall_Rq 1;
BA_ "U_T6_MCA_MY2020_Rx" SG_ 1115 HUD_BTIncomingCall_Rq 1;
BA_ "GenSigSendType" SG_ 1115 HUD_BTIncomingCall_Rq 3;
BA_ "U_T6_MCA_MY2020_Tx" SG_ 1115 HUD_BTInCallOptions_Rq 1;
BA_ "U_CD542_MY2021_Rx" SG_ 1115 HUD_BTInCallOptions_Rq 1;
BA_ "U_T6_MCA_MY2020_Rx" SG_ 1115 HUD_BTInCallOptions_Rq 1;
BA_ "GenSigSendType" SG_ 1115 HUD_BTInCallOptions_Rq 3;
BA_ "U_T6_MCA_MY2020_Tx" SG_ 1115 HUD_BTEndTelService_Rq 1;
BA_ "U_CD542_MY2021_Rx" SG_ 1115 HUD_BTEndTelService_Rq 1;
BA_ "U_T6_MCA_MY2020_Rx" SG_ 1115 HUD_BTEndTelService_Rq 1;
BA_ "GenSigSendType" SG_ 1115 HUD_BTEndTelService_Rq 3;
BA_ "U_T6_MCA_MY2020_Tx" SG_ 996 PersIndexHud_D_Actl 1;
BA_ "U_CD542_MY2021_Rx" SG_ 996 PersIndexHud_D_Actl 1;
BA_ "U_T6_MCA_MY2020_Rx" SG_ 996 PersIndexHud_D_Actl 1;
BA_ "GenSigSendType" SG_ 996 PersIndexHud_D_Actl 3;
BA_ "U_T6_MCA_MY2020_Tx" SG_ 996 FeatNoHudActl 1;
BA_ "U_CD542_MY2021_Rx" SG_ 996 FeatNoHudActl 1;
BA_ "U_T6_MCA_MY2020_Rx" SG_ 996 FeatNoHudActl 1;
BA_ "GenSigSendType" SG_ 996 FeatNoHudActl 3;
BA_ "U_T6_MCA_MY2020_Tx" SG_ 996 FeatConfigHudActl 1;
BA_ "U_CD542_MY2021_Rx" SG_ 996 FeatConfigHudActl 1;
BA_ "U_T6_MCA_MY2020_Rx" SG_ 996 FeatConfigHudActl 1;
BA_ "GenSigSendType" SG_ 996 FeatConfigHudActl 3;
BA_ "U_T6_MCA_MY2020_Tx" SG_ 588 RDRV_RDISP2_WORD_Rx 1;
BA_ "U_CD542_MY2021_Tx" SG_ 811 ExtLghtDsply_D_Stat 1;
BA_ "U_T6_MCA_MY2020_Tx" SG_ 811 ExtLghtDsply_D_Stat 1;
BA_ "U_U55X_MY2022_Rx" SG_ 811 ExtLghtDsply_D_Stat 1;
BA_ "ECGUsedRxSignal" SG_ 811 ExtLghtDsply_D_Stat 1;
BA_ "U_T6_MCA_MY2020_Rx" SG_ 811 ExtLghtDsply_D_Stat 1;
BA_ "GenSigSendType" SG_ 811 ExtLghtDsply_D_Stat 3;
BA_ "U_CD542_MY2021_Tx" SG_ 811 SpeedoMajorUnit_D_Confg 1;
BA_ "U_T6_MCA_MY2020_Tx" SG_ 811 SpeedoMajorUnit_D_Confg 1;
BA_ "GenSigSendType" SG_ 811 SpeedoMajorUnit_D_Confg 3;
BA_ "U_CD542_MY2021_Tx" SG_ 811 ScMnSoc_Pc_RqMnu 1;
BA_ "U_T6_MCA_MY2020_Tx" SG_ 811 ScMnSoc_Pc_RqMnu 1;
BA_ "GenSigStartValue" SG_ 811 ScMnSoc_Pc_RqMnu 126;
BA_ "U_CD542_MY2021_Tx" SG_ 811 ScEnbl_D_RqMnu 1;
BA_ "U_T6_MCA_MY2020_Tx" SG_ 811 ScEnbl_D_RqMnu 1;
BA_ "GenSigSendType" SG_ 811 ScEnbl_D_RqMnu 3;
BA_ "U_CD542_MY2021_Tx" SG_ 811 OnePdlDrvButtn_B_Falt 1;
BA_ "U_T6_MCA_MY2020_Tx" SG_ 811 OnePdlDrvButtn_B_Falt 1;
BA_ "GenSigSendType" SG_ 811 OnePdlDrvButtn_B_Falt 3;
BA_ "U_CD542_MY2021_Tx" SG_ 811 OnePdlDrvButtn_B_Stat 1;
BA_ "U_T6_MCA_MY2020_Tx" SG_ 811 OnePdlDrvButtn_B_Stat 1;
BA_ "GenSigSendType" SG_ 811 OnePdlDrvButtn_B_Stat 3;
BA_ "U_CD542_MY2021_Tx" SG_ 811 LongTermReset_B_RqMnu 1;
BA_ "U_T6_MCA_MY2020_Tx" SG_ 811 LongTermReset_B_RqMnu 1;
BA_ "GenSigSendType" SG_ 811 LongTermReset_B_RqMnu 3;
BA_ "U_CD542_MY2021_Tx" SG_ 811 DistToStopover_L_Actl 1;
BA_ "U_T6_MCA_MY2020_Tx" SG_ 811 DistToStopover_L_Actl 1;
BA_ "U_U55X_MY2022_Rx" SG_ 811 DistToStopover_L_Actl 1;
BA_ "ECGUsedRxSignal" SG_ 811 DistToStopover_L_Actl 1;
BA_ "U_T6_MCA_MY2020_Rx" SG_ 811 DistToStopover_L_Actl 1;
BA_ "GenSigStartValue" SG_ 811 DistToStopover_L_Actl 65535;
BA_ "U_CD542_MY2021_Tx" SG_ 811 StopoverType_D_Stat 1;
BA_ "U_T6_MCA_MY2020_Tx" SG_ 811 StopoverType_D_Stat 1;
BA_ "U_U55X_MY2022_Rx" SG_ 811 StopoverType_D_Stat 1;
BA_ "ECGUsedRxSignal" SG_ 811 StopoverType_D_Stat 1;
BA_ "U_T6_MCA_MY2020_Rx" SG_ 811 StopoverType_D_Stat 1;
BA_ "GenSigSendType" SG_ 811 StopoverType_D_Stat 3;
BA_ "U_CD542_MY2021_Tx" SG_ 811 ExtLghtRight_D_RqMnu 1;
BA_ "U_T6_MCA_MY2020_Tx" SG_ 811 ExtLghtRight_D_RqMnu 1;
BA_ "GenSigSendType" SG_ 811 ExtLghtRight_D_RqMnu 3;
BA_ "WakeupSignal" SG_ 811 ExtLghtRight_D_RqMnu 1;
BA_ "U_CD542_MY2021_Tx" SG_ 811 AutoLghtOvrrd_B_RqDrv 1;
BA_ "U_T6_MCA_MY2020_Tx" SG_ 811 AutoLghtOvrrd_B_RqDrv 1;
BA_ "GenSigSendType" SG_ 811 AutoLghtOvrrd_B_RqDrv 3;
BA_ "WakeupSignal" SG_ 811 AutoLghtOvrrd_B_RqDrv 1;
BA_ "U_CD542_MY2021_Tx" SG_ 811 ExtLghtRear_D_RqMnu 1;
BA_ "U_T6_MCA_MY2020_Tx" SG_ 811 ExtLghtRear_D_RqMnu 1;
BA_ "GenSigSendType" SG_ 811 ExtLghtRear_D_RqMnu 3;
BA_ "WakeupSignal" SG_ 811 ExtLghtRear_D_RqMnu 1;
BA_ "U_CD542_MY2021_Tx" SG_ 811 ExtLghtLeft_D_RqMnu 1;
BA_ "U_T6_MCA_MY2020_Tx" SG_ 811 ExtLghtLeft_D_RqMnu 1;
BA_ "GenSigSendType" SG_ 811 ExtLghtLeft_D_RqMnu 3;
BA_ "WakeupSignal" SG_ 811 ExtLghtLeft_D_RqMnu 1;
BA_ "U_CD542_MY2021_Tx" SG_ 811 ExtLghtFront_D_RqMnu 1;
BA_ "U_T6_MCA_MY2020_Tx" SG_ 811 ExtLghtFront_D_RqMnu 1;
BA_ "GenSigSendType" SG_ 811 ExtLghtFront_D_RqMnu 3;
BA_ "WakeupSignal" SG_ 811 ExtLghtFront_D_RqMnu 1;
BA_ "U_CD542_MY2021_Tx" SG_ 811 BecRleas_No_RqMnu 1;
BA_ "U_T6_MCA_MY2020_Tx" SG_ 811 BecRleas_No_RqMnu 1;
BA_ "GenSigSendType" SG_ 811 BecRleas_No_RqMnu 3;
BA_ "WakeupSignal" SG_ 811 BecRleas_No_RqMnu 1;
BA_ "U_CD542_MY2021_Tx" SG_ 811 TrnkFrontRleas_No_RqMnu 1;
BA_ "U_T6_MCA_MY2020_Tx" SG_ 811 TrnkFrontRleas_No_RqMnu 1;
BA_ "GenSigSendType" SG_ 811 TrnkFrontRleas_No_RqMnu 3;
BA_ "WakeupSignal" SG_ 811 TrnkFrontRleas_No_RqMnu 1;
BA_ "U_CD542_MY2021_Tx" SG_ 811 GoTEditMnte_T_RqMnu 1;
BA_ "U_T6_MCA_MY2020_Tx" SG_ 811 GoTEditMnte_T_RqMnu 1;
BA_ "U_U55X_MY2022_Rx" SG_ 811 GoTEditMnte_T_RqMnu 1;
BA_ "ECGUsedRxSignal" SG_ 811 GoTEditMnte_T_RqMnu 1;
BA_ "U_T6_MCA_MY2020_Rx" SG_ 811 GoTEditMnte_T_RqMnu 1;
BA_ "GenSigSendType" SG_ 811 GoTEditMnte_T_RqMnu 3;
BA_ "GenSigStartValue" SG_ 811 GoTEditMnte_T_RqMnu 14;
BA_ "U_CD542_MY2021_Tx" SG_ 811 GoTEditHr_T_RqMnu 1;
BA_ "U_T6_MCA_MY2020_Tx" SG_ 811 GoTEditHr_T_RqMnu 1;
BA_ "U_U55X_MY2022_Rx" SG_ 811 GoTEditHr_T_RqMnu 1;
BA_ "ECGUsedRxSignal" SG_ 811 GoTEditHr_T_RqMnu 1;
BA_ "U_T6_MCA_MY2020_Rx" SG_ 811 GoTEditHr_T_RqMnu 1;
BA_ "GenSigSendType" SG_ 811 GoTEditHr_T_RqMnu 3;
BA_ "GenSigStartValue" SG_ 811 GoTEditHr_T_RqMnu 30;
BA_ "U_T6_MCA_MY2020_Tx" SG_ 543 TeltalWarnData_No_Actl 1;
BA_ "U_CD542_MY2021_Rx" SG_ 543 TeltalWarnData_No_Actl 1;
BA_ "U_U55X_MY2022_Rx" SG_ 543 TeltalWarnData_No_Actl 1;
BA_ "ECGUsedRxSignal" SG_ 543 TeltalWarnData_No_Actl 1;
BA_ "U_T6_MCA_MY2020_Rx" SG_ 543 TeltalWarnData_No_Actl 1;
BA_ "U_U55X_MY2022_Tx" SG_ 563 BattChrgStrtStop_D_Rq 1;
BA_ "ECGUsedTxSignal" SG_ 563 BattChrgStrtStop_D_Rq 1;
BA_ "GenSigSendType" SG_ 563 BattChrgStrtStop_D_Rq 3;
BA_ "U_U55X_MY2022_Tx" SG_ 563 DrvBhavWarn_B_Rq 1;
BA_ "ECGUsedTxSignal" SG_ 563 DrvBhavWarn_B_Rq 1;
BA_ "U_T6_MCA_MY2020_Tx" SG_ 563 DrvBhavWarn_B_Rq 1;
BA_ "U_T6_MCA_MY2020_Rx" SG_ 563 DrvBhavWarn_B_Rq 1;
BA_ "GenSigSendType" SG_ 563 DrvBhavWarn_B_Rq 3;
BA_ "U_U55X_MY2022_Tx" SG_ 563 OfbChrgSetSync_D_Rq 1;
BA_ "ECGUsedTxSignal" SG_ 563 OfbChrgSetSync_D_Rq 1;
BA_ "U_T6_MCA_MY2020_Tx" SG_ 563 OfbChrgSetSync_D_Rq 1;
BA_ "U_T6_MCA_MY2020_Rx" SG_ 563 OfbChrgSetSync_D_Rq 1;
BA_ "GenSigSendType" SG_ 563 OfbChrgSetSync_D_Rq 3;
BA_ "U_U55X_MY2022_Tx" SG_ 563 KeyOffPwMde_D_Stat 1;
BA_ "ECGUsedTxSignal" SG_ 563 KeyOffPwMde_D_Stat 1;
BA_ "U_T6_MCA_MY2020_Tx" SG_ 563 KeyOffPwMde_D_Stat 1;
BA_ "U_T6_MCA_MY2020_Rx" SG_ 563 KeyOffPwMde_D_Stat 1;
BA_ "GenSigSendType" SG_ 563 KeyOffPwMde_D_Stat 3;
BA_ "U_U55X_MY2022_Tx" SG_ 563 ModemReset_D_Stat 1;
BA_ "ECGUsedTxSignal" SG_ 563 ModemReset_D_Stat 1;
BA_ "U_T6_MCA_MY2020_Tx" SG_ 563 ModemReset_D_Stat 1;
BA_ "U_T6_MCA_MY2020_Rx" SG_ 563 ModemReset_D_Stat 1;
BA_ "GenSigSendType" SG_ 563 ModemReset_D_Stat 3;
BA_ "U_U55X_MY2022_Tx" SG_ 563 FactoryReset_St 1;
BA_ "ECGUsedTxSignal" SG_ 563 FactoryReset_St 1;
BA_ "U_T6_MCA_MY2020_Tx" SG_ 563 FactoryReset_St 1;
BA_ "U_T6_MCA_MY2020_Rx" SG_ 563 FactoryReset_St 1;
BA_ "GenSigSendType" SG_ 563 FactoryReset_St 3;
BA_ "U_T6_MCA_MY2020_Rx" SG_ 794 HvacBlwrRear_D_Stat_UB 1;
BA_ "U_T6_MCA_MY2020_Rx" SG_ 794 HvacBlwrFront_D_Stat_UB 1;
BA_ "U_T6_MCA_MY2020_Rx" SG_ 794 HvacBlwrRear_D_Stat 1;
BA_ "GenSigSendType" SG_ 794 HvacBlwrRear_D_Stat 3;
BA_ "U_T6_MCA_MY2020_Rx" SG_ 794 HvacBlwrFront_D_Stat 1;
BA_ "GenSigSendType" SG_ 794 HvacBlwrFront_D_Stat 3;
BA_ "U_CD542_MY2021_Rx" SG_ 794 SpotLghtLeft_D_Stat_UB 1;
BA_ "U_T6_MCA_MY2020_Rx" SG_ 794 SpotLghtLeft_D_Stat_UB 1;
BA_ "U_CD542_MY2021_Rx" SG_ 794 SpotLghtRight_D_Stat_UB 1;
BA_ "U_T6_MCA_MY2020_Rx" SG_ 794 SpotLghtRight_D_Stat_UB 1;
BA_ "U_CD542_MY2021_Rx" SG_ 794 SpotLghtRight_D_Stat 1;
BA_ "U_T6_MCA_MY2020_Rx" SG_ 794 SpotLghtRight_D_Stat 1;
BA_ "GenSigSendType" SG_ 794 SpotLghtRight_D_Stat 3;
BA_ "U_CD542_MY2021_Rx" SG_ 794 SpotLghtLeft_D_Stat 1;
BA_ "U_T6_MCA_MY2020_Rx" SG_ 794 SpotLghtLeft_D_Stat 1;
BA_ "GenSigSendType" SG_ 794 SpotLghtLeft_D_Stat 3;
BA_ "U_T6_MCA_MY2020_Tx" SG_ 587 PHONE_RDISP2_WORD_Rx 1;
BA_ "U_CD542_MY2021_Rx" SG_ 587 PHONE_RDISP2_WORD_Rx 1;
BA_ "U_T6_MCA_MY2020_Rx" SG_ 587 PHONE_RDISP2_WORD_Rx 1;
BA_ "U_CD542_MY2021_Tx" SG_ 579 PHONE_RDISP2_WORD_Tx 1;
BA_ "U_T6_MCA_MY2020_Tx" SG_ 579 PHONE_RDISP2_WORD_Tx 1;
BA_ "U_T6_MCA_MY2020_Rx" SG_ 579 PHONE_RDISP2_WORD_Tx 1;
BA_ "U_T6_MCA_MY2020_Tx" SG_ 585 NAV_RDISP2_WORD_Rx 1;
BA_ "U_CD542_MY2021_Rx" SG_ 585 NAV_RDISP2_WORD_Rx 1;
BA_ "U_T6_MCA_MY2020_Rx" SG_ 585 NAV_RDISP2_WORD_Rx 1;
BA_ "U_T6_MCA_MY2020_Tx" SG_ 586 CONMP_RDISP2_WORD_Rx 1;
BA_ "U_CD542_MY2021_Rx" SG_ 586 CONMP_RDISP2_WORD_Rx 1;
BA_ "U_T6_MCA_MY2020_Rx" SG_ 586 CONMP_RDISP2_WORD_Rx 1;
BA_ "U_CD542_MY2021_Tx" SG_ 578 CONMP_RDISP2_WORD_Tx 1;
BA_ "U_T6_MCA_MY2020_Tx" SG_ 578 CONMP_RDISP2_WORD_Tx 1;
BA_ "U_T6_MCA_MY2020_Rx" SG_ 578 CONMP_RDISP2_WORD_Tx 1;
BA_ "U_CD542_MY2021_Tx" SG_ 577 NAV_RDISP2_WORD_Tx 1;
BA_ "U_T6_MCA_MY2020_Tx" SG_ 577 NAV_RDISP2_WORD_Tx 1;
BA_ "U_T6_MCA_MY2020_Rx" SG_ 577 NAV_RDISP2_WORD_Tx 1;
BA_ "U_CD542_MY2021_Rx" SG_ 712 NAV_MC_WORD_Rx 1;
BA_ "U_T6_MCA_MY2020_Rx" SG_ 712 NAV_MC_WORD_Rx 1;
BA_ "U_CD542_MY2021_Tx" SG_ 717 DSPAMP_RDISP_WORD_Rx 1;
BA_ "U_T6_MCA_MY2020_Tx" SG_ 717 DSPAMP_RDISP_WORD_Rx 1;
BA_ "U_T6_MCA_MY2020_Rx" SG_ 717 DSPAMP_RDISP_WORD_Rx 1;
BA_ "U_CD542_MY2021_Tx" SG_ 719 MyKeySrvr_Clnt_Word_Rx 1;
BA_ "U_T6_MCA_MY2020_Tx" SG_ 719 MyKeySrvr_Clnt_Word_Rx 1;
BA_ "U_T6_MCA_MY2020_Rx" SG_ 719 MyKeySrvr_Clnt_Word_Rx 1;
BA_ "U_CD542_MY2021_Tx" SG_ 589 TRAFFIC_RDISP_WORD_Rx 1;
BA_ "U_T6_MCA_MY2020_Tx" SG_ 589 TRAFFIC_RDISP_WORD_Rx 1;
BA_ "GenSigSendType" SG_ 1879 TesterPhysicalReqTBM_HS3 3;
BA_ "GenSigSendType" SG_ 1887 TesterPhysicalResTBM_HS3 3;
BA_ "U_T6_MCA_MY2020_Tx" SG_ 1146 TrlrAidSwtch_D_RqDrv 1;
BA_ "U_P702_MY2021_Tx" SG_ 1146 TrlrAidSwtch_D_RqDrv 1;
BA_ "U_T6_MCA_MY2020_Tx" SG_ 1146 TrlrAidCtl_U_RqDrv 1;
BA_ "U_P702_MY2021_Tx" SG_ 1146 TrlrAidCtl_U_RqDrv 1;
BA_ "GenSigStartValue" SG_ 1146 TrlrAidCtl_U_RqDrv 4093;
BA_ "GenSigStartValueInteger" SG_ 1146 TrlrAidCtl_U_RqDrv 4094;
BA_ "U_P702_MY2021_Tx" SG_ 1146 TrlrAidAn_URate_Actl 1;
BA_ "GenSigStartValue" SG_ 1146 TrlrAidAn_URate_Actl 4094;
BA_ "GenSigStartValueInteger" SG_ 1146 TrlrAidAn_URate_Actl 4094;
BA_ "U_P702_MY2021_Tx" SG_ 1146 TrlrAidAn_U_Actl 1;
BA_ "GenSigStartValue" SG_ 1146 TrlrAidAn_U_Actl 4093;
BA_ "GenSigStartValueInteger" SG_ 1146 TrlrAidAn_U_Actl 4094;
BA_ "U_CD542_MY2021_Tx" SG_ 737 APIM_ECG_Word_Tx 1;
BA_ "U_T6_MCA_MY2020_Tx" SG_ 737 APIM_ECG_Word_Tx 1;
BA_ "U_U55X_MY2022_Rx" SG_ 737 APIM_ECG_Word_Tx 1;
BA_ "ECGUsedRxSignal" SG_ 737 APIM_ECG_Word_Tx 1;
BA_ "U_T6_MCA_MY2020_Rx" SG_ 737 APIM_ECG_Word_Tx 1;
BA_ "U_U55X_MY2022_Tx" SG_ 745 ECG_APIM_Word_Tx 1;
BA_ "ECGUsedTxSignal" SG_ 745 ECG_APIM_Word_Tx 1;
BA_ "U_T6_MCA_MY2020_Tx" SG_ 745 ECG_APIM_Word_Tx 1;
BA_ "U_CD542_MY2021_Rx" SG_ 745 ECG_APIM_Word_Tx 1;
BA_ "U_T6_MCA_MY2020_Rx" SG_ 745 ECG_APIM_Word_Tx 1;
BA_ "U_T6_MCA_MY2020_Tx" SG_ 1195 TCU_RDISP2_WORD_Rx 1;
BA_ "U_T6_MCA_MY2020_Tx" SG_ 1435 HUD_GWOnBoardTester 1;
BA_ "GenSigStartValue" SG_ 1435 HUD_GWOnBoardTester 255;
BA_ "ContentDependant" SG_ 1435 HUD_GWOnBoardTester 1;
BA_ "GenSigStartValueInteger" SG_ 1435 HUD_GWOnBoardTester 255;
BA_ "U_T6_MCA_MY2020_Tx" SG_ 1435 HUD_GWNMProxy 1;
BA_ "GenSigStartValue" SG_ 1435 HUD_GWNMProxy 255;
BA_ "ContentDependant" SG_ 1435 HUD_GWNMProxy 1;
BA_ "GenSigStartValueInteger" SG_ 1435 HUD_GWNMProxy 255;
BA_ "U_T6_MCA_MY2020_Tx" SG_ 1435 HUD_AutoSarNMReserved4 1;
BA_ "GenSigStartValue" SG_ 1435 HUD_AutoSarNMReserved4 255;
BA_ "ContentDependant" SG_ 1435 HUD_AutoSarNMReserved4 1;
BA_ "GenSigStartValueInteger" SG_ 1435 HUD_AutoSarNMReserved4 255;
BA_ "U_T6_MCA_MY2020_Tx" SG_ 1435 HUD_AutoSarNMReserved3 1;
BA_ "GenSigStartValue" SG_ 1435 HUD_AutoSarNMReserved3 255;
BA_ "ContentDependant" SG_ 1435 HUD_AutoSarNMReserved3 1;
BA_ "GenSigStartValueInteger" SG_ 1435 HUD_AutoSarNMReserved3 255;
BA_ "U_T6_MCA_MY2020_Tx" SG_ 1435 HUD_AutoSarNMReserved2 1;
BA_ "GenSigStartValue" SG_ 1435 HUD_AutoSarNMReserved2 255;
BA_ "ContentDependant" SG_ 1435 HUD_AutoSarNMReserved2 1;
BA_ "GenSigStartValueInteger" SG_ 1435 HUD_AutoSarNMReserved2 255;
BA_ "U_T6_MCA_MY2020_Tx" SG_ 1435 HUD_AutoSarNMReserved 1;
BA_ "GenSigStartValue" SG_ 1435 HUD_AutoSarNMReserved 255;
BA_ "ContentDependant" SG_ 1435 HUD_AutoSarNMReserved 1;
BA_ "GenSigStartValueInteger" SG_ 1435 HUD_AutoSarNMReserved 255;
BA_ "U_T6_MCA_MY2020_Tx" SG_ 1435 HUD_AutoSarNMNodeId 1;
BA_ "GenSigStartValue" SG_ 1435 HUD_AutoSarNMNodeId 155;
BA_ "ContentDependant" SG_ 1435 HUD_AutoSarNMNodeId 1;
BA_ "GenSigStartValueInteger" SG_ 1435 HUD_AutoSarNMNodeId 83;
BA_ "U_T6_MCA_MY2020_Tx" SG_ 1435 HUD_AutoSarNMControl 1;
BA_ "ContentDependant" SG_ 1435 HUD_AutoSarNMControl 1;
BA_ "U_CD542_MY2021_Tx" SG_ 1109 eCallConfirmation 1;
BA_ "U_T6_MCA_MY2020_Tx" SG_ 1109 eCallConfirmation 1;
BA_ "U_P702_MY2021_Tx" SG_ 1109 eCallConfirmation 1;
BA_ "GenSigSendType" SG_ 1109 eCallConfirmation 3;
BA_ "U_T6_MCA_MY2020_Tx" SG_ 1492 TRM_GWOnBoardTester 1;
BA_ "U_P702_MY2021_Tx" SG_ 1492 TRM_GWOnBoardTester 1;
BA_ "GenSigStartValue" SG_ 1492 TRM_GWOnBoardTester 255;
BA_ "ContentDependant" SG_ 1492 TRM_GWOnBoardTester 1;
BA_ "GenSigStartValueInteger" SG_ 1492 TRM_GWOnBoardTester 255;
BA_ "U_T6_MCA_MY2020_Tx" SG_ 1492 TRM_GWNMProxy 1;
BA_ "U_P702_MY2021_Tx" SG_ 1492 TRM_GWNMProxy 1;
BA_ "GenSigStartValue" SG_ 1492 TRM_GWNMProxy 255;
BA_ "ContentDependant" SG_ 1492 TRM_GWNMProxy 1;
BA_ "GenSigStartValueInteger" SG_ 1492 TRM_GWNMProxy 255;
BA_ "U_T6_MCA_MY2020_Tx" SG_ 1492 TRM_AutoSarNMReserved4 1;
BA_ "U_P702_MY2021_Tx" SG_ 1492 TRM_AutoSarNMReserved4 1;
BA_ "GenSigStartValue" SG_ 1492 TRM_AutoSarNMReserved4 255;
BA_ "ContentDependant" SG_ 1492 TRM_AutoSarNMReserved4 1;
BA_ "GenSigStartValueInteger" SG_ 1492 TRM_AutoSarNMReserved4 255;
BA_ "U_T6_MCA_MY2020_Tx" SG_ 1492 TRM_AutoSarNMReserved3 1;
BA_ "U_P702_MY2021_Tx" SG_ 1492 TRM_AutoSarNMReserved3 1;
BA_ "GenSigStartValue" SG_ 1492 TRM_AutoSarNMReserved3 255;
BA_ "ContentDependant" SG_ 1492 TRM_AutoSarNMReserved3 1;
BA_ "GenSigStartValueInteger" SG_ 1492 TRM_AutoSarNMReserved3 255;
BA_ "U_T6_MCA_MY2020_Tx" SG_ 1492 TRM_AutoSarNMReserved2 1;
BA_ "U_P702_MY2021_Tx" SG_ 1492 TRM_AutoSarNMReserved2 1;
BA_ "GenSigStartValue" SG_ 1492 TRM_AutoSarNMReserved2 255;
BA_ "ContentDependant" SG_ 1492 TRM_AutoSarNMReserved2 1;
BA_ "GenSigStartValueInteger" SG_ 1492 TRM_AutoSarNMReserved2 255;
BA_ "U_T6_MCA_MY2020_Tx" SG_ 1492 TRM_AutoSarNMReserved1 1;
BA_ "U_P702_MY2021_Tx" SG_ 1492 TRM_AutoSarNMReserved1 1;
BA_ "GenSigStartValue" SG_ 1492 TRM_AutoSarNMReserved1 255;
BA_ "ContentDependant" SG_ 1492 TRM_AutoSarNMReserved1 1;
BA_ "GenSigStartValueInteger" SG_ 1492 TRM_AutoSarNMReserved1 255;
BA_ "U_T6_MCA_MY2020_Tx" SG_ 1492 TRM_AutoSarNMNodeId 1;
BA_ "U_P702_MY2021_Tx" SG_ 1492 TRM_AutoSarNMNodeId 1;
BA_ "GenSigStartValue" SG_ 1492 TRM_AutoSarNMNodeId 212;
BA_ "ContentDependant" SG_ 1492 TRM_AutoSarNMNodeId 1;
BA_ "GenSigStartValueInteger" SG_ 1492 TRM_AutoSarNMNodeId 150;
BA_ "U_T6_MCA_MY2020_Tx" SG_ 1492 TRM_AutoSarNMControl 1;
BA_ "U_P702_MY2021_Tx" SG_ 1492 TRM_AutoSarNMControl 1;
BA_ "ContentDependant" SG_ 1492 TRM_AutoSarNMControl 1;
BA_ "U_T6_MCA_MY2020_Tx" SG_ 1945 TesterPhysicalResTRM_ITRM 1;
BA_ "U_P702_MY2021_Tx" SG_ 1945 TesterPhysicalResTRM_ITRM 1;
BA_ "GenSigSendType" SG_ 1945 TesterPhysicalResTRM_ITRM 3;
BA_ "U_T6_MCA_MY2020_Rx" SG_ 1937 TesterPhysicalReqTRM_ITRM 1;
BA_ "U_P702_MY2021_Rx" SG_ 1937 TesterPhysicalReqTRM_ITRM 1;
BA_ "GenSigSendType" SG_ 1937 TesterPhysicalReqTRM_ITRM 3;
BA_ "U_T6_MCA_MY2020_Tx" SG_ 140 CcAslButtnIndxIncPress2 1;
BA_ "GenSigSendType" SG_ 140 CcAslButtnIndxIncPress2 3;
BA_ "U_CD542_MY2021_Tx" SG_ 140 SteWhlSwtchMde_D_Stat 1;
BA_ "U_T6_MCA_MY2020_Tx" SG_ 140 SteWhlSwtchMde_D_Stat 1;
BA_ "GenSigSendType" SG_ 140 SteWhlSwtchMde_D_Stat 3;
BA_ "U_T6_MCA_MY2020_Tx" SG_ 140 CcAslButtnOffCnclPress2 1;
BA_ "GenSigSendType" SG_ 140 CcAslButtnOffCnclPress2 3;
BA_ "U_T6_MCA_MY2020_Tx" SG_ 140 CcAslButtnIndxDecPress2 1;
BA_ "GenSigSendType" SG_ 140 CcAslButtnIndxDecPress2 3;
BA_ "U_T6_MCA_MY2020_Tx" SG_ 140 CcAslButtnCnclResPress2 1;
BA_ "GenSigSendType" SG_ 140 CcAslButtnCnclResPress2 3;
BA_ "U_T6_MCA_MY2020_Tx" SG_ 140 CcAslButtnResIncPress3 1;
BA_ "GenSigSendType" SG_ 140 CcAslButtnResIncPress3 3;
BA_ "U_T6_MCA_MY2020_Tx" SG_ 140 CcButtnOnPress3 1;
BA_ "GenSigSendType" SG_ 140 CcButtnOnPress3 3;
BA_ "U_T6_MCA_MY2020_Tx" SG_ 140 CcButtnOnOffPress3 1;
BA_ "GenSigSendType" SG_ 140 CcButtnOnOffPress3 3;
BA_ "U_T6_MCA_MY2020_Tx" SG_ 140 CcButtnOnOffCnclPress3 1;
BA_ "GenSigSendType" SG_ 140 CcButtnOnOffCnclPress3 3;
BA_ "U_T6_MCA_MY2020_Tx" SG_ 140 CcButtnOffPress3 1;
BA_ "GenSigSendType" SG_ 140 CcButtnOffPress3 3;
BA_ "U_T6_MCA_MY2020_Tx" SG_ 140 CcAsllButtnResPress3 1;
BA_ "GenSigSendType" SG_ 140 CcAsllButtnResPress3 3;
BA_ "U_T6_MCA_MY2020_Tx" SG_ 140 CcAslButtnSetPress3 1;
BA_ "GenSigSendType" SG_ 140 CcAslButtnSetPress3 3;
BA_ "U_T6_MCA_MY2020_Tx" SG_ 140 CcAslButtnSetIncPress3 1;
BA_ "GenSigSendType" SG_ 140 CcAslButtnSetIncPress3 3;
BA_ "U_T6_MCA_MY2020_Tx" SG_ 140 CcAslButtnSetDecPress3 1;
BA_ "GenSigSendType" SG_ 140 CcAslButtnSetDecPress3 3;
BA_ "U_T6_MCA_MY2020_Tx" SG_ 140 CcAslButtnResDecPress3 1;
BA_ "GenSigSendType" SG_ 140 CcAslButtnResDecPress3 3;
BA_ "U_T6_MCA_MY2020_Tx" SG_ 140 CcAslButtnOnPress3 1;
BA_ "GenSigSendType" SG_ 140 CcAslButtnOnPress3 3;
BA_ "U_T6_MCA_MY2020_Tx" SG_ 140 CcAslButtnOnOffCncl3 1;
BA_ "GenSigSendType" SG_ 140 CcAslButtnOnOffCncl3 3;
BA_ "U_T6_MCA_MY2020_Tx" SG_ 140 CcAslButtnDeny_B_Actl3 1;
BA_ "GenSigSendType" SG_ 140 CcAslButtnDeny_B_Actl3 3;
BA_ "U_T6_MCA_MY2020_Tx" SG_ 140 CcAslButtnCnclPress3 1;
BA_ "GenSigSendType" SG_ 140 CcAslButtnCnclPress3 3;
BA_ "U_T6_MCA_MY2020_Tx" SG_ 140 AslButtnOnOffPress3 1;
BA_ "GenSigSendType" SG_ 140 AslButtnOnOffPress3 3;
BA_ "U_T6_MCA_MY2020_Tx" SG_ 140 AslButtnOnOffCnclPress2 1;
BA_ "GenSigSendType" SG_ 140 AslButtnOnOffCnclPress2 3;
BA_ "U_CD542_MY2021_Tx" SG_ 546 PrplSnd_D_Rq 1;
BA_ "U_T6_MCA_MY2020_Tx" SG_ 546 PrplSnd_D_Rq 1;
BA_ "U_T6_MCA_MY2020_Rx" SG_ 546 PrplSnd_D_Rq 1;
BA_ "GenSigSendType" SG_ 546 PrplSnd_D_Rq 3;
BA_ "U_CD542_MY2021_Tx" SG_ 546 SYNC_New_Attn_Event 1;
BA_ "U_T6_MCA_MY2020_Tx" SG_ 546 SYNC_New_Attn_Event 1;
BA_ "U_P702_MY2021_Tx" SG_ 546 SYNC_New_Attn_Event 1;
BA_ "U_CD542_MY2021_Rx" SG_ 546 SYNC_New_Attn_Event 1;
BA_ "U_T6_MCA_MY2020_Rx" SG_ 546 SYNC_New_Attn_Event 1;
BA_ "U_P702_MY2021_Rx" SG_ 546 SYNC_New_Attn_Event 1;
BA_ "GenSigSendType" SG_ 546 SYNC_New_Attn_Event 3;
BA_ "U_CD542_MY2021_Tx" SG_ 546 SYNC_Attn_Info_Audio 1;
BA_ "U_T6_MCA_MY2020_Tx" SG_ 546 SYNC_Attn_Info_Audio 1;
BA_ "U_P702_MY2021_Tx" SG_ 546 SYNC_Attn_Info_Audio 1;
BA_ "U_CD542_MY2021_Rx" SG_ 546 SYNC_Attn_Info_Audio 1;
BA_ "U_T6_MCA_MY2020_Rx" SG_ 546 SYNC_Attn_Info_Audio 1;
BA_ "U_P702_MY2021_Rx" SG_ 546 SYNC_Attn_Info_Audio 1;
BA_ "GenSigSendType" SG_ 546 SYNC_Attn_Info_Audio 3;
BA_ "U_CD542_MY2021_Tx" SG_ 546 Prompt_Directionality 1;
BA_ "U_T6_MCA_MY2020_Tx" SG_ 546 Prompt_Directionality 1;
BA_ "U_P702_MY2021_Tx" SG_ 546 Prompt_Directionality 1;
BA_ "U_CD542_MY2021_Rx" SG_ 546 Prompt_Directionality 1;
BA_ "U_T6_MCA_MY2020_Rx" SG_ 546 Prompt_Directionality 1;
BA_ "U_P702_MY2021_Rx" SG_ 546 Prompt_Directionality 1;
BA_ "GenSigSendType" SG_ 546 Prompt_Directionality 3;
BA_ "U_CD542_MY2021_Tx" SG_ 546 Audible_Beep 1;
BA_ "U_T6_MCA_MY2020_Tx" SG_ 546 Audible_Beep 1;
BA_ "U_P702_MY2021_Tx" SG_ 546 Audible_Beep 1;
BA_ "U_CD542_MY2021_Rx" SG_ 546 Audible_Beep 1;
BA_ "U_T6_MCA_MY2020_Rx" SG_ 546 Audible_Beep 1;
BA_ "U_P702_MY2021_Rx" SG_ 546 Audible_Beep 1;
BA_ "GenSigSendType" SG_ 546 Audible_Beep 3;
BA_ "U_CD542_MY2021_Tx" SG_ 546 Alert_Chan 1;
BA_ "U_T6_MCA_MY2020_Tx" SG_ 546 Alert_Chan 1;
BA_ "U_P702_MY2021_Tx" SG_ 546 Alert_Chan 1;
BA_ "U_CD542_MY2021_Rx" SG_ 546 Alert_Chan 1;
BA_ "U_T6_MCA_MY2020_Rx" SG_ 546 Alert_Chan 1;
BA_ "U_P702_MY2021_Rx" SG_ 546 Alert_Chan 1;
BA_ "GenSigSendType" SG_ 546 Alert_Chan 3;
BA_ "U_CD542_MY2021_Rx" SG_ 1186 AwdDrvMde_D2_Stat 1;
BA_ "U_T6_MCA_MY2020_Rx" SG_ 1186 AwdDrvMde_D2_Stat 1;
BA_ "U_T6_MCA_MY2020_Rx" SG_ 1186 FrontDiffLckLamp_D_Rq 1;
BA_ "U_T6_MCA_MY2020_Rx" SG_ 1186 FrontDiffLckMsg_D_Rq 1;
BA_ "U_T6_MCA_MY2020_Rx" SG_ 1186 AwdStat2_D_RqDsply 1;
BA_ "U_P702_MY2021_Rx" SG_ 1186 RearDiffLckLamp_D_Rq 1;
BA_ "U_CD542_MY2021_Rx" SG_ 1186 RearDiffLckLamp_D_Rq 1;
BA_ "U_T6_MCA_MY2020_Rx" SG_ 1186 RearDiffLckLamp_D_Rq 1;
BA_ "GenSigStartValue" SG_ 1186 FrontDiffLck_Tq_Actl 16382;
BA_ "GenSigStartValue" SG_ 1186 SelDrvMdeAwd2_D_Stat 31;
BA_ "GenSigStartValueInteger" SG_ 1186 SelDrvMdeAwd2_D_Stat 31;
BA_ "U_CD542_MY2021_Rx" SG_ 1186 RearDiffLckMsg_D_Rq 1;
BA_ "U_T6_MCA_MY2020_Rx" SG_ 1186 RearDiffLckMsg_D_Rq 1;
BA_ "U_P702_MY2021_Rx" SG_ 1186 RearDiffLckMsg_D_Rq 1;
BA_ "U_CD542_MY2021_Rx" SG_ 1186 LsdSrvcRqd_B_Rq 1;
BA_ "U_T6_MCA_MY2020_Rx" SG_ 1186 LsdSrvcRqd_B_Rq 1;
BA_ "U_P702_MY2021_Rx" SG_ 1186 LsdSrvcRqd_B_Rq 1;
BA_ "U_CD542_MY2021_Rx" SG_ 1130 DrvSlipCtlOffLamp_D_Rq_UB 1;
BA_ "U_T6_MCA_MY2020_Rx" SG_ 1130 DrvSlipCtlOffLamp_D_Rq_UB 1;
BA_ "U_P702_MY2021_Rx" SG_ 1130 DrvSlipCtlOffLamp_D_Rq_UB 1;
BA_ "U_CD542_MY2021_Rx" SG_ 1130 DrvSlipCtlMdeMsg_D_Rq_UB 1;
BA_ "U_T6_MCA_MY2020_Rx" SG_ 1130 DrvSlipCtlMdeMsg_D_Rq_UB 1;
BA_ "U_P702_MY2021_Rx" SG_ 1130 DrvSlipCtlMdeMsg_D_Rq_UB 1;
BA_ "U_CD542_MY2021_Rx" SG_ 1130 DrvSlipCtlOffLamp_D_Rq 1;
BA_ "U_T6_MCA_MY2020_Rx" SG_ 1130 DrvSlipCtlOffLamp_D_Rq 1;
BA_ "U_P702_MY2021_Rx" SG_ 1130 DrvSlipCtlOffLamp_D_Rq 1;
BA_ "GenSigSendType" SG_ 1130 DrvSlipCtlOffLamp_D_Rq 3;
BA_ "U_CD542_MY2021_Rx" SG_ 1130 DrvSlipCtlMdeMsg_D_Rq 1;
BA_ "U_T6_MCA_MY2020_Rx" SG_ 1130 DrvSlipCtlMdeMsg_D_Rq 1;
BA_ "U_P702_MY2021_Rx" SG_ 1130 DrvSlipCtlMdeMsg_D_Rq 1;
BA_ "GenSigSendType" SG_ 1130 DrvSlipCtlMdeMsg_D_Rq 3;
BA_ "U_T6_MCA_MY2020_Rx" SG_ 1130 HtrnWarnLamp_B_Dsply_UB 1;
BA_ "U_P702_MY2021_Rx" SG_ 1130 HtrnWarnLamp_B_Dsply_UB 1;
BA_ "U_T6_MCA_MY2020_Rx" SG_ 1130 HtrnWarnLamp_B_Dsply 1;
BA_ "U_P702_MY2021_Rx" SG_ 1130 HtrnWarnLamp_B_Dsply 1;
BA_ "GenSigSendType" SG_ 1130 HtrnWarnLamp_B_Dsply 3;
BA_ "U_CD542_MY2021_Rx" SG_ 1130 HtrnSrvcRqd_B_Dsply_UB 1;
BA_ "U_T6_MCA_MY2020_Rx" SG_ 1130 HtrnSrvcRqd_B_Dsply_UB 1;
BA_ "U_P702_MY2021_Rx" SG_ 1130 HtrnSrvcRqd_B_Dsply_UB 1;
BA_ "U_CD542_MY2021_Rx" SG_ 1130 HtrnSrvcRqd_B_Dsply 1;
BA_ "U_T6_MCA_MY2020_Rx" SG_ 1130 HtrnSrvcRqd_B_Dsply 1;
BA_ "U_P702_MY2021_Rx" SG_ 1130 HtrnSrvcRqd_B_Dsply 1;
BA_ "GenSigSendType" SG_ 1130 HtrnSrvcRqd_B_Dsply 3;
BA_ "U_T6_MCA_MY2020_Rx" SG_ 1130 ChrgrSrvcRqd_B_Rq_UB 1;
BA_ "U_P702_MY2021_Rx" SG_ 1130 ChrgrSrvcRqd_B_Rq_UB 1;
BA_ "U_CD542_MY2021_Rx" SG_ 1130 ChrgrSrvcRqd_B_Rq 1;
BA_ "U_T6_MCA_MY2020_Rx" SG_ 1130 ChrgrSrvcRqd_B_Rq 1;
BA_ "U_P702_MY2021_Rx" SG_ 1130 ChrgrSrvcRqd_B_Rq 1;
BA_ "GenSigSendType" SG_ 1130 ChrgrSrvcRqd_B_Rq 3;
BA_ "U_CD542_MY2021_Rx" SG_ 1130 BattTracSrvcRqd_B_Rq_UB 1;
BA_ "U_P702_MY2021_Rx" SG_ 1130 BattTracSrvcRqd_B_Rq_UB 1;
BA_ "U_CD542_MY2021_Rx" SG_ 1130 BattTracSrvcRqd_B_Rq 1;
BA_ "U_T6_MCA_MY2020_Rx" SG_ 1130 BattTracSrvcRqd_B_Rq 1;
BA_ "U_P702_MY2021_Rx" SG_ 1130 BattTracSrvcRqd_B_Rq 1;
BA_ "GenSigSendType" SG_ 1130 BattTracSrvcRqd_B_Rq 3;
BA_ "U_T6_MCA_MY2020_Rx" SG_ 1130 BrkPadMsgTxt_D_Rq_UB 1;
BA_ "U_T6_MCA_MY2020_Rx" SG_ 1130 BrkPadMsgTxt_D_Rq 1;
BA_ "GenSigSendType" SG_ 1130 BrkPadMsgTxt_D_Rq 3;
BA_ "U_T6_MCA_MY2020_Rx" SG_ 1130 SuspDrvMde_D_Stat 1;
BA_ "U_T6_MCA_MY2020_Rx" SG_ 1130 SuspDrvMde_D_Stat_UB 1;
BA_ "U_T6_MCA_MY2020_Rx" SG_ 1042 TrlrAnCalib_Pc_Actl 1;
BA_ "U_CD542_MY2021_Rx" SG_ 1042 VehRol_An_Dsply_UB 1;
BA_ "U_T6_MCA_MY2020_Rx" SG_ 1042 VehRol_An_Dsply_UB 1;
BA_ "U_P702_MY2021_Rx" SG_ 1042 VehRol_An_Dsply_UB 1;
BA_ "U_CD542_MY2021_Rx" SG_ 1042 VehPtch_An_Dsply_UB 1;
BA_ "U_T6_MCA_MY2020_Rx" SG_ 1042 VehPtch_An_Dsply_UB 1;
BA_ "U_P702_MY2021_Rx" SG_ 1042 VehPtch_An_Dsply_UB 1;
BA_ "U_CD542_MY2021_Rx" SG_ 1042 VehRol_An_Dsply 1;
BA_ "U_T6_MCA_MY2020_Rx" SG_ 1042 VehRol_An_Dsply 1;
BA_ "U_P702_MY2021_Rx" SG_ 1042 VehRol_An_Dsply 1;
BA_ "GenSigStartValueInteger" SG_ 1042 VehRol_An_Dsply 64;
BA_ "U_CD542_MY2021_Rx" SG_ 1042 VehPtch_An_Dsply 1;
BA_ "U_T6_MCA_MY2020_Rx" SG_ 1042 VehPtch_An_Dsply 1;
BA_ "U_P702_MY2021_Rx" SG_ 1042 VehPtch_An_Dsply 1;
BA_ "GenSigStartValueInteger" SG_ 1042 VehPtch_An_Dsply 64;
BA_ "U_P702_MY2021_Rx" SG_ 1042 TrlrBrk_Pc_Rq_UB 1;
BA_ "U_T6_MCA_MY2020_Rx" SG_ 1042 TrlrBrk_Pc_Rq_UB 1;
BA_ "U_P702_MY2021_Rx" SG_ 1042 TrlrBrk_Pc_Rq 1;
BA_ "U_T6_MCA_MY2020_Rx" SG_ 1042 TrlrBrk_Pc_Rq 1;
BA_ "U_T6_MCA_MY2020_Rx" SG_ 1042 VehYaw_W_Actl_UB 1;
BA_ "U_P702_MY2021_Rx" SG_ 1042 VehYaw_W_Actl_UB 1;
BA_ "U_T6_MCA_MY2020_Rx" SG_ 1042 VehYaw_W_Actl 1;
BA_ "U_P702_MY2021_Rx" SG_ 1042 VehYaw_W_Actl 1;
BA_ "GenSigStartValue" SG_ 1042 VehYaw_W_Actl 65534;
BA_ "GenSigStartValueInteger" SG_ 1042 VehYaw_W_Actl 65534;
BA_ "U_T6_MCA_MY2020_Tx" SG_ 1093 TrlBrkInitOut_D_Stat 1;
BA_ "U_P702_MY2021_Tx" SG_ 1093 TrlBrkInitOut_D_Stat 1;
BA_ "U_T6_MCA_MY2020_Rx" SG_ 1093 TrlBrkInitOut_D_Stat 1;
BA_ "U_P702_MY2021_Rx" SG_ 1093 TrlBrkInitOut_D_Stat 1;
BA_ "U_T6_MCA_MY2020_Tx" SG_ 1093 TrlrBrkOut_No_Dsply 1;
BA_ "U_P702_MY2021_Tx" SG_ 1093 TrlrBrkOut_No_Dsply 1;
BA_ "U_T6_MCA_MY2020_Rx" SG_ 1093 TrlrBrkOut_No_Dsply 1;
BA_ "U_P702_MY2021_Rx" SG_ 1093 TrlrBrkOut_No_Dsply 1;
BA_ "U_T6_MCA_MY2020_Tx" SG_ 1093 TrlrBrkMde_D_Actl 1;
BA_ "U_P702_MY2021_Tx" SG_ 1093 TrlrBrkMde_D_Actl 1;
BA_ "U_T6_MCA_MY2020_Rx" SG_ 1093 TrlrBrkMde_D_Actl 1;
BA_ "U_P702_MY2021_Rx" SG_ 1093 TrlrBrkMde_D_Actl 1;
BA_ "U_T6_MCA_MY2020_Tx" SG_ 1093 TrlrBrkGain_No_Actl 1;
BA_ "U_P702_MY2021_Tx" SG_ 1093 TrlrBrkGain_No_Actl 1;
BA_ "U_CD542_MY2021_Rx" SG_ 1093 TrlrBrkGain_No_Actl 1;
BA_ "U_T6_MCA_MY2020_Rx" SG_ 1093 TrlrBrkGain_No_Actl 1;
BA_ "U_P702_MY2021_Rx" SG_ 1093 TrlrBrkGain_No_Actl 1;
BA_ "U_T6_MCA_MY2020_Tx" SG_ 1093 TrlrBrkDsply_B_Rq 1;
BA_ "U_P702_MY2021_Tx" SG_ 1093 TrlrBrkDsply_B_Rq 1;
BA_ "U_T6_MCA_MY2020_Rx" SG_ 1093 TrlrBrkDsply_B_Rq 1;
BA_ "U_P702_MY2021_Rx" SG_ 1093 TrlrBrkDsply_B_Rq 1;
BA_ "U_T6_MCA_MY2020_Tx" SG_ 1093 TrlrBrkDcnnt_B_Actl 1;
BA_ "U_P702_MY2021_Tx" SG_ 1093 TrlrBrkDcnnt_B_Actl 1;
BA_ "U_CD542_MY2021_Rx" SG_ 1093 TrlrBrkDcnnt_B_Actl 1;
BA_ "U_T6_MCA_MY2020_Rx" SG_ 1093 TrlrBrkDcnnt_B_Actl 1;
BA_ "U_P702_MY2021_Rx" SG_ 1093 TrlrBrkDcnnt_B_Actl 1;
BA_ "U_T6_MCA_MY2020_Tx" SG_ 1093 TrlrBrkActCnnct_B_Actl 1;
BA_ "U_P702_MY2021_Tx" SG_ 1093 TrlrBrkActCnnct_B_Actl 1;
BA_ "U_CD542_MY2021_Rx" SG_ 1093 TrlrBrkActCnnct_B_Actl 1;
BA_ "U_T6_MCA_MY2020_Rx" SG_ 1093 TrlrBrkActCnnct_B_Actl 1;
BA_ "U_P702_MY2021_Rx" SG_ 1093 TrlrBrkActCnnct_B_Actl 1;
BA_ "U_T6_MCA_MY2020_Tx" SG_ 1093 StopLamp_B_RqTrlrBrk 1;
BA_ "U_P702_MY2021_Tx" SG_ 1093 StopLamp_B_RqTrlrBrk 1;
BA_ "ContentDependant" SG_ 1093 StopLamp_B_RqTrlrBrk 1;
BA_ "U_T6_MCA_MY2020_Tx" SG_ 1093 TrlrBrkCtl_B_Falt 1;
BA_ "U_P702_MY2021_Tx" SG_ 1093 TrlrBrkCtl_B_Falt 1;
BA_ "U_CD542_MY2021_Rx" SG_ 1093 TrlrBrkCtl_B_Falt 1;
BA_ "U_T6_MCA_MY2020_Rx" SG_ 1093 TrlrBrkCtl_B_Falt 1;
BA_ "U_P702_MY2021_Rx" SG_ 1093 TrlrBrkCtl_B_Falt 1;
BA_ "U_T6_MCA_MY2020_Tx" SG_ 1093 TrlrBrkActCirct_B_Falt 1;
BA_ "U_P702_MY2021_Tx" SG_ 1093 TrlrBrkActCirct_B_Falt 1;
BA_ "U_CD542_MY2021_Rx" SG_ 1093 TrlrBrkActCirct_B_Falt 1;
BA_ "U_T6_MCA_MY2020_Rx" SG_ 1093 TrlrBrkActCirct_B_Falt 1;
BA_ "U_P702_MY2021_Rx" SG_ 1093 TrlrBrkActCirct_B_Falt 1;
BA_ "U_T6_MCA_MY2020_Rx" SG_ 1138 ActChrgEndYr_No2_Actl 1;
BA_ "U_T6_MCA_MY2020_Rx" SG_ 1138 BattChrgTrgtLMin_T_Est 1;
BA_ "U_P702_MY2021_Rx" SG_ 1138 BattChrgTrgtLMin_T_Est 1;
BA_ "U_CD542_MY2021_Rx" SG_ 1138 ActChrgEndYr_No_Actl 1;
BA_ "U_T6_MCA_MY2020_Rx" SG_ 1138 ActChrgEndYr_No_Actl 1;
BA_ "U_P702_MY2021_Rx" SG_ 1138 ActChrgEndYr_No_Actl 1;
BA_ "U_CD542_MY2021_Rx" SG_ 1138 ActChrgEndMnth_No_Actl 1;
BA_ "U_T6_MCA_MY2020_Rx" SG_ 1138 ActChrgEndMnth_No_Actl 1;
BA_ "U_P702_MY2021_Rx" SG_ 1138 ActChrgEndMnth_No_Actl 1;
BA_ "GenSigStartValue" SG_ 1138 ActChrgEndMnth_No_Actl 1;
BA_ "GenSigStartValueInteger" SG_ 1138 ActChrgEndMnth_No_Actl 1;
BA_ "U_CD542_MY2021_Rx" SG_ 1138 ActChrgEndMin_No_Actl 1;
BA_ "U_T6_MCA_MY2020_Rx" SG_ 1138 ActChrgEndMin_No_Actl 1;
BA_ "U_P702_MY2021_Rx" SG_ 1138 ActChrgEndMin_No_Actl 1;
BA_ "U_CD542_MY2021_Rx" SG_ 1138 ActChrgEndHr_No_Actl 1;
BA_ "U_T6_MCA_MY2020_Rx" SG_ 1138 ActChrgEndHr_No_Actl 1;
BA_ "U_P702_MY2021_Rx" SG_ 1138 ActChrgEndHr_No_Actl 1;
BA_ "U_CD542_MY2021_Rx" SG_ 1138 ActChrgEndDay_No_Actl 1;
BA_ "U_T6_MCA_MY2020_Rx" SG_ 1138 ActChrgEndDay_No_Actl 1;
BA_ "U_P702_MY2021_Rx" SG_ 1138 ActChrgEndDay_No_Actl 1;
BA_ "GenSigStartValue" SG_ 1138 ActChrgEndDay_No_Actl 1;
BA_ "GenSigStartValueInteger" SG_ 1138 ActChrgEndDay_No_Actl 1;
BA_ "U_T6_MCA_MY2020_Rx" SG_ 1139 ActChrgStrtYr_No2_Actl 1;
BA_ "U_T6_MCA_MY2020_Rx" SG_ 1139 BattChrgTrgtLMax_T_Est 1;
BA_ "U_P702_MY2021_Rx" SG_ 1139 BattChrgTrgtLMax_T_Est 1;
BA_ "U_CD542_MY2021_Rx" SG_ 1139 ActChrgStrtYr_No_Actl 1;
BA_ "U_T6_MCA_MY2020_Rx" SG_ 1139 ActChrgStrtYr_No_Actl 1;
BA_ "U_P702_MY2021_Rx" SG_ 1139 ActChrgStrtYr_No_Actl 1;
BA_ "U_CD542_MY2021_Rx" SG_ 1139 ActChrgStrtMin_No_Actl 1;
BA_ "U_T6_MCA_MY2020_Rx" SG_ 1139 ActChrgStrtMin_No_Actl 1;
BA_ "U_P702_MY2021_Rx" SG_ 1139 ActChrgStrtMin_No_Actl 1;
BA_ "U_CD542_MY2021_Rx" SG_ 1139 ActChrgStrtHr_No_Actl 1;
BA_ "U_T6_MCA_MY2020_Rx" SG_ 1139 ActChrgStrtHr_No_Actl 1;
BA_ "U_P702_MY2021_Rx" SG_ 1139 ActChrgStrtHr_No_Actl 1;
BA_ "U_CD542_MY2021_Rx" SG_ 1139 ActChrgStrtDay_No_Actl 1;
BA_ "U_T6_MCA_MY2020_Rx" SG_ 1139 ActChrgStrtDay_No_Actl 1;
BA_ "U_P702_MY2021_Rx" SG_ 1139 ActChrgStrtDay_No_Actl 1;
BA_ "GenSigStartValue" SG_ 1139 ActChrgStrtDay_No_Actl 1;
BA_ "GenSigStartValueInteger" SG_ 1139 ActChrgStrtDay_No_Actl 1;
BA_ "U_CD542_MY2021_Rx" SG_ 1139 ActChrgStrMnth_No_Actl 1;
BA_ "U_T6_MCA_MY2020_Rx" SG_ 1139 ActChrgStrMnth_No_Actl 1;
BA_ "U_P702_MY2021_Rx" SG_ 1139 ActChrgStrMnth_No_Actl 1;
BA_ "GenSigStartValue" SG_ 1139 ActChrgStrMnth_No_Actl 1;
BA_ "GenSigStartValueInteger" SG_ 1139 ActChrgStrMnth_No_Actl 1;
BA_ "U_CD542_MY2021_Rx" SG_ 1145 EstmChrgTimeLP_St 1;
BA_ "U_T6_MCA_MY2020_Rx" SG_ 1145 EstmChrgTimeLP_St 1;
BA_ "U_P702_MY2021_Rx" SG_ 1145 EstmChrgTimeLP_St 1;
BA_ "U_CD542_MY2021_Rx" SG_ 1145 EstmChrgTimeHP_St 1;
BA_ "U_T6_MCA_MY2020_Rx" SG_ 1145 EstmChrgTimeHP_St 1;
BA_ "U_P702_MY2021_Rx" SG_ 1145 EstmChrgTimeHP_St 1;
BA_ "U_CD542_MY2021_Rx" SG_ 1145 ChargeNowDuration_St 1;
BA_ "U_T6_MCA_MY2020_Rx" SG_ 1145 ChargeNowDuration_St 1;
BA_ "GenSigStartValue" SG_ 1145 VehElRngeNut_L2_Dsply 8190;
BA_ "U_CD542_MY2021_Rx" SG_ 1145 VehElRngeNut_L_Dsply 1;
BA_ "U_T6_MCA_MY2020_Rx" SG_ 1145 VehElRngeNut_L_Dsply 1;
BA_ "U_P702_MY2021_Rx" SG_ 1145 VehElRngeNut_L_Dsply 1;
BA_ "U_CD542_MY2021_Rx" SG_ 1145 NxtUsgSocEst_Pc_Dsply 1;
BA_ "U_T6_MCA_MY2020_Rx" SG_ 1145 NxtUsgSocEst_Pc_Dsply 1;
BA_ "U_P702_MY2021_Rx" SG_ 1145 NxtUsgSocEst_Pc_Dsply 1;
BA_ "U_CD542_MY2021_Tx" SG_ 1232 AHU_EnsembleName_St 1;
BA_ "U_T6_MCA_MY2020_Tx" SG_ 1232 AHU_EnsembleName_St 1;
BA_ "U_P702_MY2021_Tx" SG_ 1232 AHU_EnsembleName_St 1;
BA_ "U_CD542_MY2021_Rx" SG_ 1232 AHU_EnsembleName_St 1;
BA_ "U_T6_MCA_MY2020_Rx" SG_ 1232 AHU_EnsembleName_St 1;
BA_ "U_P702_MY2021_Rx" SG_ 1232 AHU_EnsembleName_St 1;
BA_ "U_T6_MCA_MY2020_Tx" SG_ 1232 AHU_AutoConfigOcc_Shakr 1;
BA_ "U_P702_MY2021_Tx" SG_ 1232 AHU_AutoConfigOcc_Shakr 1;
BA_ "U_CD542_MY2021_Rx" SG_ 1232 AHU_AutoConfigOcc_Shakr 1;
BA_ "U_T6_MCA_MY2020_Rx" SG_ 1232 AHU_AutoConfigOcc_Shakr 1;
BA_ "U_P702_MY2021_Rx" SG_ 1232 AHU_AutoConfigOcc_Shakr 1;
BA_ "U_CD542_MY2021_Tx" SG_ 1232 AHU_AutoConfigOcc_Rear 1;
BA_ "U_T6_MCA_MY2020_Tx" SG_ 1232 AHU_AutoConfigOcc_Rear 1;
BA_ "U_P702_MY2021_Tx" SG_ 1232 AHU_AutoConfigOcc_Rear 1;
BA_ "U_CD542_MY2021_Rx" SG_ 1232 AHU_AutoConfigOcc_Rear 1;
BA_ "U_T6_MCA_MY2020_Rx" SG_ 1232 AHU_AutoConfigOcc_Rear 1;
BA_ "U_P702_MY2021_Rx" SG_ 1232 AHU_AutoConfigOcc_Rear 1;
BA_ "U_CD542_MY2021_Tx" SG_ 1232 AHU_AutoConfigOcc_Front 1;
BA_ "U_T6_MCA_MY2020_Tx" SG_ 1232 AHU_AutoConfigOcc_Front 1;
BA_ "U_P702_MY2021_Tx" SG_ 1232 AHU_AutoConfigOcc_Front 1;
BA_ "U_CD542_MY2021_Rx" SG_ 1232 AHU_AutoConfigOcc_Front 1;
BA_ "U_T6_MCA_MY2020_Rx" SG_ 1232 AHU_AutoConfigOcc_Front 1;
BA_ "U_P702_MY2021_Rx" SG_ 1232 AHU_AutoConfigOcc_Front 1;
BA_ "U_T6_MCA_MY2020_Tx" SG_ 1232 AHU_AutoConfigOcc_Drvr 1;
BA_ "U_P702_MY2021_Tx" SG_ 1232 AHU_AutoConfigOcc_Drvr 1;
BA_ "U_CD542_MY2021_Rx" SG_ 1232 AHU_AutoConfigOcc_Drvr 1;
BA_ "U_T6_MCA_MY2020_Rx" SG_ 1232 AHU_AutoConfigOcc_Drvr 1;
BA_ "U_P702_MY2021_Rx" SG_ 1232 AHU_AutoConfigOcc_Drvr 1;
BA_ "U_T6_MCA_MY2020_Tx" SG_ 1232 AHU_AutoConfigOcc_Cnvrt 1;
BA_ "U_P702_MY2021_Tx" SG_ 1232 AHU_AutoConfigOcc_Cnvrt 1;
BA_ "U_CD542_MY2021_Rx" SG_ 1232 AHU_AutoConfigOcc_Cnvrt 1;
BA_ "U_T6_MCA_MY2020_Rx" SG_ 1232 AHU_AutoConfigOcc_Cnvrt 1;
BA_ "U_P702_MY2021_Rx" SG_ 1232 AHU_AutoConfigOcc_Cnvrt 1;
BA_ "U_T6_MCA_MY2020_Tx" SG_ 1232 AHU_AutoConfigOcc_Allst 1;
BA_ "U_P702_MY2021_Tx" SG_ 1232 AHU_AutoConfigOcc_Allst 1;
BA_ "U_CD542_MY2021_Rx" SG_ 1232 AHU_AutoConfigOcc_Allst 1;
BA_ "U_T6_MCA_MY2020_Rx" SG_ 1232 AHU_AutoConfigOcc_Allst 1;
BA_ "U_P702_MY2021_Rx" SG_ 1232 AHU_AutoConfigOcc_Allst 1;
BA_ "U_CD542_MY2021_Tx" SG_ 1232 ACU_DigitalRadio_St 1;
BA_ "U_T6_MCA_MY2020_Tx" SG_ 1232 ACU_DigitalRadio_St 1;
BA_ "U_P702_MY2021_Tx" SG_ 1232 ACU_DigitalRadio_St 1;
BA_ "U_CD542_MY2021_Rx" SG_ 1232 ACU_DigitalRadio_St 1;
BA_ "U_P702_MY2021_Rx" SG_ 1232 ACU_DigitalRadio_St 1;
BA_ "U_T6_MCA_MY2020_Rx" SG_ 1232 ACU_DigitalRadio_St 1;
BA_ "U_CD542_MY2021_Tx" SG_ 1232 ACU_Configuration 1;
BA_ "U_T6_MCA_MY2020_Tx" SG_ 1232 ACU_Configuration 1;
BA_ "U_P702_MY2021_Tx" SG_ 1232 ACU_Configuration 1;
BA_ "U_P702_MY2021_Rx" SG_ 1232 ACU_Configuration 1;
BA_ "U_CD542_MY2021_Rx" SG_ 1232 ACU_Configuration 1;
BA_ "U_T6_MCA_MY2020_Rx" SG_ 1232 ACU_Configuration 1;
BA_ "U_CD542_MY2021_Tx" SG_ 1232 ACU_MediaPlayer_St 1;
BA_ "U_T6_MCA_MY2020_Tx" SG_ 1232 ACU_MediaPlayer_St 1;
BA_ "U_P702_MY2021_Tx" SG_ 1232 ACU_MediaPlayer_St 1;
BA_ "U_P702_MY2021_Rx" SG_ 1232 ACU_MediaPlayer_St 1;
BA_ "U_CD542_MY2021_Rx" SG_ 1232 ACU_MediaPlayer_St 1;
BA_ "U_T6_MCA_MY2020_Rx" SG_ 1232 ACU_MediaPlayer_St 1;
BA_ "U_T6_MCA_MY2020_Rx" SG_ 1141 AirAmbTePlgIn_D_Dsply 1;
BA_ "GenSigStartValue" SG_ 1141 MtrTrac2_Tq_Actl 4095;
BA_ "GenSigStartValueInteger" SG_ 1141 MtrTrac2_Tq_Actl 4095;
BA_ "U_T6_MCA_MY2020_Rx" SG_ 1141 PtRmtRprt_D_Rq 1;
BA_ "WakeupSignal" SG_ 1141 PtRmtRprt_D_Rq 1;
BA_ "U_T6_MCA_MY2020_Rx" SG_ 1141 PreCondID_No_Rq 1;
BA_ "U_T6_MCA_MY2020_Rx" SG_ 1141 NxtUsg_D_Rq 1;
BA_ "U_CD542_MY2021_Rx" SG_ 1141 NtfctnConflict1_D_Rq 1;
BA_ "U_T6_MCA_MY2020_Rx" SG_ 1141 NtfctnConflict1_D_Rq 1;
BA_ "U_P702_MY2021_Rx" SG_ 1141 NtfctnConflict1_D_Rq 1;
BA_ "U_T6_MCA_MY2020_Rx" SG_ 1141 ChrgLocID_No_Rq 1;
BA_ "U_T6_MCA_MY2020_Rx" SG_ 1141 ChrgLocGPS_D_Rq 1;
BA_ "U_CD542_MY2021_Rx" SG_ 1141 OfbChrgSetSync_D_Stat 1;
BA_ "U_T6_MCA_MY2020_Rx" SG_ 1141 OfbChrgSetSync_D_Stat 1;
BA_ "U_CD542_MY2021_Rx" SG_ 631 RearPassWindowPos 1;
BA_ "U_T6_MCA_MY2020_Rx" SG_ 631 RearPassWindowPos 1;
BA_ "U_P702_MY2021_Rx" SG_ 631 RearPassWindowPos 1;
BA_ "GenSigSendType" SG_ 631 RearPassWindowPos 3;
BA_ "WakeupSignal" SG_ 631 RearPassWindowPos 1;
BA_ "U_CD542_MY2021_Rx" SG_ 631 RearDriverWindowPos 1;
BA_ "U_T6_MCA_MY2020_Rx" SG_ 631 RearDriverWindowPos 1;
BA_ "U_P702_MY2021_Rx" SG_ 631 RearDriverWindowPos 1;
BA_ "GenSigSendType" SG_ 631 RearDriverWindowPos 3;
BA_ "WakeupSignal" SG_ 631 RearDriverWindowPos 1;
BA_ "U_CD542_MY2021_Rx" SG_ 631 PassWindowPosition 1;
BA_ "U_T6_MCA_MY2020_Rx" SG_ 631 PassWindowPosition 1;
BA_ "GenSigSendType" SG_ 631 PassWindowPosition 3;
BA_ "WakeupSignal" SG_ 631 PassWindowPosition 1;
BA_ "U_CD542_MY2021_Rx" SG_ 631 RearPassWindowPos_UB 1;
BA_ "U_T6_MCA_MY2020_Rx" SG_ 631 RearPassWindowPos_UB 1;
BA_ "U_P702_MY2021_Rx" SG_ 631 RearPassWindowPos_UB 1;
BA_ "U_CD542_MY2021_Rx" SG_ 631 RearDriverWindowPos_UB 1;
BA_ "U_T6_MCA_MY2020_Rx" SG_ 631 RearDriverWindowPos_UB 1;
BA_ "U_P702_MY2021_Rx" SG_ 631 RearDriverWindowPos_UB 1;
BA_ "U_CD542_MY2021_Rx" SG_ 631 PassWindowPosition_UB 1;
BA_ "U_T6_MCA_MY2020_Rx" SG_ 631 PassWindowPosition_UB 1;
BA_ "U_CD542_MY2021_Rx" SG_ 631 DriverWindowPosition 1;
BA_ "U_T6_MCA_MY2020_Rx" SG_ 631 DriverWindowPosition 1;
BA_ "U_P702_MY2021_Rx" SG_ 631 DriverWindowPosition 1;
BA_ "GenSigSendType" SG_ 631 DriverWindowPosition 3;
BA_ "WakeupSignal" SG_ 631 DriverWindowPosition 1;
BA_ "U_CD542_MY2021_Rx" SG_ 631 DriverWindowPosition_UB 1;
BA_ "U_T6_MCA_MY2020_Rx" SG_ 631 DriverWindowPosition_UB 1;
BA_ "U_P702_MY2021_Rx" SG_ 631 DriverWindowPosition_UB 1;
BA_ "U_T6_MCA_MY2020_Rx" SG_ 631 CnvtTopPos_Up_Stat 1;
BA_ "U_P702_MY2021_Rx" SG_ 631 CnvtTopPos_Up_Stat 1;
BA_ "GenSigSendType" SG_ 631 CnvtTopPos_Up_Stat 3;
BA_ "ContentDependant" SG_ 631 CnvtTopPos_Up_Stat 1;
BA_ "WakeupSignal" SG_ 631 CnvtTopPos_Up_Stat 1;
BA_ "U_CD542_MY2021_Rx" SG_ 631 Memory_Cmd 1;
BA_ "U_T6_MCA_MY2020_Rx" SG_ 631 Memory_Cmd 1;
BA_ "U_P702_MY2021_Rx" SG_ 631 Memory_Cmd 1;
BA_ "WakeupSignal" SG_ 631 Memory_Cmd 1;
BA_ "U_T6_MCA_MY2020_Rx" SG_ 631 CnvtTopPos_Up_Stat_UB 1;
BA_ "U_P702_MY2021_Rx" SG_ 631 CnvtTopPos_Up_Stat_UB 1;
BA_ "U_CD542_MY2021_Rx" SG_ 631 Memory_Cmd_UB 1;
BA_ "U_T6_MCA_MY2020_Rx" SG_ 631 Memory_Cmd_UB 1;
BA_ "U_P702_MY2021_Rx" SG_ 631 Memory_Cmd_UB 1;
BA_ "U_CD542_MY2021_Rx" SG_ 631 EstmChrgTimeLP_St 1;
BA_ "U_T6_MCA_MY2020_Rx" SG_ 631 EstmChrgTimeLP_St 1;
BA_ "U_P702_MY2021_Rx" SG_ 631 EstmChrgTimeLP_St 1;
BA_ "GenSigSendType" SG_ 631 EstmChrgTimeLP_St 3;
BA_ "U_CD542_MY2021_Rx" SG_ 631 EstmChrgTimeHP_St 1;
BA_ "U_T6_MCA_MY2020_Rx" SG_ 631 EstmChrgTimeHP_St 1;
BA_ "U_P702_MY2021_Rx" SG_ 631 EstmChrgTimeHP_St 1;
BA_ "GenSigSendType" SG_ 631 EstmChrgTimeHP_St 3;
BA_ "U_CD542_MY2021_Rx" SG_ 631 ChargeNowDuration_St 1;
BA_ "U_T6_MCA_MY2020_Rx" SG_ 631 ChargeNowDuration_St 1;
BA_ "GenSigSendType" SG_ 631 ChargeNowDuration_St 3;
BA_ "U_T6_MCA_MY2020_Rx" SG_ 631 CnvtTopMsgTxt_D_Rq_UB 1;
BA_ "U_T6_MCA_MY2020_Rx" SG_ 631 CnvtTopMsgTxt_D_Rq 1;
BA_ "WakeupSignal" SG_ 631 CnvtTopMsgTxt_D_Rq 1;
BA_ "U_T6_MCA_MY2020_Rx" SG_ 631 CnvtTopPos_Dn_Stat_UB 1;
BA_ "U_P702_MY2021_Rx" SG_ 631 CnvtTopPos_Dn_Stat_UB 1;
BA_ "U_T6_MCA_MY2020_Rx" SG_ 631 CnvtTopPos_Dn_Stat 1;
BA_ "U_P702_MY2021_Rx" SG_ 631 CnvtTopPos_Dn_Stat 1;
BA_ "ContentDependant" SG_ 631 CnvtTopPos_Dn_Stat 1;
BA_ "WakeupSignal" SG_ 631 CnvtTopPos_Dn_Stat 1;
BA_ "U_P702_MY2021_Rx" SG_ 631 EstmChrgTimeLP_St_UB 1;
BA_ "U_T6_MCA_MY2020_Rx" SG_ 631 EstmChrgTimeLP_St_UB 1;
BA_ "U_P702_MY2021_Rx" SG_ 631 EstmChrgTimeHP_St_UB 1;
BA_ "U_T6_MCA_MY2020_Rx" SG_ 631 EstmChrgTimeHP_St_UB 1;
BA_ "U_T6_MCA_MY2020_Rx" SG_ 631 ChargeNowDuration_St_UB 1;
BA_ "U_P702_MY2021_Rx" SG_ 631 ChargeNowDuration_St_UB 1;
BA_ "U_CD542_MY2021_Rx" SG_ 1140 RgenLongTerm_L_Dsply 1;
BA_ "U_T6_MCA_MY2020_Rx" SG_ 1140 RgenLongTerm_L_Dsply 1;
BA_ "U_CD542_MY2021_Rx" SG_ 1140 PreCondStat_D_Dsply 1;
BA_ "U_T6_MCA_MY2020_Rx" SG_ 1140 PreCondStat_D_Dsply 1;
BA_ "U_CD542_MY2021_Rx" SG_ 1140 RgenLongTerm_Pc_Dsply 1;
BA_ "U_T6_MCA_MY2020_Rx" SG_ 1140 RgenLongTerm_Pc_Dsply 1;
BA_ "U_CD542_MY2021_Rx" SG_ 1140 RgenEvntLvl_Pc_Dsply 1;
BA_ "U_T6_MCA_MY2020_Rx" SG_ 1140 RgenEvntLvl_Pc_Dsply 1;
BA_ "GenSigStartValue" SG_ 1140 RgenEvntLvl_Pc_Dsply 1022;
BA_ "GenSigStartValueInteger" SG_ 1140 RgenEvntLvl_Pc_Dsply 1023;
BA_ "U_CD542_MY2021_Rx" SG_ 1140 BrkEvntComplt_B_Dsply 1;
BA_ "U_T6_MCA_MY2020_Rx" SG_ 1140 BrkEvntComplt_B_Dsply 1;
BA_ "U_CD542_MY2021_Rx" SG_ 1140 ExtChrgrFalt_B_Dsply 1;
BA_ "U_T6_MCA_MY2020_Rx" SG_ 1140 ExtChrgrFalt_B_Dsply 1;
BA_ "U_T6_MCA_MY2020_Rx" SG_ 873 PwWhlLvl_Pc_Dsply 1;
BA_ "GenSigStartValue" SG_ 873 PwWhlLvl_Pc_Dsply 511;
BA_ "U_T6_MCA_MY2020_Rx" SG_ 873 VehVAnimation_Pc_Dsply 1;
BA_ "U_T6_MCA_MY2020_Rx" SG_ 873 BattTracEMaint_B_Dsply 1;
BA_ "U_P702_MY2021_Rx" SG_ 873 BattPwLvl2_Pc_Dsply 1;
BA_ "U_T6_MCA_MY2020_Rx" SG_ 873 BattPwLvl2_Pc_Dsply 1;
BA_ "GenSigStartValueInteger" SG_ 873 BattPwLvl2_Pc_Dsply 511;
BA_ "U_T6_MCA_MY2020_Rx" SG_ 873 EffRelTrgtOn_B_Dsply 1;
BA_ "U_T6_MCA_MY2020_Rx" SG_ 873 EffInstThres_Pc_Dsply 1;
BA_ "U_T6_MCA_MY2020_Rx" SG_ 873 EffInstLvl_Pc_Dsply 1;
BA_ "U_CD542_MY2021_Rx" SG_ 873 GpsElMdeActv_B_Dsply 1;
BA_ "U_T6_MCA_MY2020_Rx" SG_ 873 GpsElMdeActv_B_Dsply 1;
BA_ "U_P702_MY2021_Rx" SG_ 873 GpsElMdeActv_B_Dsply 1;
BA_ "U_T6_MCA_MY2020_Rx" SG_ 873 LoAirAmbPlgIn_B_Dsply 1;
BA_ "U_T6_MCA_MY2020_Rx" SG_ 871 VehAAnimation_Pc_Dsply 1;
BA_ "U_T6_MCA_MY2020_Rx" SG_ 871 BattElecPerf_D_Actl 1;
BA_ "U_T6_MCA_MY2020_Rx" SG_ 871 BattChrgTrgtLPt_T_Est 1;
BA_ "U_T6_MCA_MY2020_Rx" SG_ 871 BattChrgTrgSocPt_T_Est 1;
BA_ "U_T6_MCA_MY2020_Rx" SG_ 871 BattChrgCmpltPt_T_Est 1;
BA_ "U_T6_MCA_MY2020_Rx" SG_ 871 DrvEffLvlIncDec_D_Cmd 1;
BA_ "U_CD542_MY2021_Rx" SG_ 870 PolicePurstMde_B_Stat 1;
BA_ "U_T6_MCA_MY2020_Rx" SG_ 870 PolicePurstMde_B_Stat 1;
BA_ "U_CD542_MY2021_Rx" SG_ 870 RngPerChrgInst_L_Dsply 1;
BA_ "U_T6_MCA_MY2020_Rx" SG_ 870 RngPerChrgInst_L_Dsply 1;
BA_ "GenSigStartValue" SG_ 870 RngPerChrgInst_L_Dsply 4093;
BA_ "GenSigStartValueInteger" SG_ 870 RngPerChrgInst_L_Dsply 4094;
BA_ "U_CD542_MY2021_Rx" SG_ 870 ChkPlgtoStrt_D_Dsply 1;
BA_ "U_T6_MCA_MY2020_Rx" SG_ 870 ChkPlgtoStrt_D_Dsply 1;
BA_ "U_CD542_MY2021_Rx" SG_ 870 ElFuelFlw_Vl_Dsply 1;
BA_ "U_T6_MCA_MY2020_Rx" SG_ 870 ElFuelFlw_Vl_Dsply 1;
BA_ "U_P702_MY2021_Rx" SG_ 870 ElFuelFlw_Vl_Dsply 1;
BA_ "U_CD542_MY2021_Rx" SG_ 870 HybMdeLimMsgTxt_D_Rq 1;
BA_ "U_T6_MCA_MY2020_Rx" SG_ 870 HybMdeLimMsgTxt_D_Rq 1;
BA_ "U_CD542_MY2021_Rx" SG_ 870 HybMdeMsgTxt_D2_Rq 1;
BA_ "U_T6_MCA_MY2020_Rx" SG_ 870 HybMdeMsgTxt_D2_Rq 1;
BA_ "U_CD542_MY2021_Rx" SG_ 870 EngMdeMsgTxt_D_Rq 1;
BA_ "U_T6_MCA_MY2020_Rx" SG_ 870 EngMdeMsgTxt_D_Rq 1;
BA_ "U_T6_MCA_MY2020_Rx" SG_ 870 BattPwWhl_Pc_Dsply 1;
BA_ "U_CD542_MY2021_Rx" SG_ 870 EffRgenThres_Pc_Dsply 1;
BA_ "U_T6_MCA_MY2020_Rx" SG_ 870 EffRgenThres_Pc_Dsply 1;
BA_ "GenSigStartValue" SG_ 870 EffRgenThres_Pc_Dsply 1023;
BA_ "U_CD542_MY2021_Rx" SG_ 870 ShifOutNtrlMsgTxt_D_Rq 1;
BA_ "U_T6_MCA_MY2020_Rx" SG_ 870 ShifOutNtrlMsgTxt_D_Rq 1;
BA_ "U_P702_MY2021_Rx" SG_ 869 PwrFlowTxt_D_Dsply 1;
BA_ "U_T6_MCA_MY2020_Rx" SG_ 869 PwrFlowTxt_D_Dsply 1;
BA_ "U_P702_MY2021_Rx" SG_ 869 EngOnMsg2_D_Dsply 1;
BA_ "U_CD542_MY2021_Rx" SG_ 869 EngOnMsg2_D_Dsply 1;
BA_ "U_T6_MCA_MY2020_Rx" SG_ 869 EngOnMsg2_D_Dsply 1;
BA_ "U_P702_MY2021_Rx" SG_ 869 EngOnMsg1_D_Dsply 1;
BA_ "U_CD542_MY2021_Rx" SG_ 869 EngOnMsg1_D_Dsply 1;
BA_ "U_T6_MCA_MY2020_Rx" SG_ 869 EngOnMsg1_D_Dsply 1;
BA_ "U_CD542_MY2021_Rx" SG_ 869 FuelMaintMde_D_Dsply 1;
BA_ "U_T6_MCA_MY2020_Rx" SG_ 869 FuelMaintMde_D_Dsply 1;
BA_ "U_CD542_MY2021_Rx" SG_ 869 EffWhlLvl2_Pc_Dsply 1;
BA_ "U_T6_MCA_MY2020_Rx" SG_ 869 EffWhlLvl2_Pc_Dsply 1;
BA_ "U_P702_MY2021_Rx" SG_ 869 EffWhlLvl2_Pc_Dsply 1;
BA_ "GenSigStartValueInteger" SG_ 869 EffWhlLvl2_Pc_Dsply 511;
BA_ "U_CD542_MY2021_Rx" SG_ 869 RgenActv_B_Dsply 1;
BA_ "U_T6_MCA_MY2020_Rx" SG_ 869 RgenActv_B_Dsply 1;
BA_ "U_CD542_MY2021_Rx" SG_ 869 EffWhlThres_Pc_Dsply 1;
BA_ "U_T6_MCA_MY2020_Rx" SG_ 869 EffWhlThres_Pc_Dsply 1;
BA_ "U_P702_MY2021_Rx" SG_ 869 EffWhlThres_Pc_Dsply 1;
BA_ "U_P702_MY2021_Rx" SG_ 869 EffEAvg_Pc_Dsply 1;
BA_ "U_T6_MCA_MY2020_Rx" SG_ 869 EffEAvg_Pc_Dsply 1;
BA_ "U_P702_MY2021_Rx" SG_ 869 EngPwLvl_Pc_Dsply 1;
BA_ "U_T6_MCA_MY2020_Rx" SG_ 869 EngPwLvl_Pc_Dsply 1;
BA_ "U_CD542_MY2021_Rx" SG_ 869 EngOffTe_B_Dsply 1;
BA_ "U_T6_MCA_MY2020_Rx" SG_ 869 EngOffTe_B_Dsply 1;
BA_ "U_P702_MY2021_Rx" SG_ 869 EngOffTe_B_Dsply 1;
BA_ "U_CD542_MY2021_Rx" SG_ 869 EngActv_B_Dsply 1;
BA_ "U_T6_MCA_MY2020_Rx" SG_ 869 EngActv_B_Dsply 1;
BA_ "U_P702_MY2021_Rx" SG_ 869 EngActv_B_Dsply 1;
BA_ "U_CD542_MY2021_Rx" SG_ 869 EffWhlThresOn_B_Dsply 1;
BA_ "U_T6_MCA_MY2020_Rx" SG_ 869 EffWhlThresOn_B_Dsply 1;
BA_ "U_P702_MY2021_Rx" SG_ 869 EffWhlThresOn_B_Dsply 1;
BA_ "U_CD542_MY2021_Rx" SG_ 869 DchrgActv_B_Dsply 1;
BA_ "U_T6_MCA_MY2020_Rx" SG_ 869 DchrgActv_B_Dsply 1;
BA_ "U_T6_MCA_MY2020_Rx" SG_ 869 ChrgActv_B_Dsply 1;
BA_ "U_CD542_MY2021_Rx" SG_ 786 VehElRnge_L2_Dsply 1;
BA_ "U_T6_MCA_MY2020_Rx" SG_ 786 VehElRnge_L2_Dsply 1;
BA_ "GenSigStartValue" SG_ 786 VehElRnge_L2_Dsply 8191;
BA_ "U_CD542_MY2021_Rx" SG_ 786 RgenTrip_Pc_Dsply 1;
BA_ "U_T6_MCA_MY2020_Rx" SG_ 786 RgenTrip_Pc_Dsply 1;
BA_ "U_P702_MY2021_Rx" SG_ 786 RgenTrip_Pc_Dsply 1;
BA_ "U_CD542_MY2021_Rx" SG_ 786 RgenTrip_L_Dsply 1;
BA_ "U_T6_MCA_MY2020_Rx" SG_ 786 RgenTrip_L_Dsply 1;
BA_ "U_P702_MY2021_Rx" SG_ 786 RgenTrip_L_Dsply 1;
BA_ "GenSigStartValue" SG_ 786 RgenTrip_L_Dsply 65535;
BA_ "GenSigStartValueInteger" SG_ 786 RgenTrip_L_Dsply 65535;
BA_ "U_T6_MCA_MY2020_Rx" SG_ 786 VehElRngeCyc_L_Dsply 1;
BA_ "U_CD542_MY2021_Rx" SG_ 786 ChrgStat_D_Dsply 1;
BA_ "U_P702_MY2021_Rx" SG_ 786 ChrgStat_D_Dsply 1;
BA_ "U_T6_MCA_MY2020_Rx" SG_ 786 ChrgStat_D_Dsply 1;
BA_ "U_CD542_MY2021_Rx" SG_ 1095 Pers4Phone_D_Stat 1;
BA_ "U_T6_MCA_MY2020_Rx" SG_ 1095 Pers4Phone_D_Stat 1;
BA_ "U_P702_MY2021_Rx" SG_ 1095 Pers4Phone_D_Stat 1;
BA_ "U_CD542_MY2021_Rx" SG_ 1095 Pers3Phone_D_Stat 1;
BA_ "U_T6_MCA_MY2020_Rx" SG_ 1095 Pers3Phone_D_Stat 1;
BA_ "U_P702_MY2021_Rx" SG_ 1095 Pers3Phone_D_Stat 1;
BA_ "U_CD542_MY2021_Rx" SG_ 1095 Pers2Phone_D_Stat 1;
BA_ "U_T6_MCA_MY2020_Rx" SG_ 1095 Pers2Phone_D_Stat 1;
BA_ "U_P702_MY2021_Rx" SG_ 1095 Pers2Phone_D_Stat 1;
BA_ "U_CD542_MY2021_Rx" SG_ 1095 Pers1Phone_D_Stat 1;
BA_ "U_T6_MCA_MY2020_Rx" SG_ 1095 Pers1Phone_D_Stat 1;
BA_ "U_P702_MY2021_Rx" SG_ 1095 Pers1Phone_D_Stat 1;
BA_ "GenSigStartValue" SG_ 1095 HeadLghtOn_D_Rq 1;
BA_ "GenSigStartValueInteger" SG_ 1095 HeadLghtOn_D_Rq 1;
BA_ "WakeupSignal" SG_ 1095 HeadLghtOn_D_Rq 1;
BA_ "U_CD542_MY2021_Tx" SG_ 684 MC_RDISP_WORD_Rx 1;
BA_ "U_T6_MCA_MY2020_Tx" SG_ 684 MC_RDISP_WORD_Rx 1;
BA_ "U_P702_MY2021_Tx" SG_ 684 MC_RDISP_WORD_Rx 1;
BA_ "U_CD542_MY2021_Rx" SG_ 684 MC_RDISP_WORD_Rx 1;
BA_ "U_T6_MCA_MY2020_Rx" SG_ 684 MC_RDISP_WORD_Rx 1;
BA_ "GenSigStartValue" SG_ 872 DcdcIn_Pw_Mx 115;
BA_ "U_P702_MY2021_Rx" SG_ 872 PwFlowPlgBatt_D_Dsply 1;
BA_ "U_CD542_MY2021_Rx" SG_ 872 PwFlowPlgBatt_D_Dsply 1;
BA_ "U_T6_MCA_MY2020_Rx" SG_ 872 PwFlowPlgBatt_D_Dsply 1;
BA_ "U_P702_MY2021_Rx" SG_ 872 PwFlowMtrDrv_D_Dsply 1;
BA_ "U_CD542_MY2021_Rx" SG_ 872 PwFlowMtrDrv_D_Dsply 1;
BA_ "U_T6_MCA_MY2020_Rx" SG_ 872 PwFlowMtrDrv_D_Dsply 1;
BA_ "U_P702_MY2021_Rx" SG_ 872 PwFlowEngMtr_D_Dsply 1;
BA_ "U_CD542_MY2021_Rx" SG_ 872 PwFlowEngMtr_D_Dsply 1;
BA_ "U_T6_MCA_MY2020_Rx" SG_ 872 PwFlowEngMtr_D_Dsply 1;
BA_ "U_P702_MY2021_Rx" SG_ 872 PwFlowEngFuel_D_Dsply 1;
BA_ "U_CD542_MY2021_Rx" SG_ 872 PwFlowEngFuel_D_Dsply 1;
BA_ "U_T6_MCA_MY2020_Rx" SG_ 872 PwFlowEngFuel_D_Dsply 1;
BA_ "U_P702_MY2021_Rx" SG_ 872 PwFlowEngDrv_D_Dsply 1;
BA_ "U_CD542_MY2021_Rx" SG_ 872 PwFlowEngDrv_D_Dsply 1;
BA_ "U_T6_MCA_MY2020_Rx" SG_ 872 PwFlowEngDrv_D_Dsply 1;
BA_ "U_P702_MY2021_Rx" SG_ 872 PwFlowBattMtr_D_Dsply 1;
BA_ "U_CD542_MY2021_Rx" SG_ 872 PwFlowBattMtr_D_Dsply 1;
BA_ "U_T6_MCA_MY2020_Rx" SG_ 872 PwFlowBattMtr_D_Dsply 1;
BA_ "U_P702_MY2021_Rx" SG_ 872 MtrPwLvl_Pc_Dsply 1;
BA_ "U_CD542_MY2021_Rx" SG_ 872 MtrPwLvl_Pc_Dsply 1;
BA_ "U_T6_MCA_MY2020_Rx" SG_ 872 MtrPwLvl_Pc_Dsply 1;
BA_ "GenSigStartValueInteger" SG_ 872 MtrPwLvl_Pc_Dsply 511;
BA_ "U_CD542_MY2021_Rx" SG_ 872 HybMdeStat_D_Dsply 1;
BA_ "U_T6_MCA_MY2020_Rx" SG_ 872 HybMdeStat_D_Dsply 1;
BA_ "U_P702_MY2021_Rx" SG_ 872 HybMdeStat_D_Dsply 1;
BA_ "U_P702_MY2021_Rx" SG_ 872 PlgActvArb_B_Dsply 1;
BA_ "U_CD542_MY2021_Rx" SG_ 872 PlgActvArb_B_Dsply 1;
BA_ "U_T6_MCA_MY2020_Rx" SG_ 872 PlgActvArb_B_Dsply 1;
BA_ "U_P702_MY2021_Rx" SG_ 872 LvAcsyPwLvl_Pc_Dsply 1;
BA_ "U_CD542_MY2021_Rx" SG_ 872 LvAcsyPwLvl_Pc_Dsply 1;
BA_ "U_T6_MCA_MY2020_Rx" SG_ 872 LvAcsyPwLvl_Pc_Dsply 1;
BA_ "U_P702_MY2021_Rx" SG_ 872 ClimPwLvl_Pc_Dsply 1;
BA_ "U_CD542_MY2021_Rx" SG_ 872 ClimPwLvl_Pc_Dsply 1;
BA_ "U_T6_MCA_MY2020_Rx" SG_ 872 ClimPwLvl_Pc_Dsply 1;
BA_ "U_CD542_MY2021_Rx" SG_ 872 MildHybStat_D_Dsply 1;
BA_ "U_T6_MCA_MY2020_Rx" SG_ 872 MildHybStat_D_Dsply 1;
BA_ "U_CD542_MY2021_Rx" SG_ 872 EcoMode_B_Stat 1;
BA_ "U_T6_MCA_MY2020_Rx" SG_ 872 EcoMode_B_Stat 1;
BA_ "U_CD542_MY2021_Tx" SG_ 791 StopStrtVThres_D_RqMnu 1;
BA_ "U_T6_MCA_MY2020_Tx" SG_ 791 StopStrtVThres_D_RqMnu 1;
BA_ "GenSigSendType" SG_ 791 StopStrtVThres_D_RqMnu 3;
BA_ "GenSigStartValue" SG_ 791 StopStrtVThres_D_RqMnu 1;
BA_ "GenSigStartValueInteger" SG_ 791 StopStrtVThres_D_RqMnu 1;
BA_ "U_CD542_MY2021_Tx" SG_ 791 AwdDrvMde_D2_Rq 1;
BA_ "U_T6_MCA_MY2020_Tx" SG_ 791 AwdDrvMde_D2_Rq 1;
BA_ "GenSigSendType" SG_ 791 AwdDrvMde_D2_Rq 3;
BA_ "GenSigSendType" SG_ 791 VehElEffTrip2Reset_B_Rq 3;
BA_ "GenSigSendType" SG_ 791 VehElEffTrip1Reset_B_Rq 3;
BA_ "U_CD542_MY2021_Tx" SG_ 791 EngAirFilt_B_RqReset 1;
BA_ "U_T6_MCA_MY2020_Tx" SG_ 791 EngAirFilt_B_RqReset 1;
BA_ "U_P702_MY2021_Tx" SG_ 791 EngAirFilt_B_RqReset 1;
BA_ "GenSigSendType" SG_ 791 EngAirFilt_B_RqReset 3;
BA_ "U_CD542_MY2021_Tx" SG_ 791 BattElEmotive_Pc_Dsply 1;
BA_ "U_T6_MCA_MY2020_Tx" SG_ 791 BattElEmotive_Pc_Dsply 1;
BA_ "U_T6_MCA_MY2020_Rx" SG_ 791 BattElEmotive_Pc_Dsply 1;
BA_ "U_P702_MY2021_Rx" SG_ 791 BattElEmotive_Pc_Dsply 1;
BA_ "GenSigStartValue" SG_ 791 BattElEmotive_Pc_Dsply 1022;
BA_ "GenSigStartValueInteger" SG_ 791 BattElEmotive_Pc_Dsply 1022;
BA_ "U_CD542_MY2021_Tx" SG_ 791 HybMdeOvrrd_D_Rq 1;
BA_ "U_T6_MCA_MY2020_Tx" SG_ 791 HybMdeOvrrd_D_Rq 1;
BA_ "GenSigSendType" SG_ 791 HybMdeOvrrd_D_Rq 3;
BA_ "U_CD542_MY2021_Tx" SG_ 791 GpsElMdeSel_B_Rq 1;
BA_ "U_T6_MCA_MY2020_Tx" SG_ 791 GpsElMdeSel_B_Rq 1;
BA_ "U_P702_MY2021_Tx" SG_ 791 GpsElMdeSel_B_Rq 1;
BA_ "GenSigSendType" SG_ 791 GpsElMdeSel_B_Rq 3;
BA_ "U_CD542_MY2021_Tx" SG_ 791 LongTermReset_B_Rq 1;
BA_ "U_T6_MCA_MY2020_Tx" SG_ 791 LongTermReset_B_Rq 1;
BA_ "U_P702_MY2021_Tx" SG_ 791 LongTermReset_B_Rq 1;
BA_ "GenSigSendType" SG_ 791 LongTermReset_B_Rq 3;
BA_ "U_CD542_MY2021_Tx" SG_ 791 EcoCcActv_B_Rq 1;
BA_ "U_T6_MCA_MY2020_Tx" SG_ 791 EcoCcActv_B_Rq 1;
BA_ "GenSigSendType" SG_ 791 EcoCcActv_B_Rq 3;
BA_ "U_CD542_MY2021_Tx" SG_ 791 DrvEffLvl_No_Stat 1;
BA_ "U_T6_MCA_MY2020_Tx" SG_ 791 DrvEffLvl_No_Stat 1;
BA_ "U_P702_MY2021_Tx" SG_ 791 DrvEffLvl_No_Stat 1;
BA_ "U_T6_MCA_MY2020_Rx" SG_ 791 DrvEffLvl_No_Stat 1;
BA_ "U_P702_MY2021_Rx" SG_ 791 DrvEffLvl_No_Stat 1;
BA_ "U_CD542_MY2021_Tx" SG_ 791 ChargeProfIDPref_Rq 1;
BA_ "U_T6_MCA_MY2020_Tx" SG_ 791 ChargeProfIDPref_Rq 1;
BA_ "GenSigSendType" SG_ 791 ChargeProfIDPref_Rq 3;
BA_ "WakeupSignal" SG_ 791 ChargeProfIDPref_Rq 1;
BA_ "U_CD542_MY2021_Tx" SG_ 791 ConsAvgTrip_Fe_Dsply 1;
BA_ "U_T6_MCA_MY2020_Tx" SG_ 791 ConsAvgTrip_Fe_Dsply 1;
BA_ "U_P702_MY2021_Tx" SG_ 791 ConsAvgTrip_Fe_Dsply 1;
BA_ "U_U55X_MY2022_Rx" SG_ 791 ConsAvgTrip_Fe_Dsply 1;
BA_ "ECGUsedRxSignal" SG_ 791 ConsAvgTrip_Fe_Dsply 1;
BA_ "U_T6_MCA_MY2020_Rx" SG_ 791 ConsAvgTrip_Fe_Dsply 1;
BA_ "U_CD542_MY2021_Tx" SG_ 791 GrdAsstAllw_D_RqMnu 1;
BA_ "U_T6_MCA_MY2020_Tx" SG_ 791 GrdAsstAllw_D_RqMnu 1;
BA_ "U_CD542_MY2021_Tx" SG_ 791 PlgOvrrdStrt_D_Cmd 1;
BA_ "U_T6_MCA_MY2020_Tx" SG_ 791 PlgOvrrdStrt_D_Cmd 1;
BA_ "GenSigSendType" SG_ 791 PlgOvrrdStrt_D_Cmd 3;
BA_ "U_CD542_MY2021_Tx" SG_ 791 EcoMde_D_RqMnu 1;
BA_ "U_T6_MCA_MY2020_Tx" SG_ 791 EcoMde_D_RqMnu 1;
BA_ "GenSigSendType" SG_ 791 EcoMde_D_RqMnu 3;
BA_ "GenSigStartValue" SG_ 791 EcoMde_D_RqMnu 1;
BA_ "GenSigStartValueInteger" SG_ 791 EcoMde_D_RqMnu 1;
BA_ "U_CD542_MY2021_Tx" SG_ 791 EmotiveType_D_Dsply 1;
BA_ "U_T6_MCA_MY2020_Tx" SG_ 791 EmotiveType_D_Dsply 1;
BA_ "U_T6_MCA_MY2020_Rx" SG_ 791 EmotiveType_D_Dsply 1;
BA_ "GenSigSendType" SG_ 791 EmotiveType_D_Dsply 3;
BA_ "U_CD542_MY2021_Rx" SG_ 358 StopStrtStdby_D_Indic 1;
BA_ "U_T6_MCA_MY2020_Rx" SG_ 358 StopStrtStdby_D_Indic 1;
BA_ "U_P702_MY2021_Rx" SG_ 358 StopStrtStdby_D_Indic 1;
BA_ "U_CD542_MY2021_Rx" SG_ 358 StopStrtIODTxt_D_Rq 1;
BA_ "U_T6_MCA_MY2020_Rx" SG_ 358 StopStrtIODTxt_D_Rq 1;
BA_ "U_P702_MY2021_Rx" SG_ 358 StopStrtIODTxt_D_Rq 1;
BA_ "U_CD542_MY2021_Rx" SG_ 358 StopStrtDrvMde_D_Indic 1;
BA_ "U_T6_MCA_MY2020_Rx" SG_ 358 StopStrtDrvMde_D_Indic 1;
BA_ "U_P702_MY2021_Rx" SG_ 358 StopStrtDrvMde_D_Indic 1;
BA_ "U_CD542_MY2021_Rx" SG_ 358 StopStrtMsgTxt_D_Rq 1;
BA_ "U_T6_MCA_MY2020_Rx" SG_ 358 StopStrtMsgTxt_D_Rq 1;
BA_ "U_P702_MY2021_Rx" SG_ 358 StopStrtMsgTxt_D_Rq 1;
BA_ "U_CD542_MY2021_Rx" SG_ 358 OdoTripVerify_L_Actl 1;
BA_ "U_T6_MCA_MY2020_Rx" SG_ 358 OdoTripVerify_L_Actl 1;
BA_ "U_P702_MY2021_Rx" SG_ 358 OdoTripVerify_L_Actl 1;
BA_ "ContentDependant" SG_ 358 HiElPwInhbt_B_Stat 1;
BA_ "ContentDependant" SG_ 358 AutoStopPtDelta_I_Est 1;
BA_ "GenSigStartValueInteger" SG_ 358 AutoStopPtDelta_I_Est 127;
BA_ "U_CD542_MY2021_Tx" SG_ 840 FohAddHeater_D_Rq 1;
BA_ "GenSigSendType" SG_ 840 FohAddHeater_D_Rq 3;
BA_ "U_CD542_MY2021_Tx" SG_ 840 FohStrtDateYr_No_Rq 1;
BA_ "U_CD542_MY2021_Tx" SG_ 840 FohStrtDateDay_No_Rq 1;
BA_ "U_CD542_MY2021_Tx" SG_ 840 FohT2Friday_T_Rq 1;
BA_ "GenSigSendType" SG_ 840 FohT2Friday_T_Rq 3;
BA_ "ContentDependant" SG_ 840 FohT2Friday_T_Rq 1;
BA_ "U_CD542_MY2021_Tx" SG_ 840 FohT1Friday_T_Rq 1;
BA_ "GenSigSendType" SG_ 840 FohT1Friday_T_Rq 3;
BA_ "ContentDependant" SG_ 840 FohT1Friday_T_Rq 1;
BA_ "U_CD542_MY2021_Tx" SG_ 840 FohT2Wednesday_T_Rq 1;
BA_ "GenSigSendType" SG_ 840 FohT2Wednesday_T_Rq 3;
BA_ "ContentDependant" SG_ 840 FohT2Wednesday_T_Rq 1;
BA_ "U_CD542_MY2021_Tx" SG_ 840 FohT2Tuesday_T_Rq 1;
BA_ "GenSigSendType" SG_ 840 FohT2Tuesday_T_Rq 3;
BA_ "ContentDependant" SG_ 840 FohT2Tuesday_T_Rq 1;
BA_ "U_CD542_MY2021_Tx" SG_ 840 FohT2Thursday_T_Rq 1;
BA_ "GenSigSendType" SG_ 840 FohT2Thursday_T_Rq 3;
BA_ "ContentDependant" SG_ 840 FohT2Thursday_T_Rq 1;
BA_ "U_CD542_MY2021_Tx" SG_ 840 FohT2Sunday_T_Rq 1;
BA_ "GenSigSendType" SG_ 840 FohT2Sunday_T_Rq 3;
BA_ "ContentDependant" SG_ 840 FohT2Sunday_T_Rq 1;
BA_ "U_CD542_MY2021_Tx" SG_ 840 FohT2Saturday_T_Rq 1;
BA_ "GenSigSendType" SG_ 840 FohT2Saturday_T_Rq 3;
BA_ "ContentDependant" SG_ 840 FohT2Saturday_T_Rq 1;
BA_ "U_CD542_MY2021_Tx" SG_ 840 FohT2Monday_T_Rq 1;
BA_ "GenSigSendType" SG_ 840 FohT2Monday_T_Rq 3;
BA_ "ContentDependant" SG_ 840 FohT2Monday_T_Rq 1;
BA_ "U_CD542_MY2021_Tx" SG_ 840 FohT1Wednesday_T_Rq 1;
BA_ "GenSigSendType" SG_ 840 FohT1Wednesday_T_Rq 3;
BA_ "ContentDependant" SG_ 840 FohT1Wednesday_T_Rq 1;
BA_ "U_CD542_MY2021_Tx" SG_ 840 FohT1Tuesday_T_Rq 1;
BA_ "GenSigSendType" SG_ 840 FohT1Tuesday_T_Rq 3;
BA_ "ContentDependant" SG_ 840 FohT1Tuesday_T_Rq 1;
BA_ "U_CD542_MY2021_Tx" SG_ 840 FohT1Thursday_T_Rq 1;
BA_ "GenSigSendType" SG_ 840 FohT1Thursday_T_Rq 3;
BA_ "ContentDependant" SG_ 840 FohT1Thursday_T_Rq 1;
BA_ "U_CD542_MY2021_Tx" SG_ 840 FohT1Sunday_T_Rq 1;
BA_ "GenSigSendType" SG_ 840 FohT1Sunday_T_Rq 3;
BA_ "ContentDependant" SG_ 840 FohT1Sunday_T_Rq 1;
BA_ "U_CD542_MY2021_Tx" SG_ 840 FohT1Saturday_T_Rq 1;
BA_ "GenSigSendType" SG_ 840 FohT1Saturday_T_Rq 3;
BA_ "ContentDependant" SG_ 840 FohT1Saturday_T_Rq 1;
BA_ "U_CD542_MY2021_Tx" SG_ 840 FohT1Monday_T_Rq 1;
BA_ "GenSigSendType" SG_ 840 FohT1Monday_T_Rq 3;
BA_ "ContentDependant" SG_ 840 FohT1Monday_T_Rq 1;
BA_ "WakeupSignal" SG_ 945 KeyPadCodeDgt6_D_Dsply 1;
BA_ "WakeupSignal" SG_ 945 KeyPadCodeDgt5_D_Dsply 1;
BA_ "WakeupSignal" SG_ 945 KeyPadCodeDgt4_D_Dsply 1;
BA_ "WakeupSignal" SG_ 945 KeyPadCodeDgt3_D_Dsply 1;
BA_ "WakeupSignal" SG_ 945 KeyPadCodeDgt2_D_Dsply 1;
BA_ "WakeupSignal" SG_ 945 KeyPadCodeDgt1_D_Dsply 1;
BA_ "U_P702_MY2021_Rx" SG_ 945 KeyOffMde_D_Actl 1;
BA_ "U_CD542_MY2021_Rx" SG_ 945 KeyOffMde_D_Actl 1;
BA_ "U_T6_MCA_MY2020_Rx" SG_ 945 KeyOffMde_D_Actl 1;
BA_ "U_T6_MCA_MY2020_Rx" SG_ 945 PrkLckCtlLatch_B_Rq 1;
BA_ "GenSigSendType" SG_ 740 EmgcyAsstActv_D_Stat 3;
BA_ "U_CD542_MY2021_Rx" SG_ 1055 EcoCochInstNeg_B_Dsply 1;
BA_ "U_T6_MCA_MY2020_Rx" SG_ 1055 EcoCochInstNeg_B_Dsply 1;
BA_ "U_P702_MY2021_Rx" SG_ 1055 EcoCochInstNeg_B_Dsply 1;
BA_ "U_CD542_MY2021_Rx" SG_ 1055 EcoCochShif_Pc_Dsply 1;
BA_ "U_T6_MCA_MY2020_Rx" SG_ 1055 EcoCochShif_Pc_Dsply 1;
BA_ "U_P702_MY2021_Rx" SG_ 1055 EcoCochShif_Pc_Dsply 1;
BA_ "GenSigStartValue" SG_ 1055 EcoCochShif_Pc_Dsply 255;
BA_ "GenSigStartValueInteger" SG_ 1055 EcoCochShif_Pc_Dsply 255;
BA_ "U_CD542_MY2021_Rx" SG_ 1055 EcoCochInst_Pc_Dsply 1;
BA_ "U_T6_MCA_MY2020_Rx" SG_ 1055 EcoCochInst_Pc_Dsply 1;
BA_ "U_P702_MY2021_Rx" SG_ 1055 EcoCochInst_Pc_Dsply 1;
BA_ "GenSigStartValue" SG_ 1055 EcoCochInst_Pc_Dsply 100;
BA_ "GenSigStartValueInteger" SG_ 1055 EcoCochInst_Pc_Dsply 1000;
BA_ "U_CD542_MY2021_Rx" SG_ 1055 EcoCochIdlFuel_Pc_Dsply 1;
BA_ "U_T6_MCA_MY2020_Rx" SG_ 1055 EcoCochIdlFuel_Pc_Dsply 1;
BA_ "U_P702_MY2021_Rx" SG_ 1055 EcoCochIdlFuel_Pc_Dsply 1;
BA_ "GenSigStartValue" SG_ 1055 EcoCochIdlFuel_Pc_Dsply 255;
BA_ "GenSigStartValueInteger" SG_ 1055 EcoCochIdlFuel_Pc_Dsply 255;
BA_ "U_CD542_MY2021_Rx" SG_ 1055 EcoCochDecel_Pc_Dsply 1;
BA_ "U_T6_MCA_MY2020_Rx" SG_ 1055 EcoCochDecel_Pc_Dsply 1;
BA_ "U_P702_MY2021_Rx" SG_ 1055 EcoCochDecel_Pc_Dsply 1;
BA_ "GenSigStartValue" SG_ 1055 EcoCochDecel_Pc_Dsply 255;
BA_ "GenSigStartValueInteger" SG_ 1055 EcoCochDecel_Pc_Dsply 255;
BA_ "U_CD542_MY2021_Rx" SG_ 1055 EcoCochCrus_Pc_Dsply 1;
BA_ "U_T6_MCA_MY2020_Rx" SG_ 1055 EcoCochCrus_Pc_Dsply 1;
BA_ "U_P702_MY2021_Rx" SG_ 1055 EcoCochCrus_Pc_Dsply 1;
BA_ "GenSigStartValue" SG_ 1055 EcoCochCrus_Pc_Dsply 255;
BA_ "GenSigStartValueInteger" SG_ 1055 EcoCochCrus_Pc_Dsply 255;
BA_ "U_CD542_MY2021_Rx" SG_ 1055 EcoCochA_Pc_Dsply 1;
BA_ "U_T6_MCA_MY2020_Rx" SG_ 1055 EcoCochA_Pc_Dsply 1;
BA_ "U_P702_MY2021_Rx" SG_ 1055 EcoCochA_Pc_Dsply 1;
BA_ "GenSigStartValue" SG_ 1055 EcoCochA_Pc_Dsply 255;
BA_ "GenSigStartValueInteger" SG_ 1055 EcoCochA_Pc_Dsply 255;
BA_ "U_CD542_MY2021_Rx" SG_ 361 TrcmSrvcRqd_B_Rq 1;
BA_ "U_T6_MCA_MY2020_Rx" SG_ 361 TrcmSrvcRqd_B_Rq 1;
BA_ "U_P702_MY2021_Rx" SG_ 361 TrcmSrvcRqd_B_Rq 1;
BA_ "ContentDependant" SG_ 361 TrcmSrvcRqd_B_Rq 1;
BA_ "ContentDependant" SG_ 361 TrnGear_I_MeasMax 1;
BA_ "ContentDependant" SG_ 361 TrnActFalt_B_Actl 1;
BA_ "ContentDependant" SG_ 361 TrnCapHlth_Actl 1;
BA_ "ContentDependant" SG_ 361 TrnPwmFalt_B_Actl 1;
VAL_ 611 AwdTerrMdeChng_D_Rdy 7 "Fault" 6 "Undefined_2" 5 "Undefined_1" 4 "ModeUnavailDrInputRqd" 3 "SpOpModes_NotSupported" 2 "ModeUnavailDynamicCond" 1 "Module_In_Initialization" 0 "Mode_Change_Available" ;
VAL_ 611 AwdTerrMde_D_Actl 7 "Fail_Safe_Default" 6 "Dynamic_Mode" 5 "Rock_Crawl_Mode" 4 "Mud_Ruts_Mode" 3 "Sand_Mode" 2 "Undefined" 1 "Low_Mu_Mode" 0 "Special_Operating_Mode_Off" ;
VAL_ 611 AwdSys_D_Stat 3 "Faulty" 2 "NotUsed" 1 "_4x4_L_H_Active" 0 "_4x4_L_H_Inactive" ;
VAL_ 611 AwdStat_D_RqDsply 31 "Rear_Diff_Lock_Not_Avail" 30 "_4wd_Lock_Required" 29 "Cfg_Perf_Redc_See_Manual" 28 "To_Engage_4x4_Release_Aped" 27 "To_Engage_4x4_Slow_To_3MPH" 26 "Shift_To_Neutral" 25 "Lkr_Mode_Unavail_TMS" 24 " _4x4_Mode_Unavail_TMS" 23 "Out_of_4Low_Crawl" 22 "AWD_PTU_Oil_Changed" 21 "Change_AWD_PTU_Oil" 20 "Neutral_Tow_Disabled" 19 "Neutral_Tow_Enabled" 18 "AWD_OFF" 17 "_4x4_Off_Road_Speed" 16 "_4x4_Extreme_Off_Road_Mode" 15 "_4x4_Exiting_Off_Road" 14 "_4x4_Off_Road_Mode" 10 "_4x4_Locked_Temporarily" 9 "Shift_In_Progress" 13 "Blocked_Shift_Assist" 12 "_4x4_Auto_Restored" 11 "_4x4_Disabled_Temporarily" 7 "Out_of_4Low__Neutral" 6 "Out_of_4Low__Brake" 5 "Out_of_4Low__Speed" 4 "Into_4Low__Clutch" 3 "Into_4Low__Neutral" 2 "Into_4Low__Brake" 1 "Into_4Low__Speed" 0 "Normal__No_Message" 8 "Out_of_4Low__Clutch" ;
VAL_ 611 AwdLck_D_Stat 9 "Undefined" 8 "Under_External_Torque_Ctrl" 7 "Torque_Limited_by_Cmd" 6 "Fully_Locked_by_Cmd" 5 "Disabled" 4 "Warning" 3 "Fault" 2 "Inactive" 1 "Completely_Opened_by_Cmd" 0 "OK" ;
VAL_ 611 AwdSrvcRqd_B_Rq 1 "On" 0 "Off" ;
VAL_ 611 AwdLck_Tq_Rq 4095 "Fault" 4094 "Unknown" ;
VAL_ 611 AwdOffRoadMode_D_Stats 3 "Invalid" 2 "Extreme_Off_Road" 1 "Off_Road" 0 "Normal_Mode" ;
VAL_ 611 AwdLoLamp_D_RqDsply 3 "Not_Used" 2 "Flash" 1 "On" 0 "Off" ;
VAL_ 611 AwdHiLamp_D_RqDsply 3 "Not_Used" 2 "Flash" 1 "On" 0 "Off" ;
VAL_ 611 AwdAutoLamp_D_RqDsply 3 "Not_Used" 2 "Flash" 1 "On" 0 "Off" ;
VAL_ 611 Awd2wdLamp_D_RqDsply 3 "Not_Used" 2 "Flash" 1 "On" 0 "Off" ;
VAL_ 611 AwdRnge_D_Actl 7 "Unknown" 6 "High_Range_2wd" 5 "High_Range_Auto" 4 "High_Range_Locked" 3 "Neutral" 2 "Low_Range_2wd" 1 "Low_Range_Auto" 0 "Low_Range_Locked" ;
VAL_ 611 NtrlTowAvail_B_Stat 1 "Available" 0 "NotAvailable" ;
VAL_ 611 AwdDrvMde_D_Stat 7 "Faulty" 6 "NotAvailable" 5 "RockCrawl" 4 "Baja" 3 "MudAndSand" 2 "Weather" 1 "Sport" 0 "Normal" ;
VAL_ 611 SelDrvMdeAwd_D_Stat 0 "NotAvailable" 1 "Available" 2 "TemporarilyNotAvailable" 3 "Faulty" ;
VAL_ 264 CabnAmb_Te_Actl_UB 1 "Fresh_data" 0 "Unchanged_data" ;
VAL_ 264 CabnAmb_Te_Actl 255 "Fault" ;
VAL_ 264 ChrgCordLck_D_Stat_UB 1 "Fresh_data" 0 "Unchanged_data" ;
VAL_ 264 ChrgCordLck_D_Stat 7 "Faulty" 6 "LockFail" 5 "UnlockFail" 4 "LockInProgress" 3 "UnlockInProgress" 2 "Lock" 1 "Unlock" 0 "Retain" ;
VAL_ 264 PwPckTqRdy_B_Dsply 1 "On" 0 "Off" ;
VAL_ 264 HtrnOvrTeLamp_B_Dsply_UB 1 "Fresh_data" 0 "Unchanged_data" ;
VAL_ 264 HtrnOvrTeLamp_B_Dsply 1 "On" 0 "Off" ;
VAL_ 264 PwPckTqRdy_B_Dsply_UB 1 "Fresh_data" 0 "Unchanged_data" ;
VAL_ 264 BpedDrvAppl_D_Actl 3 "_Not_Allowed" 2 "Driver_Braking" 1 "Driver_Not_Braking" 0 "Not_Allowed" ;
VAL_ 264 BpedDrvAppl_D_Actl_UB 1 "Fresh_data" 0 "Unchanged_data" ;
VAL_ 264 BattTracSoc_Pc_Dsply_UB 1 "Fresh_data" 0 "Unchanged_data" ;
VAL_ 264 BattTracSoc_Pc_Dsply 255 "Faulty" 254 "NoDataExists" ;
VAL_ 1114 TrailCtlSwtch_B_Stat2 1 "Pressed" 0 "Not_Pressed" ;
VAL_ 1114 TrlBrkInitOut_D_Rq 3 "Heavy" 2 "Medium" 1 "Light" 0 "Null" ;
VAL_ 968 RvltnMatchAllw_D_Rq 3 "RevolutionMatchDisabled" 2 "RevolutionMatchEnabled" 1 "ChangeWithDriveMode" 0 "NoSelection" ;
VAL_ 968 BrkDrvMde_D_Rq 7 "Faulty" 6 "RockCrawl" 5 "Baja" 4 "DragOrMudAndSand" 3 "Track" 2 "Snow_Wet" 1 "Sport" 0 "Normal" ;
VAL_ 968 LnchCtl_D_Rq 3 "NotUsed2" 2 "NotUsed1" 1 "LC_On" 0 "LC_Off" ;
VAL_ 968 CurrentColor_CmdGage 15 "NotUsed7" 14 "NotUsed6" 13 "NotUsed5" 12 "NotUsed4" 11 "NotUsed3" 10 "NotUsed2" 9 "NotUsed1" 8 "Null" 7 "Color7" 6 "Color6" 5 "Color5" 4 "Color4" 3 "Color3" 2 "Color2" 1 "Color1" 0 "Off" ;
VAL_ 968 BlendedColor_CmdGage 3 "NotUsed" 2 "Null" 1 "On" 0 "Off" ;
VAL_ 968 BlendColorRed_CmdGage 15 "NotUsed10" 14 "NotUsed9" 13 "NotUsed8" 12 "NotUsed7" 11 "NotUsed6" 10 "NotUsed5" 9 "NotUsed4" 8 "NotUsed3" 7 "NotUsed2" 6 "NotUsed1" 5 "_5" 4 "_4" 3 "_3" 2 "_2" 1 "_1" 0 "Null" ;
VAL_ 968 BlendColorGrn_CmdGage 15 "NotUsed10" 14 "NotUsed9" 13 "NotUsed8" 12 "NotUsed7" 11 "NotUsed6" 10 "NotUsed5" 9 "NotUsed4" 8 "NotUsed3" 7 "NotUsed2" 6 "NotUsed1" 5 "_5" 4 "_4" 3 "_3" 2 "_2" 1 "_1" 0 "Null" ;
VAL_ 968 BlendColorBlue_CmdGage 15 "NotUsed10" 14 "NotUsed9" 13 "NotUsed8" 12 "NotUsed7" 11 "NotUsed6" 10 "NotUsed5" 9 "NotUsed4" 8 "NotUsed3" 7 "NotUsed2" 6 "NotUsed1" 5 "_5" 4 "_4" 3 "_3" 2 "_2" 1 "_1" 0 "Null" ;
VAL_ 968 Dimming_Level_Cmd 3 "Low" 2 "Not_Used" 1 "High" 0 "Null" ;
VAL_ 968 Current_Color_Cmd 15 "NotUsed7" 14 "NotUsed6" 13 "NotUsed5" 12 "NotUsed4" 11 "NotUsed3" 10 "NotUsed2" 9 "NotUsed1" 8 "Null" 7 "Color7" 6 "Color6" 5 "Color5" 4 "Color4" 3 "Color3" 2 "Color2" 1 "Color1" 0 "Off" ;
VAL_ 968 BlendedColorRed_Cmd 15 "NotUsed10" 14 "NotUsed9" 13 "NotUsed8" 12 "NotUsed7" 11 "NotUsed6" 10 "NotUsed5" 9 "NotUsed4" 8 "NotUsed3" 7 "NotUsed2" 6 "NotUsed1" 5 "_5" 4 "_4" 3 "_3" 2 "_2" 1 "_1" 0 "Null" ;
VAL_ 968 BlendedColorGreen_Cmd 15 "NotUsed10" 14 "NotUsed9" 13 "NotUsed8" 12 "NotUsed7" 11 "NotUsed6" 10 "NotUsed5" 9 "NotUsed4" 8 "NotUsed3" 7 "NotUsed2" 6 "NotUsed1" 5 "_5" 4 "_4" 3 "_3" 2 "_2" 1 "_1" 0 "Null" ;
VAL_ 968 BlendedColorBlue_Cmd 15 "NotUsed10" 14 "NotUsed9" 13 "NotUsed8" 12 "NotUsed7" 11 "NotUsed6" 10 "NotUsed5" 9 "NotUsed4" 8 "NotUsed3" 7 "NotUsed2" 6 "NotUsed1" 5 "_5" 4 "_4" 3 "_3" 2 "_2" 1 "_1" 0 "Null" ;
VAL_ 968 BlendedColor_Cmd 3 "NotUsed" 2 "Null" 1 "On" 0 "Off" ;
VAL_ 968 SuspDrvMde_D_Rq 7 "Faulty" 6 "NotUsed2" 5 "NotUsed1" 4 "Drag" 3 "Track" 2 "Snow_Wet" 1 "Sport" 0 "Normal" ;
VAL_ 968 SlMde_D_Rq 3 "IsaNotConfigured" 2 "Manual_Mode" 1 "Auto_Mode" 0 "Null" ;
VAL_ 968 IsaOffst_D_Rq 15 "Faulty" 14 "Null" 13 "Thirteen" 12 "Twelve" 11 "Eleven" 10 "Ten" 9 "Nine" 8 "Eight" 7 "Seven" 6 "Six" 5 "Five" 4 "Four" 3 "Three" 2 "Two" 1 "One" 0 "Zero" ;
VAL_ 969 Dimming_Level_Stat 3 "Low" 2 "Not_Used" 1 "High" 0 "Null" ;
VAL_ 969 Current_Color_Stat 15 "NotUsed7" 14 "NotUsed6" 13 "NotUsed5" 12 "NotUsed4" 11 "NotUsed3" 10 "NotUsed2" 9 "NotUsed1" 8 "Null" 7 "Color7" 6 "Color6" 5 "Color5" 4 "Color4" 3 "Color3" 2 "Color2" 1 "Color1" 0 "Off" ;
VAL_ 969 BlendedColorRed_Stat 15 "NotUsed10" 14 "NotUsed9" 13 "NotUsed8" 12 "NotUsed7" 11 "NotUsed6" 10 "NotUsed5" 9 "NotUsed4" 8 "NotUsed3" 7 "NotUsed2" 6 "NotUsed1" 5 "_5" 4 "_4" 3 "_3" 2 "_2" 1 "_1" 0 "Null" ;
VAL_ 969 BlendedColorGreen_Stat 15 "NotUsed10" 14 "NotUsed9" 13 "NotUsed8" 12 "NotUsed7" 11 "NotUsed6" 10 "NotUsed5" 9 "NotUsed4" 8 "NotUsed3" 7 "NotUsed2" 6 "NotUsed1" 5 "_5" 4 "_4" 3 "_3" 2 "_2" 1 "_1" 0 "Null" ;
VAL_ 969 BlendedColorBlue_Stat 15 "NotUsed10" 14 "NotUsed9" 13 "NotUsed8" 12 "NotUsed7" 11 "NotUsed6" 10 "NotUsed5" 9 "NotUsed4" 8 "NotUsed3" 7 "NotUsed2" 6 "NotUsed1" 5 "_5" 4 "_4" 3 "_3" 2 "_2" 1 "_1" 0 "Null" ;
VAL_ 969 BlendedColor_Stat 3 "NotUsed" 2 "Null" 1 "On" 0 "Off" ;
VAL_ 969 TurnLampRrOut_B_Stat 1 "Out" 0 "Null" ;
VAL_ 969 TurnLampRlOut_B_Stat 1 "Out" 0 "Null" ;
VAL_ 1006 PersIndexIpmb_D_Actl 7 "Unused_3" 6 "Unused_2" 5 "Unused_1" 4 "Vehicle" 3 "PERS_4" 2 "PERS_3" 1 "PERS_2" 0 "PERS_1" ;
VAL_ 130 SteWhlSwtchHome_B_Stat 1 "Pressed" 0 "Not_Pressed" ;
VAL_ 130 SteWhlSwtchInfo_B_Stat 1 "Pressed" 0 "Not_Pressed" ;
VAL_ 130 SelDrvMdeSwtch_D_Stat4 3 "Faulty" 2 "SwitchState2" 1 "SwitchState1" 0 "NotPressed" ;
VAL_ 130 SelDrvMdeSwtch3_D_Stat4 3 "Faulty" 2 "Pressed" 1 "NotPressed" 0 "Null" ;
VAL_ 130 SelDrvMdeSwtch2_D_Stat4 3 "Faulty" 2 "Pressed" 1 "NotPressed" 0 "Null" ;
VAL_ 130 SelDrvMdeSwtch1_D_Stat4 3 "Faulty" 2 "Pressed" 1 "NotPressed" 0 "Null" ;
VAL_ 130 PoliceAux4Swtch_B_Stat 1 "Switch_Active" 0 "Switch_Not_Active" ;
VAL_ 130 PoliceAux3Swtch_B_Stat 1 "Switch_Active" 0 "Switch_Not_Active" ;
VAL_ 130 PoliceAux2Swtch_B_Stat 1 "Switch_Active" 0 "Switch_Not_Active" ;
VAL_ 130 PoliceAux1Swtch_B_Stat 1 "Switch_Active" 0 "Switch_Not_Active" ;
VAL_ 130 SteWhlSwtchView_B_Stat 1 "Pressed" 0 "Not_Pressed" ;
VAL_ 130 SteWhlSwtchSet_B_Stat 1 "Pressed" 0 "Not_Pressed" ;
VAL_ 130 SteWhlSwtchPhon_B_Stat 1 "Pressed" 0 "Not_Pressed" ;
VAL_ 130 SteWhlSwtchNav_B_Stat 1 "Pressed" 0 "Not_Pressed" ;
VAL_ 130 SteWhlSwtchMed_B_Stat 1 "Pressed" 0 "Not_Pressed" ;
VAL_ 130 SteWhlSwtchIod_B_Stat 1 "Pressed" 0 "Not_Pressed" ;
VAL_ 130 SteWhlSwtchHud_B_Stat 1 "Pressed" 0 "Not_Pressed" ;
VAL_ 130 SteWhlSwtchBack_B_Stat 1 "Pressed" 0 "Not_Pressed" ;
VAL_ 130 SteWhlSwtchMenu_B_Stat 1 "Pressed" 0 "Not_Pressed" ;
VAL_ 130 SteEffortInc_B_RqDrv 1 "Pressed" 0 "Not_Pressed" ;
VAL_ 130 SelDrvMdeInc_B_RqDrv 1 "Pressed" 0 "Not_Pressed" ;
VAL_ 130 SelDrvMdeDec_B_RqDrv 1 "Pressed" 0 "Not_Pressed" ;
VAL_ 130 SuspDampInc_B_RqDrv 1 "Pressed" 0 "Not_Pressed" ;
VAL_ 130 SteWhlSwtchUp_B_Stat 1 "Pressed" 0 "Not_Pressed" ;
VAL_ 130 SteWhlSwtchRght_B_Stat 1 "Pressed" 0 "Not_Pressed" ;
VAL_ 130 SteWhlSwtchOk_B_Stat 1 "Pressed" 0 "Not_Pressed" ;
VAL_ 130 SteWhlSwtchLeft_B_Stat 1 "Pressed" 0 "Not_Pressed" ;
VAL_ 130 SteWhlSwtchDown_B_Stat 1 "Pressed" 0 "Not_Pressed" ;
VAL_ 1244 Con_InfotainmentVer_St 1 "B299" 0 "invalid" ;
VAL_ 1243 Con_BTAud_InfotainmVer_St 1 "B299" 0 "invalid" ;
VAL_ 681 Con_DB1FilterConfig_St 31 "UnknownActive" 9 "Reserved" 8 "Podcast" 7 "Audiobook" 6 "Composer" 5 "Track" 4 "Genre" 3 "Album" 2 "Artist" 1 "Playlist" 0 "Root" ;
VAL_ 681 Con_DB1Filter3_St 1023 "All" 1022 "SIIndex_1022" 1 "SIIndex_1" 0 "NotEngaged" ;
VAL_ 681 Con_DB1Filter2_St 65535 "All" 65534 "SIIndex_65534" 1 "SIIndex_1" 0 "NotEngaged" ;
VAL_ 681 Con_DB1Filter1_St 65535 "All" 65534 "SIIndex_65534" 1 "SIIndex_1" 0 "NotEngaged" ;
VAL_ 741 Con_USB_Playtype_St 2 "Playlist" 1 "Folder" 0 "Invalid" ;
VAL_ 741 Con_ShowSWDLprogress_St 5 "ConSWUpdateSuccess" 4 "ConSWUpdateNotNecessary" 3 "ConSWUpdateFailed" 2 "ConSWUpdateInProgress" 1 "ConSWUpdateNotRunning" 0 "Invalid" ;
VAL_ 741 Con_iPod_IntroScan_St 3 "OnTheFolderSelGroup" 2 "OnTheDevice" 1 "Off" 0 "Invalid" ;
VAL_ 741 Con_iPod_Shuffle_St 3 "OnTheFolderSelGroup" 2 "OnTheDevice" 1 "Off" 0 "Invalid" ;
VAL_ 741 Con_iPod_Repeat_St 7 "Reserved2" 6 "Reserved1" 5 "Reserved" 4 "RepeatOnDevice" 3 "RepeatOnFolder" 2 "RepeatOnTrack" 1 "Off" 0 "Invalid" ;
VAL_ 741 Con_USB_Repeat_St 7 "Reserved2" 6 "Reserved1" 5 "Reserved" 4 "RepeatOnDevice" 3 "RepeatOnFolder" 2 "RepeatOnTrack" 1 "Off" 0 "Invalid" ;
VAL_ 741 Con_USB_IntroScan_St 3 "OnTheFolderSelGroup" 2 "OnTheDevice" 1 "Off" 0 "Invalid" ;
VAL_ 741 Con_USB_Shuffle_St 3 "OnTheFolderSelGroup" 2 "OnTheDevice" 1 "Off" 0 "Invalid" ;
VAL_ 741 Con_iPod_Error_St 8 "NoDataInFolder" 7 "NoRespFromDevice" 6 "UnableToRead" 5 "NoDataOnDevice" 4 "FileSysNotSupported" 3 "DeviceNotSupported" 2 "InvalidFile" 1 "NoError" 0 "Invalid" ;
VAL_ 741 Con_USB_Error_St 9 "USBHubNotSupported" 8 "NoDataInFolder" 7 "NoRespFromDevice" 6 "UnableToRead" 5 "NoDataOnDevice" 4 "FileSysNotSupported" 3 "DeviceNotSupported" 2 "InvalidFile" 1 "NoError" 0 "Invalid" ;
VAL_ 741 Con_iPod_FunctStatus_St 7 "Reserved2" 6 "Reserved1" 5 "Reserved" 4 "Reading" 3 "Ready" 2 "Initilization" 1 "Free" 0 "Invalid" ;
VAL_ 741 Con_USB_FunctStatus_St 7 "Reserved2" 6 "Reserved1" 5 "Reserved" 4 "Reading" 3 "Ready" 2 "Initilization" 1 "Free" 0 "Invalid" ;
VAL_ 741 Con_USB_OpMode_St 7 "FastRewind20" 6 "FastRewind10" 5 "FastForward20" 4 "FastForward10" 3 "Pause" 2 "Play" 1 "Stop" 0 "Invalid" ;
VAL_ 741 Con_iPod_OpMode_St 7 "FastRewind20" 6 "FastRewind10" 5 "FastForward20" 4 "FastForward10" 3 "Pause" 2 "Play" 1 "Stop" 0 "Invalid" ;
VAL_ 954 PosLghtFl_D_Stat 3 "Faulty" 2 "Outage" 1 "On" 0 "Off" ;
VAL_ 954 PosLghtFr_D_Stat 3 "Faulty" 2 "Outage" 1 "On" 0 "Off" ;
VAL_ 954 LoadShedRelayMde_D_Stat 3 "NotUsed" 2 "EngRunRelay" 1 "SnowPlow" 0 "LoadShed" ;
VAL_ 954 CargoLght_D_Stat 3 "NotUsed" 2 "Automatic" 1 "Manual" 0 "Null" ;
VAL_ 954 TlghtTestLght_D_Stat 7 "Error" 6 "AllOff" 5 "TestingReverseLights" 4 "TestingBrakeLights" 3 "TestingLeftTurnSignal" 2 "TestingRightTurnSignal" 1 "ParkingLightsIlluminated" 0 "Null" ;
VAL_ 954 LghtAmbDrvMde_B_Stat 1 "Automatic" 0 "Manual" ;
VAL_ 954 KeylessIdl_B_Stat 1 "Pressed" 0 "Not_Pressed" ;
VAL_ 954 PwRnngBoardPoll_D_Stat 3 "NotUsed" 2 "PkPresent" 1 "PkNotPresent" 0 "NotPolling" ;
VAL_ 954 PoliceDmngLvl_D_Stat 7 "NotUsed" 6 "Off_Night" 5 "Off_Day" 4 "Low1Night" 3 "Low1Day" 2 "Inactive" 1 "Decommissioned" 0 "Null" ;
VAL_ 954 TrlrHitchLamp_D_Stat 1 "On" 0 "Off" ;
VAL_ 954 LicPlateLght_B_Stat 1 "On" 0 "Off" ;
VAL_ 954 TrukBedLght_B_Stat 1 "On" 0 "Off" ;
VAL_ 954 VehWlcmFrwlMde_D_Stat 7 "IlluminatedExit" 6 "CourtesyLightingDelayExt" 5 "CourtesyLightingExtended" 4 "CourtesyLightingDelayAll" 3 "CourtesyLightingAll" 2 "IlluminatedEntry" 1 "Approach" 0 "Null" ;
VAL_ 954 PudSptLghtRight_D_Rq 3 "NotUsed" 2 "On" 1 "Off" 0 "Null" ;
VAL_ 954 PudSptLghtLeft_D_Rq 3 "NotUsed" 2 "On" 1 "Off" 0 "Null" ;
VAL_ 954 ExtLghtRight_D_Stat 3 "NotUsed" 2 "On" 1 "Off" 0 "Null" ;
VAL_ 954 VehWlcmFrwl_D_Stat 3 "RunStart" 2 "Farewell" 1 "Welcome" 0 "Null" ;
VAL_ 954 ExtLghtRear_D_Stat 3 "NotUsed" 2 "On" 1 "Off" 0 "Null" ;
VAL_ 954 ExtLghtLeft_D_Stat 3 "NotUsed" 2 "On" 1 "Off" 0 "Null" ;
VAL_ 954 ExtLghtAlrt_B_Rq 1 "Yes" 0 "No" ;
VAL_ 954 ExtLght_D_Falt 3 "Error" 2 "NoStationary" 1 "StartEngine" 0 "Null" ;
VAL_ 954 ExtLghtFront_D_Stat 3 "NotUsed" 2 "On" 1 "Off" 0 "Null" ;
VAL_ 954 TlghtTestPrecnd_D_Stat 7 "Error" 6 "NotStationary" 5 "InteractionPresent" 4 "PreconditionsPassed" 3 "BattSocLessThan75Percent" 2 "TailLightsOn" 1 "IgnitionNotOn" 0 "Null" ;
VAL_ 954 TlghtTest_D_Stat 3 "InProgress" 2 "Ended" 1 "Completed" 0 "Null" ;
VAL_ 125 VehRolComp_W_Actl 4094 "NoDataExists" 4095 "Fault" ;
VAL_ 125 VehVertComp_A_Actl 1022 "NoDataExists" 1023 "Fault" ;
VAL_ 125 BrkTot_Tq_RqArb 8191 "Fault" 8190 "Unknown" ;
VAL_ 125 BrkTot_Tq_Actl 8191 "Fault" 8190 "Unknown" ;
VAL_ 125 HsaStat_D_Actl 7 "Faulty" 6 "FaultyWithDriverIndication" 5 "SlowRelease" 4 "FastRelease" 3 "ActiveBrakePedalReleased" 2 "ActiveBrakePedalPressed" 1 "FindingGradient" 0 "Inactive" ;
VAL_ 1082 StabBarFaltMsgTxt_D_Rq_UB 1 "Fresh_data" 0 "Unchanged_data" ;
VAL_ 1082 StabBarCnnctLamp_D_Rq_UB 1 "Fresh_data" 0 "Unchanged_data" ;
VAL_ 1082 StabBarCnncMsgTxt_D_Rq_UB 1 "Fresh_data" 0 "Unchanged_data" ;
VAL_ 1082 StabBarFaltMsgTxt_D_Rq 3 "Message3" 2 "Message2" 1 "Message1" 0 "NoMessage" ;
VAL_ 1082 StabBarCnnctLamp_D_Rq 3 "Fast_Flash" 2 "Slow_Flash" 1 "On" 0 "Off" ;
VAL_ 1082 StabBarCnncMsgTxt_D_Rq 15 "Message15" 14 "Message14" 13 "Message13" 12 "Message12" 11 "Message11" 10 "Message10" 9 "Message9" 8 "Message8" 7 "Message7" 6 "Message6" 5 "Message5" 4 "Message4" 3 "Message3" 2 "Message2" 1 "Message1" 0 "NoMessage" ;
VAL_ 1115 HUD_TextMessage_Rq 3 "Cancel" 2 "Ignore" 1 "Listen" 0 "Invalid" ;
VAL_ 1115 HUD_BTIncomingCall_Rq 2 "DeclineIncomingCall" 1 "AcceptIncomingCall" 0 "Inactive" ;
VAL_ 1115 HUD_BTInCallOptions_Rq 6 "EndHoldCall" 5 "HoldCall" 4 "GotoHandsfreeMode" 3 "GotoPrivacyMode" 2 "JoinCalls" 1 "SwitchCalls" 0 "Inactive" ;
VAL_ 1115 HUD_BTEndTelService_Rq 1 "EndOngoingTelephonyCall" 0 "Inactive" ;
VAL_ 811 ExtLghtDsply_D_Stat 7 "NotUsed" 6 "PressToOn3" 5 "PressToOff3" 4 "PressToOn2" 3 "PressToOff2" 2 "PressToOn1" 1 "PressToOff1" 0 "Reset" ;
VAL_ 811 SpeedoMajorUnit_D_Confg 3 "NotUsed" 2 "Kph" 1 "Mph" 0 "Null" ;
VAL_ 811 ScMnSoc_Pc_RqMnu 127 "Faulty" 126 "NoDataExists" ;
VAL_ 811 ScEnbl_D_RqMnu 3 "NotUsed" 2 "On" 1 "Off" 0 "Null" ;
VAL_ 811 OnePdlDrvButtn_B_Falt 1 "Faulted" 0 "NotFaulted" ;
VAL_ 811 OnePdlDrvButtn_B_Stat 1 "Pressed" 0 "Not_Pressed" ;
VAL_ 811 LongTermReset_B_RqMnu 1 "On" 0 "Off" ;
VAL_ 811 DistToStopover_L_Actl 65535 "Faulty" ;
VAL_ 811 StopoverType_D_Stat 7 "Faulty" 6 "NotUsed_1" 5 "Other" 4 "Work" 3 "Home" 2 "ChargeStation" 1 "FinalDestination" 0 "Null" ;
VAL_ 811 ExtLghtRight_D_RqMnu 7 "NotUsed" 6 "PressToOn3" 5 "PressToOff3" 4 "PressToOn2" 3 "PressToOff2" 2 "PressToOn1" 1 "PressToOff1" 0 "Reset" ;
VAL_ 811 AutoLghtOvrrd_B_RqDrv 1 "Allowed" 0 "NotAllowed" ;
VAL_ 811 ExtLghtRear_D_RqMnu 7 "NotUsed" 6 "PressToOn3" 5 "PressToOff3" 4 "PressToOn2" 3 "PressToOff2" 2 "PressToOn1" 1 "PressToOff1" 0 "Reset" ;
VAL_ 811 ExtLghtLeft_D_RqMnu 7 "NotUsed" 6 "PressToOn3" 5 "PressToOff3" 4 "PressToOn2" 3 "PressToOff2" 2 "PressToOn1" 1 "PressToOff1" 0 "Reset" ;
VAL_ 811 ExtLghtFront_D_RqMnu 7 "NotUsed" 6 "PressToOn3" 5 "PressToOff3" 4 "PressToOn2" 3 "PressToOff2" 2 "PressToOn1" 1 "PressToOff1" 0 "Reset" ;
VAL_ 811 GoTEditMnte_T_RqMnu 15 "Faulty" 14 "NoDataExists" 13 "NotUsed_2" 12 "NotUsed_1" 11 "Minute_55" 10 "Minute_50" 9 "Minute_45" 8 "Minute_40" 7 "Minute_35" 6 "Minute_30" 5 "Minute_25" 4 "Minute_20" 3 "Minute_15" 2 "Minute_10" 1 "Minute_5" 0 "Minute_0" ;
VAL_ 811 GoTEditHr_T_RqMnu 31 "Faulty" 30 "NoDataExists" ;
VAL_ 563 BattChrgStrtStop_D_Rq 3 "ReturnToSettings" 2 "StopCharge" 1 "StartCharge" 0 "NoNewRequest" ;
VAL_ 563 DrvBhavWarn_B_Rq 1 "On" 0 "Off" ;
VAL_ 563 OfbChrgSetSync_D_Rq 3 "Fail" 2 "Success" 1 "InProgress" 0 "NoSyncInProgress" ;
VAL_ 563 KeyOffPwMde_D_Stat 7 "NotUsed_6" 6 "NotUsed_5" 5 "NotUsed_4" 4 "NotUsed_3" 0 "Inactive" 1 "On" 2 "NotUsed_1" 3 "NotUsed_2" ;
VAL_ 563 ModemReset_D_Stat 15 "NotUsed_10" 14 "NotUsed_9" 13 "NotUsed_8" 12 "NotUsed_7" 11 "NotUsed_6" 10 "NotUsed_5" 9 "NotUsed_4" 8 "NotUsed_3" 7 "NotUsed_2" 6 "NotUsed_1" 5 "WifiHotSpotResetComplete" 4 "CcsResetComplete" 3 "OnlineTrafficResetComplete" 2 "PaakResetComplete" 1 "ResetNotComplete" 0 "Null" ;
VAL_ 563 FactoryReset_St 3 "NotUsed_2" 2 "NotUsed_1" 1 "FactoryDefaultsRestored" 0 "Null" ;
VAL_ 794 HvacBlwrRear_D_Stat_UB 1 "Fresh_data" 0 "Unchanged_data" ;
VAL_ 794 HvacBlwrFront_D_Stat_UB 1 "Fresh_data" 0 "Unchanged_data" ;
VAL_ 794 HvacBlwrRear_D_Stat 31 "Not_Used" 20 "Full_On" 19 "95_Percent" 18 "90_Percent" 17 "85_Percent" 16 "80_Percent" 15 "75_Percent" 14 "70_Percent" 13 "65_Percent" 12 "60_Percent" 11 "55_Percent" 10 "50_Percent" 9 "45_Percent" 8 "40_Percent" 7 "35_Percent" 6 "30_Percent" 5 "25_Percent" 4 "20_Percent" 3 "15_Percent" 2 "10_Percent" 1 "5_Percent" 0 "Off" ;
VAL_ 794 HvacBlwrFront_D_Stat 31 "Not_Used" 20 "Full_On" 19 "95_Percent" 18 "90_Percent" 17 "85_Percent" 16 "80_Percent" 15 "75_Percent" 14 "70_Percent" 13 "65_Percent" 12 "60_Percent" 11 "55_Percent" 10 "50_Percent" 9 "45_Percent" 8 "40_Percent" 7 "35_Percent" 6 "30_Percent" 5 "25_Percent" 4 "20_Percent" 3 "15_Percent" 2 "10_Percent" 1 "5_Percent" 0 "Off" ;
VAL_ 794 SpotLghtLeft_D_Stat_UB 1 "Fresh_data" 0 "Unchanged_data" ;
VAL_ 794 SpotLghtRight_D_Stat_UB 1 "Fresh_data" 0 "Unchanged_data" ;
VAL_ 794 SpotLghtRight_D_Stat 1 "On" 0 "Off" ;
VAL_ 794 SpotLghtLeft_D_Stat 1 "On" 0 "Off" ;
VAL_ 1146 TrlrAidSwtch_D_RqDrv 3 "Faulty" 2 "NotUsed" 1 "Pressed" 0 "Not_Pressed" ;
VAL_ 1146 TrlrAidCtl_U_RqDrv 4095 "Faulty" 4094 "NoDataExists" ;
VAL_ 1146 TrlrAidAn_URate_Actl 4095 "Faulty" 4094 "NoDataExists" ;
VAL_ 1146 TrlrAidAn_U_Actl 4095 "Faulty" 4094 "NoDataExists" ;
VAL_ 1109 eCallConfirmation 7 "Unused_2" 6 "CallComplete_DTMF_Timeout" 5 "eCall_Configured_Off" 4 "Call_Unsuccessful" 3 "Call_Cancelled" 2 "Call_Completed" 1 "Call_In_Progress" 0 "Normal" ;
VAL_ 140 CcAslButtnIndxIncPress2 1 "Button_Pressed" 0 "Button_Not_Pressed" ;
VAL_ 140 SteWhlSwtchMde_D_Stat 3 "NotUsed_2" 2 "NotUsed_1" 1 "Dialog" 0 "Domain" ;
VAL_ 140 CcAslButtnOffCnclPress2 1 "Button_Pressed" 0 "Button_Not_Pressed" ;
VAL_ 140 CcAslButtnIndxDecPress2 1 "Button_Pressed" 0 "Button_Not_Pressed" ;
VAL_ 140 CcAslButtnCnclResPress2 1 "Button_Pressed" 0 "Button_Not_Pressed" ;
VAL_ 140 CcAslButtnResIncPress3 1 "Pressed" 0 "Not pressed" ;
VAL_ 140 CcButtnOnPress3 1 "Pressed" 0 "Not pressed" ;
VAL_ 140 CcButtnOnOffPress3 1 "Pressed" 0 "Not pressed" ;
VAL_ 140 CcButtnOnOffCnclPress3 1 "Pressed" 0 "Not pressed" ;
VAL_ 140 CcButtnOffPress3 1 "Pressed" 0 "Not pressed" ;
VAL_ 140 CcAsllButtnResPress3 1 "Pressed" 0 "Not pressed" ;
VAL_ 140 CcAslButtnSetPress3 1 "Pressed" 0 "Not pressed" ;
VAL_ 140 CcAslButtnSetIncPress3 1 "Pressed" 0 "Not pressed" ;
VAL_ 140 CcAslButtnSetDecPress3 1 "Pressed" 0 "Not pressed" ;
VAL_ 140 CcAslButtnResDecPress3 1 "Pressed" 0 "Not pressed" ;
VAL_ 140 CcAslButtnOnPress3 1 "Pressed" 0 "Not pressed" ;
VAL_ 140 CcAslButtnOnOffCncl3 1 "Pressed" 0 "Not pressed" ;
VAL_ 140 CcAslButtnDeny_B_Actl3 1 "Pressed" 0 "Not pressed" ;
VAL_ 140 CcAslButtnCnclPress3 1 "Pressed" 0 "Not pressed" ;
VAL_ 140 AslButtnOnOffPress3 1 "Pressed" 0 "Not pressed" ;
VAL_ 140 AslButtnOnOffCnclPress2 1 "Pressed" 0 "Not pressed" ;
VAL_ 546 PrplSnd_D_Rq 3 "NotUsed" 2 "Enabled" 1 "Disabled" 0 "Null" ;
VAL_ 546 SYNC_New_Attn_Event 1 "Active" 0 "Inactive" ;
VAL_ 546 SYNC_Attn_Info_Audio 7 "Unknown" 6 "Attenuation_6" 5 "Attenuation_5" 4 "Attenuation_4" 3 "Attenuation_3" 2 "Attenuation_2" 1 "Attenuation_1" 0 "Inactive" ;
VAL_ 546 Prompt_Directionality 3 "RearSpeakers" 2 "FrontSpeakers" 1 "ALL" 0 "Inactive" ;
VAL_ 546 Audible_Beep 1 "Active" 0 "Inactive" ;
VAL_ 546 Alert_Chan 2 "Initialize_for_Prompts" 1 "Mute" 0 "Inactive" ;
VAL_ 1186 AwdDrvMde_D2_Stat 15 "Faulty" 14 "NotUsed_7" 13 "NotUsed_6" 12 "NotUsed_5" 11 "NotUsed_4" 10 "NotUsed_3" 9 "NotUsed_2" 8 "NotUsed_1" 7 "NotAvailable" 6 "TowHaul" 5 "RockCrawl" 4 "Baja" 3 "MudAndSand" 2 "Weather" 1 "Sport" 0 "Normal" ;
VAL_ 1186 FrontDiffLckLamp_D_Rq 3 "Triggered" 2 "Flash" 1 "On" 0 "Off" ;
VAL_ 1186 FrontDiffLckMsg_D_Rq 7 "LockerDisabled" 6 "LockerEnabled" 5 "LockerAccelPedal" 4 "Speed4" 3 "Speed3" 2 "Speed2" 1 "Speed1" 0 "NormalNoMessage" ;
VAL_ 1186 AwdStat2_D_RqDsply 31 "NotUsed_29" 30 "NotUsed_28" 29 "NotUsed_27" 28 "NotUsed_26" 27 "NotUsed_25" 26 "NotUsed_24" 25 "NotUsed_23" 24 "NotUsed_22" 23 "NotUsed_21" 22 "NotUsed_20" 21 "NotUsed_19" 20 "NotUsed_18" 19 "NotUsed_17" 18 "NotUsed_16" 17 "NotUsed_15" 16 "NotUsed_14" 15 "NotUsed_13" 14 "NotUsed_12" 13 "NotUsed_11" 12 "NotUsed_10" 11 "NotUsed_9" 10 "NotUsed_8" 9 "NotUsed_7" 8 "NotUsed_6" 7 "NotUsed_5" 6 "NotUsed_4" 5 "NotUsed_3" 4 "NotUsed_2" 3 "HillHoldFail" 2 "TCaseOilChanged" 1 "ChangeTCaseOil" 0 "Normal" ;
VAL_ 1186 RearDiffLckLamp_D_Rq 3 "Not_Used" 2 "Flash" 1 "On" 0 "Off" ;
VAL_ 1186 RearDiffFalt_D_Stat 3 "Diff_Failed_Closed" 2 "Diff_Failed_Open" 1 "Fault_Non_Specific" 0 "No_Fault" ;
VAL_ 1186 RearDiffLck_Tq_Actl 4095 "Fault" 4094 "Unknown" ;
VAL_ 1186 FrontDiffFalt_D_Stat 3 "Diff_Failed_Closed" 2 "Diff_Failed_Open" 1 "Fault_Non_Specific" 0 "No_Fault" ;
VAL_ 1186 FrontDiffLck_Tq_Actl 16383 "Faulty" 16382 "NoDataExists" ;
VAL_ 1186 SelDrvMdeAwd2_D_Stat 31 "Faulty" 30 "NotUsed_17" 29 "NotUsed_16" 28 "NotUsed_15" 27 "NotUsed_14" 26 "NotUsed_13" 25 "NotUsed_12" 24 "NotUsed_11" 23 "NotUsed_10" 22 "NotUsed_9" 21 "NotUsed_8" 20 "NotUsed_7" 19 "NotUsed_6" 18 "NotUsed_5" 17 "EvLaterChargeMode" 16 "EvNowMode" 15 "TrackMode" 14 "RoughRoadMode" 13 "NotAvailable" 12 "HighSpeedDesertMode_Baja" 11 "SportAdaptiveMode" 10 "RockCrawlMode" 9 "MudRutsMode" 8 "SandMode" 7 "EconomyMode" 6 "GrassGravelSnow" 5 "TowHaulMode" 4 "SportMode" 3 "Normal_4L" 2 "Normal_4A" 1 "Normal_2H" 0 "NormalMode" ;
VAL_ 1186 RearDiffLckMsg_D_Rq 7 "Locker_Disabled" 6 "Locker_Enabled" 5 "Locker_Accel_Pedal" 4 "Speed4" 3 "Speed3" 2 "Spee2" 1 "Speed1" 0 "Normal__No_Message " ;
VAL_ 1186 LsdSrvcRqd_B_Rq 1 "On" 0 "Off" ;
VAL_ 1130 DrvSlipCtlOffLamp_D_Rq_UB 1 "Fresh_data" 0 "Unchanged_data" ;
VAL_ 1130 DrvSlipCtlMdeMsg_D_Rq_UB 1 "Fresh_data" 0 "Unchanged_data" ;
VAL_ 1130 DrvSlipCtlOffLamp_D_Rq 3 "Fast_Flash" 2 "Slow_Flash" 1 "On" 0 "Off" ;
VAL_ 1130 DrvSlipCtlMdeMsg_D_Rq 31 "Message31" 30 "Message30" 29 "Message29" 28 "Message28" 27 "Message27" 26 "Message26" 25 "Message25" 24 "Message24" 23 "Message23" 22 "Message22" 21 "Message21" 20 "Message20" 19 "Message19" 18 "Message18" 17 "Message17" 16 "Message16" 15 "Message15" 14 "Message14" 13 "Message13" 12 "Message12" 11 "Message11" 10 "Message10" 9 "Message9" 8 "Message8" 7 "Message7" 6 "Message6" 5 "Message5" 4 "Message4" 3 "Message3" 2 "Message2" 1 "Message1" 0 "NoMessage" ;
VAL_ 1130 HtrnWarnLamp_B_Dsply_UB 1 "Fresh_data" 0 "Unchanged_data" ;
VAL_ 1130 HtrnWarnLamp_B_Dsply 1 "On" 0 "Off" ;
VAL_ 1130 HtrnSrvcRqd_B_Dsply_UB 1 "Fresh_data" 0 "Unchanged_data" ;
VAL_ 1130 HtrnSrvcRqd_B_Dsply 1 "On" 0 "Off" ;
VAL_ 1130 ChrgrSrvcRqd_B_Rq_UB 1 "Fresh_data" 0 "Unchanged_data" ;
VAL_ 1130 ChrgrSrvcRqd_B_Rq 1 "On" 0 "Off" ;
VAL_ 1130 BattTracSrvcRqd_B_Rq_UB 1 "Fresh_data" 0 "Unchanged_data" ;
VAL_ 1130 BattTracSrvcRqd_B_Rq 1 "On" 0 "Off" ;
VAL_ 1130 BrkPadMsgTxt_D_Rq_UB 1 "Fresh_data" 0 "Unchanged_data" ;
VAL_ 1130 BrkPadMsgTxt_D_Rq 3 "Faulty" 2 "PadsOk" 1 "ReplacePads" 0 "Null" ;
VAL_ 1130 SuspDrvMde_D_Stat 7 "Faulty" 6 "NotUsed2" 5 "NotUsed1" 4 "Drag" 3 "Track" 2 "Snow_Wet" 1 "Sport" 0 "Normal" ;
VAL_ 1130 SuspDrvMde_D_Stat_UB 1 "Fresh_data" 0 "Unchanged_data" ;
VAL_ 1042 TrlrAnCalib_Pc_Actl 15 "Faulty" ;
VAL_ 1042 VehRol_An_Dsply_UB 1 "Fresh_data" 0 "Unchanged_data" ;
VAL_ 1042 VehPtch_An_Dsply_UB 1 "Fresh_data" 0 "Unchanged_data" ;
VAL_ 1042 VehRol_An_Dsply 127 "Faulty" 126 "NoDataExists" ;
VAL_ 1042 VehPtch_An_Dsply 127 "Faulty" 126 "NoDataExists" ;
VAL_ 1042 TrlrBrk_Pc_Rq_UB 1 "Fresh_data" 0 "Unchanged_data" ;
VAL_ 1042 VehYaw_W_Actl_UB 1 "Fresh_data" 0 "Unchanged_data" ;
VAL_ 1042 VehYaw_W_Actl 65535 "Faulty" 65534 "NoDataExists" ;
VAL_ 1093 TrlBrkInitOut_D_Stat 3 "Heavy" 2 "Medium" 1 "Light" 0 "Null" ;
VAL_ 1093 TrlrBrkMde_D_Actl 1 "Electric_Over_Hydraulic" 0 "Electric" ;
VAL_ 1093 TrlrBrkDsply_B_Rq 1 "Yes" 0 "No" ;
VAL_ 1093 TrlrBrkDcnnt_B_Actl 1 "Yes" 0 "No" ;
VAL_ 1093 TrlrBrkActCnnct_B_Actl 1 "Yes" 0 "No" ;
VAL_ 1093 StopLamp_B_RqTrlrBrk 1 "Yes" 0 "No" ;
VAL_ 1093 TrlrBrkCtl_B_Falt 1 "Yes" 0 "No" ;
VAL_ 1093 TrlrBrkActCirct_B_Falt 1 "Yes" 0 "No" ;
VAL_ 1138 BattChrgTrgtLMin_T_Est 2047 "Faulty" 2046 "NoDataExists" ;
VAL_ 1138 ActChrgEndYr_No_Actl 31 "Invalid" ;
VAL_ 1138 ActChrgEndMnth_No_Actl 15 "Invalid" ;
VAL_ 1138 ActChrgEndMin_No_Actl 63 "Invalid" 62 "Unknown" ;
VAL_ 1138 ActChrgEndHr_No_Actl 31 "Invalid" 30 "Unknown" ;
VAL_ 1138 ActChrgEndDay_No_Actl 31 "Invalid" ;
VAL_ 1139 BattChrgTrgtLMax_T_Est 2047 "Faulty" 2046 "NoDataExists" ;
VAL_ 1139 ActChrgStrtYr_No_Actl 31 "Invalid" ;
VAL_ 1139 ActChrgStrtMin_No_Actl 63 "Invalid" 62 "Unknown" ;
VAL_ 1139 ActChrgStrtHr_No_Actl 31 "Invalid" 30 "Unknown" ;
VAL_ 1139 ActChrgStrtDay_No_Actl 31 "Invalid" ;
VAL_ 1139 ActChrgStrMnth_No_Actl 15 "Invalid" ;
VAL_ 1145 EstmChrgTimeLP_St 255 "Invalid" ;
VAL_ 1145 EstmChrgTimeHP_St 255 "Invalid" ;
VAL_ 1145 ChargeNowDuration_St 255 "Invalid" ;
VAL_ 1145 VehElRngeNut_L2_Dsply 8191 "Faulty" 8190 "NoDataExists" ;
VAL_ 1145 VehElRngeNut_L_Dsply 4095 "Faulty" 4094 "NoDataExists" ;
VAL_ 1145 NxtUsgSocEst_Pc_Dsply 255 "Faulty" 254 "NoDataExists" ;
VAL_ 1232 AHU_EnsembleName_St 1 "Supported" 0 "Not_Supported" ;
VAL_ 1232 AHU_AutoConfigOcc_Shakr 1 "Supported" 0 "Not_Supported" ;
VAL_ 1232 AHU_AutoConfigOcc_Rear 1 "Supported" 0 "Not_Supported" ;
VAL_ 1232 AHU_AutoConfigOcc_Front 1 "Supported" 0 "Not_Supported" ;
VAL_ 1232 AHU_AutoConfigOcc_Drvr 1 "Supported" 0 "Not_Supported" ;
VAL_ 1232 AHU_AutoConfigOcc_Cnvrt 1 "Supported" 0 "Not_Supported" ;
VAL_ 1232 AHU_AutoConfigOcc_Allst 1 "Supported" 0 "Not_Supported" ;
VAL_ 1232 ACU_DigitalRadio_St 5 "DAB_RadioSystemWithPTY_JAP" 4 "DAB_RadioSystemWithPTY_GCC" 3 "DAB_RadioSystemWithPTY_NA" 2 "DAB_RadioSystemWithPTY_EU_AndROW" 1 "WithoutDigitalRadioSystem" 0 "Invalid" ;
VAL_ 1232 ACU_Configuration 6 "HIN_HSRNS" 0 "Invalid" 1 "LowLevelAudio" 2 "HighLevelAudio" 3 "LowLevelNavigation" 4 "HighLevelNavigation" 5 "HIN_LSRNS" ;
VAL_ 1232 ACU_MediaPlayer_St 0 "Invalid" 1 "MusicCassettePlayer" 2 "CdSinglePlayer" 3 "CdChanger" ;
VAL_ 1141 AirAmbTePlgIn_D_Dsply 3 "NotUsed" 2 "Hot_Outside_Plg_In_Msg" 1 "Cold_Outside_Plg_In_Msg" 0 "No_Plg_In_Msg" ;
VAL_ 1141 PtRmtRprt_D_Rq 15 "NotUsed_4" 14 "NotUsed_3" 13 "NotUsed_2" 12 "PlugInToMaintain12vBattery" 11 "SettingUpdated" 10 "FastChargeComplete" 9 "ChargeNotOccurring" 8 "OneTimeSocReached" 7 "BatteryTemperatureReminder" 6 "ReducedPerformance" 5 "LimitedPerformance" 4 "ChargeFault" 3 "ChargeComplete" 2 "VehiclePreconditioned" 1 "TripDistanceAchieved" 0 "NoReportRequest" ;
VAL_ 1141 NxtUsg_D_Rq 0 "Invalid" 1 "Not_Requested" 2 "Requested" 3 "NotUsed" ;
VAL_ 1141 NtfctnConflict1_D_Rq 7 "NotUsed_4" 6 "NotUsed_3" 5 "NotUsed_2" 4 "NotUsed_1" 3 "ChargeWindow" 2 "DepartureTime" 1 "NoConflictExists" 0 "Null" ;
VAL_ 1141 ChrgLocGPS_D_Rq 0 "Inactive" 1 "Not_Requested" 2 "Requested" 3 "NotUsed" ;
VAL_ 1141 OfbChrgSetSync_D_Stat 3 "Fail" 2 "Success" 1 "InProgress" 0 "NoSyncInProgress" ;
VAL_ 631 RearPassWindowPos 7 "Unused2" 6 "Unused1" 5 "Fully_Open" 4 "Bet60Percent_FullyOpen" 3 "Bet10Percent_60Percent" 2 "BetFully_10PercentOpen" 1 "Fully_Closed" 0 "Undefined" ;
VAL_ 631 RearDriverWindowPos 7 "Unused2" 6 "Unused1" 5 "Fully_Open" 4 "Bet60Percent_FullyOpen" 3 "Bet10Percent_60Percent" 2 "BetFully_10PercentOpen" 1 "Fully_Closed" 0 "Undefined" ;
VAL_ 631 PassWindowPosition 7 "Unused2" 6 "Unused1" 5 "Fully_Open" 4 "Bet60Percent_FullyOpen" 3 "Bet10Percent_60Percent" 2 "BetFully_10PercentOpen" 1 "Fully_Closed" 0 "Undefined" ;
VAL_ 631 RearPassWindowPos_UB 1 "Fresh_data" 0 "Unchanged_data" ;
VAL_ 631 RearDriverWindowPos_UB 1 "Fresh_data" 0 "Unchanged_data" ;
VAL_ 631 PassWindowPosition_UB 1 "Fresh_data" 0 "Unchanged_data" ;
VAL_ 631 DriverWindowPosition 7 "Unused2" 6 "Unused1" 5 "Fully_Open" 4 "Bet60Percent_FullyOpen" 3 "Bet10Percent_60Percent" 2 "BetFully_10PercentOpen" 1 "Fully_Closed" 0 "Undefined" ;
VAL_ 631 DriverWindowPosition_UB 1 "Fresh_data" 0 "Unchanged_data" ;
VAL_ 631 CnvtTopPos_Up_Stat 1 "Up" 0 "Not_Up" ;
VAL_ 631 Memory_Cmd 7 "Recall_3" 4 "Store_4" 3 "Store_3" 6 "Recall_2" 5 "Recall_1" 2 "Store_2" 1 "Store_1" 0 "Null" 8 "Recall_4" ;
VAL_ 631 CnvtTopPos_Up_Stat_UB 1 "Fresh_data" 0 "Unchanged_data" ;
VAL_ 631 Memory_Cmd_UB 1 "Fresh_data" 0 "Unchanged_data" ;
VAL_ 631 EstmChrgTimeLP_St 255 "Invalid" ;
VAL_ 631 EstmChrgTimeHP_St 255 "Invalid" ;
VAL_ 631 ChargeNowDuration_St 255 "Invalid" ;
VAL_ 631 CnvtTopMsgTxt_D_Rq_UB 1 "Fresh_data" 0 "Unchanged_data" ;
VAL_ 631 CnvtTopMsgTxt_D_Rq 3 "NotSecure" 2 "NotAvailable" 1 "RemoveCaps" 0 "NoWarning" ;
VAL_ 631 CnvtTopPos_Dn_Stat_UB 1 "Fresh_data" 0 "Unchanged_data" ;
VAL_ 631 CnvtTopPos_Dn_Stat 1 "Down" 0 "Not_Down" ;
VAL_ 631 EstmChrgTimeLP_St_UB 1 "Fresh_data" 0 "Unchanged_data" ;
VAL_ 631 EstmChrgTimeHP_St_UB 1 "Fresh_data" 0 "Unchanged_data" ;
VAL_ 631 ChargeNowDuration_St_UB 1 "Fresh_data" 0 "Unchanged_data" ;
VAL_ 1140 BattTracPw_Pc_Avail 255 "Faulty" 254 "NoDataExists" ;
VAL_ 1140 RgenLongTerm_L_Dsply 16777215 "Faulty" 16777214 "NoDataExists" ;
VAL_ 1140 PreCondStat_D_Dsply 7 "Reserved3" 6 "Reserved2" 5 "Reserved1" 4 "Faulted" 3 "Complete" 2 "In_Progress" 1 "Scheduled" 0 "Not_Scheduled" ;
VAL_ 1140 RgenEvntLvl_Pc_Dsply 1023 "Fault" 1022 "NoDataExists" ;
VAL_ 1140 BrkEvntComplt_B_Dsply 1 "On" 0 "Off" ;
VAL_ 1140 ExtChrgrFalt_B_Dsply 1 "Yes" 0 "No" ;
VAL_ 873 BattTracEMaint_B_Dsply 1 "On" 0 "Off" ;
VAL_ 873 EffRelTrgtOn_B_Dsply 1 "On" 0 "Off" ;
VAL_ 873 GpsElMdeActv_B_Dsply 1 "On" 0 "Off" ;
VAL_ 873 LoAirAmbPlgIn_B_Dsply 1 "On" 0 "Off" ;
VAL_ 871 BattElecPerf_D_Actl 7 "NotUsed" 6 "Hot_Batt_Severe_Lim_Perf" 5 "Hot_Batt_Reduced_Perf" 4 "Hot_Batt_Close_to_lim_Per" 3 "Cold_Batt_Severe_Lim_Perf" 2 "Cold_Batt_Reduced_Perf" 1 "Cold_Batt_Close_to_lim_Pe" 0 "Ok_no_message_displayed" ;
VAL_ 871 BattChrgTrgtLPt_T_Est 2047 "Faulty" 2046 "NoDataExists" ;
VAL_ 871 BattChrgTrgSocPt_T_Est 2047 "Faulty" 2046 "NoDataExists" ;
VAL_ 871 BattChrgCmpltPt_T_Est 2047 "Faulty" 2046 "NoDataExists" ;
VAL_ 871 DrvEffLvlIncDec_D_Cmd 3 "NotUsed" 2 "Decrease_Level_by_1" 1 "Increase_Level_by_1" 0 "Null_State" ;
VAL_ 870 PolicePurstMde_B_Stat 1 "On" 0 "Off" ;
VAL_ 870 RngPerChrgInst_L_Dsply 4095 "Faulty" 4094 "NoDataExists" ;
VAL_ 870 ChkPlgtoStrt_D_Dsply 3 "NotUsed" 2 "Is_VehicleUnplugged_Prompt" 1 "Check_Plug_to_Start" 0 "No_Message_Display" ;
VAL_ 870 HybMdeLimMsgTxt_D_Rq 3 "Limited_Req_Full_Defrost" 2 "Limited_Climate_Defrost" 1 "Limited_System_Performance" 0 "Null" ;
VAL_ 870 HybMdeMsgTxt_D2_Rq 15 "NotUsed_4" 14 "NotUsed_3" 13 "NotUsed_2" 12 "NotUsed_1" 11 "EvOverride_Avail" 10 "EvLaterActv_EvAuto_NowAvai" 9 "EvNowActv_EvAuto_LaterAvai" 8 "EvAutoActv_EvNow_LaterAvai" 7 "EvAutoActv_NoOtherMdeAvail" 6 "EvChrgActv_EvAutoMdeAvail" 5 "EvAutoActv_EvChrgMdeAvail" 4 "EvChrgActv_AllPhevMdeAvail" 3 "EvLaterActv_AllPhevMdeAvai" 2 "EvNowActv_AllPhevMdeAvail" 1 "EvAutoActv_AllPhevMdeAvail" 0 "Null" ;
VAL_ 870 EngMdeMsgTxt_D_Rq 7 "NotUsed_3" 6 "NotUsed_2" 5 "NotUsed_1" 4 "Charge" 3 "GlowingCharge" 2 "Hybrid" 1 "Ev" 0 "NoMessage" ;
VAL_ 870 ShifOutNtrlMsgTxt_D_Rq 7 "Message7" 6 "Message6" 5 "Message5" 4 "Message4" 3 "Message3" 2 "Message2" 1 "Message1" 0 "NoMessage" ;
VAL_ 869 PwrFlowTxt_D_Dsply 15 "NotUsed7" 14 "NotUsed6" 13 "NotUsed5" 12 "NotUsed4" 11 "Disply_Rgen_Chrg_Txt" 10 "Disp_Fast_Charge_Txt" 9 "Disp_Fast_Charge_Cmplt_Txt" 8 "Disp_Charge_Cmplt_Txt" 7 "Disp_Remote_Start_Txt" 6 "Disp_Eng_Drv_Txt" 5 "Disp_Elec_Drv_Txt" 4 "Disp_Idle_with_Chrg_Txt" 3 "Disp_Idle_Txt" 2 "Disp_Charg_HV_Batt_Txt" 1 "Disp_Hyb_Drive_Txt" 0 "No_Text" ;
VAL_ 869 EngOnMsg2_D_Dsply 14 "_0xE_to_1F_NotUsed" 12 "Battery_Temperature" 11 "Hill_Decent_Control" 10 "Fuel_Maintenance" 9 "Oil_Maintenance" 8 "Normal_Operation" 7 "Low_Gear" 6 "Batt_Charging" 5 "Engine_Cold" 4 "Neutral_Gear" 3 "Heater_Setting" 2 "High_Speed" 1 "Acceleration" 0 "No_Display" 13 "Drive_Mode_Selection" ;
VAL_ 869 EngOnMsg1_D_Dsply 14 "_0xE_to_1F_NotUsed" 12 "Battery_Temperature" 11 "Hill_Decent_Control" 10 "Fuel_Maintenance" 9 "Oil_Maintenance" 8 "Normal_Operation" 7 "Low_Gear" 6 "Batt_Charging" 5 "Engine_Cold" 4 "Neutral_Gear" 3 "Heater_Setting" 2 "High_Speed" 1 "Acceleration" 0 "No_Display" 13 "Drive_Mode_Selection" ;
VAL_ 869 FuelMaintMde_D_Dsply 3 "Feature_Not_Present" 2 "In_Fuel_Maint_Mode" 1 "Close_to_Fuel_Maint" 0 "OK" ;
VAL_ 869 RgenActv_B_Dsply 1 "On" 0 "Off" ;
VAL_ 869 EngOffTe_B_Dsply 1 "Eng_warm_engh_for_pd" 0 "Eng_not_warm_engh_for_pd" ;
VAL_ 869 EngActv_B_Dsply 1 "On" 0 "Off" ;
VAL_ 869 EffWhlThresOn_B_Dsply 1 "On" 0 "Off" ;
VAL_ 869 DchrgActv_B_Dsply 1 "On" 0 "Off" ;
VAL_ 869 ChrgActv_B_Dsply 1 "On" 0 "Off" ;
VAL_ 786 VehElRnge_L2_Dsply 8191 "Faulty" 8190 "NoDataExists" ;
VAL_ 786 RgenTrip_L_Dsply 65535 "Fault" 65534 "NoDataExists" ;
VAL_ 786 VehElRngeCyc_L_Dsply 4095 "Faulty" 4094 "NoDataExists" ;
VAL_ 786 PtDataKeyId_D_Stat 15 "NotUsed5" 14 "NotUsed4" 13 "NotUsed3" 12 "NotUsed2" 11 "NotUsed1" 10 "Tot_Veh_NUT" 9 "Cust_4_NUT" 8 "Cust_3_NUT" 7 "Cust_2_NUT" 6 "Cust_1_NUT" 5 "Tot_Veh_Stat" 4 "Cust_4_Stat" 3 "Cust_3_Stat" 2 "Cust_2_Stat" 1 "Cust_1_Stat" 0 "Null" ;
VAL_ 786 ChrgStat_D_Dsply 7 "NotUsed" 6 "Complete" 5 "Scheduled" 4 "In_Progress" 3 "Fault_Outside_Car" 2 "Fault_Inside_Car" 1 "Fault_Unknown_Location" 0 "Not_Ready" ;
VAL_ 1095 Pers4Phone_D_Stat 7 "SevenPhoneAssociated" 6 "SixPhoneAssociated" 5 "FivePhoneAssociated" 4 "FourPhoneAssociated" 3 "ThreePhoneAssociated" 2 "TwoPhoneAssociated" 1 "OnePhoneAssociated" 0 "NoPhoneAssociated" ;
VAL_ 1095 Pers3Phone_D_Stat 7 "SevenPhoneAssociated" 6 "SixPhoneAssociated" 5 "FivePhoneAssociated" 4 "FourPhoneAssociated" 3 "ThreePhoneAssociated" 2 "TwoPhoneAssociated" 1 "OnePhoneAssociated" 0 "NoPhoneAssociated" ;
VAL_ 1095 Pers2Phone_D_Stat 7 "SevenPhoneAssociated" 6 "SixPhoneAssociated" 5 "FivePhoneAssociated" 4 "FourPhoneAssociated" 3 "ThreePhoneAssociated" 2 "TwoPhoneAssociated" 1 "OnePhoneAssociated" 0 "NoPhoneAssociated" ;
VAL_ 1095 Pers1Phone_D_Stat 7 "SevenPhoneAssociated" 6 "SixPhoneAssociated" 5 "FivePhoneAssociated" 4 "FourPhoneAssociated" 3 "ThreePhoneAssociated" 2 "TwoPhoneAssociated" 1 "OnePhoneAssociated" 0 "NoPhoneAssociated" ;
VAL_ 1095 HeadLghtOn_D_Rq 7 "NotUsed2" 6 "NotUsed1" 5 "DrlBoth" 4 "DrlRight" 3 "DrlLeft" 2 "High" 1 "Low" 0 "Off" ;
VAL_ 1095 PepsKeyActv_D_Stat 15 "NotUsed11" 14 "NotUsed10" 13 "NotUsed9" 12 "NotUsed8" 11 "NotUsed7" 10 "NotUsed6" 9 "NotUsed5" 8 "Key4Active" 7 "NotUsed4" 6 "NotUsed3" 5 "NotUsed2" 4 "Key3Active" 3 "NotUsed1" 2 "Key2Active" 1 "Key1Active" 0 "NoKeyActive" ;
VAL_ 1095 VehLck_D_Dsply 3 "Faulty" 2 "Unlock" 1 "Lock" 0 "Off" ;
VAL_ 872 PwFlowPlgBatt_D_Dsply 3 "NotUsed" 2 "Flow_from_Plug_to_Batt" 1 "Flow_from_Batt_to_Plug" 0 "No_Flow" ;
VAL_ 872 PwFlowMtrDrv_D_Dsply 3 "NotUsed" 2 "Flow_from_Mtr_to_Axle" 1 "Flow_from_Axle_to_Mtr" 0 "No_FLow" ;
VAL_ 872 PwFlowEngMtr_D_Dsply 3 "NotUsed" 2 "Flow_from_Eng_to_Mtr" 1 "Flow_from_Mtr_to_Eng" 0 "No_Flow" ;
VAL_ 872 PwFlowEngFuel_D_Dsply 3 "NotUsed" 2 "Flow_from_Eng_to_Fuel" 1 "Flow_from_Fuel_to_Eng" 0 "No_Flow" ;
VAL_ 872 PwFlowEngDrv_D_Dsply 3 "NotUsed" 2 "Flow_from_Eng_to_Axle" 1 "Flow_from_Axle_to_Eng" 0 "No_Flow" ;
VAL_ 872 PwFlowBattMtr_D_Dsply 3 "NotUsed" 2 "Flow_from_Batt_to_Mtr" 1 "Flow_from_Mtr_to_Batt" 0 "No_Flow" ;
VAL_ 872 HybMdeStat_D_Dsply 7 "NotUsed2" 6 "EV_Charge" 5 "EV_Override" 4 "Forced_EV_Mode" 3 "Forced_Charge_Sustain_Mode" 2 "Auto_Charge_Sustain_Mode" 1 "Auto_Charge_Deplete_Mode" 0 "Null_State" ;
VAL_ 872 PlgActvArb_B_Dsply 1 "On" 0 "Off" ;
VAL_ 872 MildHybStat_D_Dsply 7 "NotUsed" 6 "Recovery" 5 "Charge" 4 "Assist" 3 "Boost" 2 "SystemInhibited" 1 "SystemError" 0 "Off" ;
VAL_ 872 EcoMode_B_Stat 1 "On" 0 "Off" ;
VAL_ 791 StopStrtVThres_D_RqMnu 3 "High" 2 "Medium" 1 "Low" 0 "NoSelection" ;
VAL_ 791 AwdDrvMde_D2_Rq 15 "Faulty" 14 "NotUsed_7" 13 "NotUsed_6" 12 "NotUsed_5" 11 "NotUsed_4" 10 "NotUsed_3" 9 "NotUsed_2" 8 "NotUsed_1" 7 "NotAvailable" 6 "TowHaul" 5 "RockCrawl" 4 "Baja" 3 "MudAndSand" 2 "Weather" 1 "Sport" 0 "Normal" ;
VAL_ 791 VehElEffTrip2Reset_B_Rq 1 "On" 0 "Off" ;
VAL_ 791 VehElEffTrip1Reset_B_Rq 1 "On" 0 "Off" ;
VAL_ 791 EngAirFilt_B_RqReset 1 "Yes" 0 "No" ;
VAL_ 791 BattElEmotive_Pc_Dsply 1023 "Faulty" 1022 "NoDataExists" ;
VAL_ 791 HybMdeOvrrd_D_Rq 3 "NotUsed" 2 "Invalid" 1 "Override" 0 "Null" ;
VAL_ 791 GpsElMdeSel_B_Rq 1 "On" 0 "Off" ;
VAL_ 791 LongTermReset_B_Rq 1 "On" 0 "Off" ;
VAL_ 791 EcoCcActv_B_Rq 1 "On" 0 "Off" ;
VAL_ 791 DrvEffLvl_No_Stat 63 "Fault" 62 "NoDataExists" ;
VAL_ 791 ChargeProfIDPref_Rq 3 "NotUsed" 2 "Value" 1 "ChargeNow" 0 "Inactive" ;
VAL_ 791 GrdAsstAllw_D_RqMnu 3 "NotUsed" 2 "On" 1 "Off" 0 "NoModeSelected" ;
VAL_ 791 PlgOvrrdStrt_D_Cmd 3 "NotUsed" 2 "Override_Plug_Status" 1 "Dont_Override_Plug_Status" 0 "Null_State" ;
VAL_ 791 EcoMde_D_RqMnu 3 "NotUsed" 2 "On" 1 "Off" 0 "Null" ;
VAL_ 791 EmotiveType_D_Dsply 3 "EmotiveDisplay_3" 2 "EmotiveDisplay_2" 1 "EmotiveDisplay_1" 0 "Null" ;
VAL_ 358 StopStrtStdby_D_Indic 6 "NotUsed2" 5 "Telltale_Struck_Out" 4 "Telltale_Flashing_Amber" 3 "Telltale_On_Amber" 2 "Telltale_Flashing_Green" 1 "Telltale_On_Green" 0 "Telltale_Off" 7 "NotUsed3" ;
VAL_ 358 StopStrtIODTxt_D_Rq 31 "Message31" 30 "Message30" 29 "Message29" 28 "Message28" 27 "Message27" 26 "Message26" 25 "Message25" 24 "Message24" 23 "Message23" 22 "Message22" 21 "Message21" 20 "Message20" 19 "Message19" 18 "Message18" 17 "Message17" 16 "Message16" 15 "Message15" 14 "Message14" 13 "Message13" 12 "Message12" 11 "Message11" 10 "Message10" 9 "Message9" 8 "Message8" 7 "Message7" 6 "Message6" 5 "Message5" 4 "Message4" 3 "Message3" 2 "Message2" 1 "Message1" 0 "NoMessage" ;
VAL_ 358 StopStrtDrvMde_D_Indic 3 "NotUsed" 2 "StartStop_IndirectDeselect" 1 "StopStart_Deselected" 0 "StopStart_Selected" ;
VAL_ 358 StopStrtMsgTxt_D_Rq 15 "Message_15" 14 "Message_14" 13 "Message_13" 12 "Message_12" 11 "Message_11" 10 "Message_10" 9 "Message_9" 8 "Message_8" 7 "Message_7" 6 "Message_6" 5 "Message_5" 4 "Message_4" 3 "Message_3" 2 "Message_2" 1 "Message_1" 0 "NoMessage" ;
VAL_ 358 OdoTripVerify_L_Actl 16777215 "Fault" ;
VAL_ 358 HiElPwInhbt_B_Stat 1 "Inhibit" 0 "No_Inibit" ;
VAL_ 358 AutoStopPtDelta_I_Est 255 "Fault" ;
VAL_ 840 FohAddHeater_D_Rq 3 "NotUsed" 2 "On" 1 "Off" 0 "NoModeSelected" ;
VAL_ 840 FohT2Friday_T_Rq 1 "Enable" 0 "Disable" ;
VAL_ 840 FohT1Friday_T_Rq 1 "Enable" 0 "Disable" ;
VAL_ 840 FohT2Wednesday_T_Rq 1 "Enable" 0 "Disable" ;
VAL_ 840 FohT2Tuesday_T_Rq 1 "Enable" 0 "Disable" ;
VAL_ 840 FohT2Thursday_T_Rq 1 "Enable" 0 "Disable" ;
VAL_ 840 FohT2Sunday_T_Rq 1 "Enable" 0 "Disable" ;
VAL_ 840 FohT2Saturday_T_Rq 1 "Enable" 0 "Disable" ;
VAL_ 840 FohT2Monday_T_Rq 1 "Enable" 0 "Disable" ;
VAL_ 840 FohT1Wednesday_T_Rq 1 "Enable" 0 "Disable" ;
VAL_ 840 FohT1Tuesday_T_Rq 1 "Enable" 0 "Disable" ;
VAL_ 840 FohT1Thursday_T_Rq 1 "Enable" 0 "Disable" ;
VAL_ 840 FohT1Sunday_T_Rq 1 "Enable" 0 "Disable" ;
VAL_ 840 FohT1Saturday_T_Rq 1 "Enable" 0 "Disable" ;
VAL_ 840 FohT1Monday_T_Rq 1 "Enable" 0 "Disable" ;
VAL_ 945 KeyPadCodeDgt7_D_Dsply 15 "NotUsed_4" 14 "NotUsed_3" 13 "NotUsed_2" 12 "NotUsed_1" 11 "Button7_8and9_0" 10 "Button0" 9 "Button9_0or9" 8 "Button8" 7 "Button7_8or7" 6 "Button6" 5 "Button5_6or5" 4 "Button4" 3 "Button3_4or3" 2 "Button2" 1 "Button1_2or1" 0 "EndofString" ;
VAL_ 945 KeyPadCodeDgt6_D_Dsply 15 "NotUsed_4" 14 "NotUsed_3" 13 "NotUsed_2" 12 "NotUsed_1" 11 "Button7_8and9_0" 10 "Button0" 9 "Button9_0or9" 8 "Button8" 7 "Button7_8or7" 6 "Button6" 5 "Button5_6or5" 4 "Button4" 3 "Button3_4or3" 2 "Button2" 1 "Button1_2or1" 0 "EndofString" ;
VAL_ 945 KeyPadCodeDgt5_D_Dsply 15 "NotUsed_4" 14 "NotUsed_3" 13 "NotUsed_2" 12 "NotUsed_1" 11 "Button7_8and9_0" 10 "Button0" 9 "Button9_0or9" 8 "Button8" 7 "Button7_8or7" 6 "Button6" 5 "Button5_6or5" 4 "Button4" 3 "Button3_4or3" 2 "Button2" 1 "Button1_2or1" 0 "EndofString" ;
VAL_ 945 KeyPadCodeDgt4_D_Dsply 15 "NotUsed_4" 14 "NotUsed_3" 13 "NotUsed_2" 12 "NotUsed_1" 11 "Button7_8and9_0" 10 "Button0" 9 "Button9_0or9" 8 "Button8" 7 "Button7_8or7" 6 "Button6" 5 "Button5_6or5" 4 "Button4" 3 "Button3_4or3" 2 "Button2" 1 "Button1_2or1" 0 "EndofString" ;
VAL_ 945 KeyPadCodeDgt3_D_Dsply 15 "NotUsed_4" 14 "NotUsed_3" 13 "NotUsed_2" 12 "NotUsed_1" 11 "Button7_8and9_0" 10 "Button0" 9 "Button9_0or9" 8 "Button8" 7 "Button7_8or7" 6 "Button6" 5 "Button5_6or5" 4 "Button4" 3 "Button3_4or3" 2 "Button2" 1 "Button1_2or1" 0 "EndofString" ;
VAL_ 945 KeyPadCodeDgt2_D_Dsply 15 "NotUsed_4" 14 "NotUsed_3" 13 "NotUsed_2" 12 "NotUsed_1" 11 "Button7_8and9_0" 10 "Button0" 9 "Button9_0or9" 8 "Button8" 7 "Button7_8or7" 6 "Button6" 5 "Button5_6or5" 4 "Button4" 3 "Button3_4or3" 2 "Button2" 1 "Button1_2or1" 0 "EndofString" ;
VAL_ 945 KeyPadCodeDgt1_D_Dsply 15 "NotUsed_4" 14 "NotUsed_3" 13 "NotUsed_2" 12 "NotUsed_1" 11 "Button7_8and9_0" 10 "Button0" 9 "Button9_0or9" 8 "Button8" 7 "Button7_8or7" 6 "Button6" 5 "Button5_6or5" 4 "Button4" 3 "Button3_4or3" 2 "Button2" 1 "Button1_2or1" 0 "EndofString" ;
VAL_ 945 KeyOffMde_D_Actl 15 "NotUsed_11" 14 "NotUsed_10" 13 "NotUsed_9" 12 "NotUsed_8" 11 "NotUsed_7" 10 "NotUsed_6" 9 "NotUsed_5" 8 "NotUsed_4" 7 "NotUsed_3" 6 "NotUsed_2" 5 "NotUsed_1" 4 "CriticalBattery" 3 "Hibernate" 2 "Transport" 1 "Factory" 0 "Normal" ;
VAL_ 945 PrkLckCtlLatch_B_Rq 1 "On" 0 "Off" ;
VAL_ 740 EmgcyAsstActv_D_Stat 3 "ConfiguredOff" 2 "Active" 1 "Inactive" 0 "Null" ;
VAL_ 1055 EcoCochInstNeg_B_Dsply 1 "True" 0 "False" ;
VAL_ 361 TrcmSrvcRqd_B_Rq 1 "Yes" 0 "No" ;
VAL_ 361 TrnGear_I_MeasMax 255 "Fault" ;
VAL_ 361 TrnActFalt_B_Actl 1 "Yes" 0 "No" ;
VAL_ 361 TrnCapHlth_Actl 3 "Capacitor_OK" 2 "Degraded_Capacitor" 1 "Capacitor_State_Unknown" 0 "Capacitor_Fault" ;
VAL_ 361 TrnPwmFalt_B_Actl 1 "Yes" 0 "No" ;
